VERSION ""

NS_ :

BS_:

BU_: WPC2 PSB SHVU_RR FCS vHS_B2 EMCU SLB GW_APSU GW_DLBCU RCM ARS CGW_CCU vDummy_HS_B GW_RLPSU ATS RLHV SGU PFSU GW_RRPSU ALBCU DSAU SWRC SHVU_FR RCS GW_DPSU BLTN_CAM SCM OHCL RWPC RRHV WPC HOD ASAU

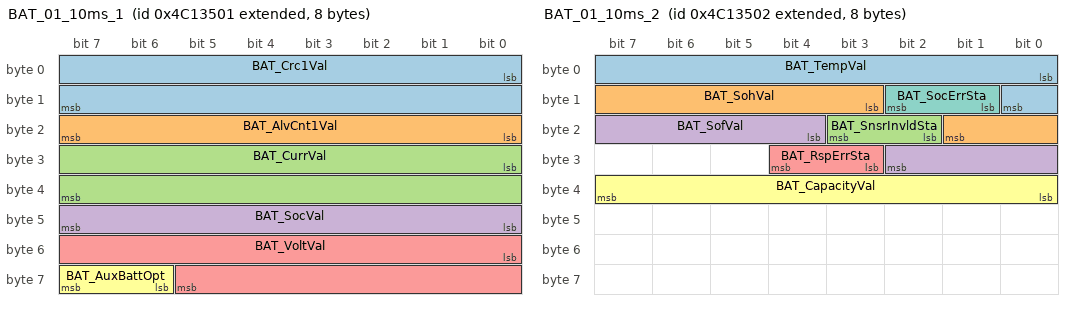
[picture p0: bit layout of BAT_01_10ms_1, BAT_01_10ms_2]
BO_ 2227254529 BAT_01_10ms_1: 8 CGW_CCU
 SG_ BAT_Crc1Val : 0|16@1+ (1,0) [0|0] "" Vector__XXX
 SG_ BAT_AlvCnt1Val : 16|8@1+ (1,0) [0|0] "" Vector__XXX
 SG_ BAT_CurrVal : 24|16@1+ (0.01,-327) [0|0] "A" Vector__XXX
 SG_ BAT_SocVal : 40|8@1+ (1,0) [0|0] "%"  BLTN_CAM
 SG_ BAT_VoltVal : 48|14@1+ (0.001,6) [0|0] "V" Vector__XXX
 SG_ BAT_AuxBattOpt : 62|2@1+ (1,0) [0|0] "" Vector__XXX

BO_ 2227254530 BAT_01_10ms_2: 8 CGW_CCU
 SG_ BAT_TempVal : 0|9@1+ (0.5,-40) [0|0] "¡É" Vector__XXX
 SG_ BAT_SohVal : 11|7@1+ (1,0) [0|0] "%" Vector__XXX
 SG_ BAT_SnsrInvldSta : 18|2@1+ (1,0) [0|0] "" Vector__XXX
 SG_ BAT_SofVal : 20|7@1+ (0.1,0) [0|0] "V" Vector__XXX
 SG_ BAT_RspErrSta : 27|2@1+ (1,0) [0|0] "" Vector__XXX
 SG_ BAT_CapacityVal : 32|8@1+ (1,0) [0|0] "" Vector__XXX
 SG_ BAT_SocErrSta : 9|2@1+ (1,0) [0|0] "" Vector__XXX

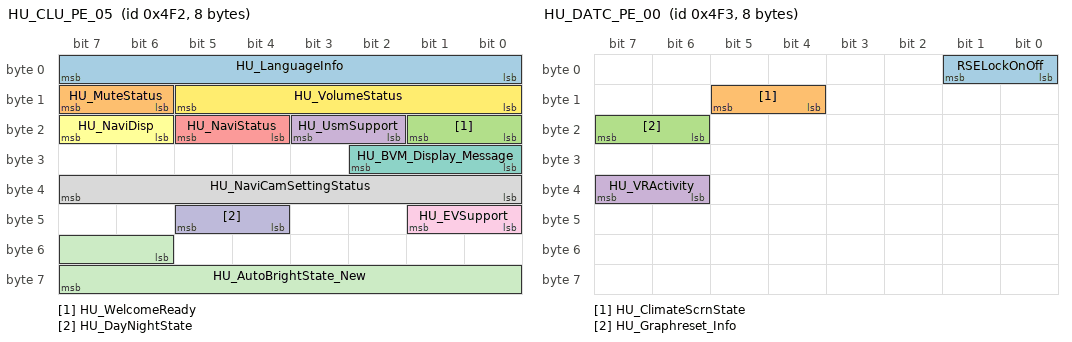
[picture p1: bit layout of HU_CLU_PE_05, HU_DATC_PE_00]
BO_ 1266 HU_CLU_PE_05: 8 CGW_CCU
 SG_ HU_LanguageInfo : 0|8@1+ (1,0) [0|0] ""  ATS,BLTN_CAM
 SG_ HU_MuteStatus : 14|2@1+ (1,0) [0|0] "" Vector__XXX
 SG_ HU_WelcomeReady : 16|2@1+ (1,0) [0|0] "" Vector__XXX
 SG_ HU_UsmSupport : 18|2@1+ (1,0) [0|0] "" Vector__XXX
 SG_ HU_NaviStatus : 20|2@1+ (1,0) [0|0] "" Vector__XXX
 SG_ HU_NaviDisp : 22|2@1+ (1,0) [0|0] "" Vector__XXX
 SG_ HU_BVM_Display_Message : 24|3@1+ (1,0) [0|0] "" Vector__XXX
 SG_ HU_NaviCamSettingStatus : 32|8@1+ (1,0) [0|0] "" Vector__XXX
 SG_ HU_EVSupport : 40|2@1+ (1,0) [0|0] "" Vector__XXX
 SG_ HU_DayNightState : 44|2@1+ (1,0) [0|0] "" Vector__XXX
 SG_ HU_AutoBrightState_New : 54|10@1+ (1,0) [0|0] "" Vector__XXX
 SG_ HU_VolumeStatus : 8|6@1+ (1,0) [0|0] "" Vector__XXX

BO_ 1267 HU_DATC_PE_00: 8 CGW_CCU
 SG_ RSELockOnOff : 0|2@1+ (1,0) [0|0] ""  ARS,ATS,GW_APSU
 SG_ HU_ClimateScrnState : 12|2@1+ (1,0) [0|0] "" Vector__XXX
 SG_ HU_Graphreset_Info : 22|2@1+ (1,0) [0|0] "" Vector__XXX
 SG_ HU_VRActivity : 38|2@1+ (1,0) [0|0] "" Vector__XXX

BO_ 191 RL_SHVU_03_200ms: 8 RLHV
 SG_ RL_SHVU_DTCdisplay : 0|8@1+ (1,0) [0|0] ""  ATS
 SG_ RL_SHVU_DiagMode : 8|2@1+ (1,0) [0|0] ""  ATS

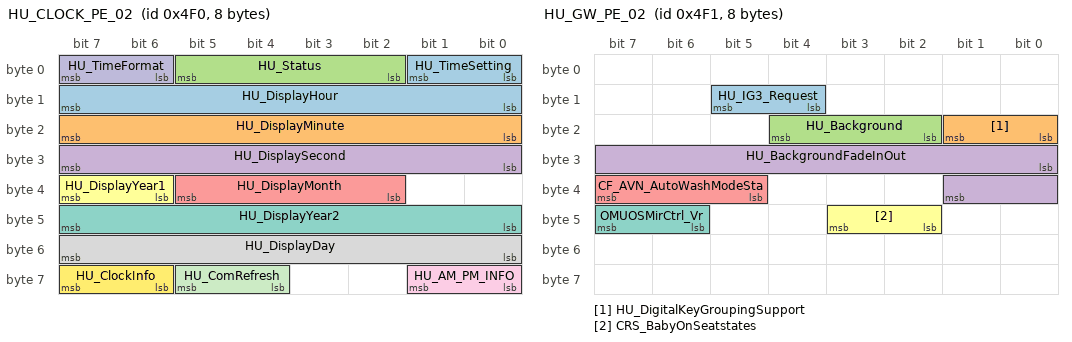
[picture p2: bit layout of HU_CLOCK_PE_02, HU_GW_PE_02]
BO_ 1264 HU_CLOCK_PE_02: 8 CGW_CCU
 SG_ HU_TimeSetting : 0|2@1+ (1,0) [0|0] ""  ATS,BLTN_CAM
 SG_ HU_DisplayMinute : 16|8@1+ (1,0) [0|0] ""  ATS,BLTN_CAM
 SG_ HU_Status : 2|4@1+ (1,0) [0|0] ""  ATS,BLTN_CAM
 SG_ HU_DisplaySecond : 24|8@1+ (1,0) [0|0] ""  ATS,BLTN_CAM
 SG_ HU_DisplayMonth : 34|4@1+ (1,0) [0|0] ""  ATS,BLTN_CAM
 SG_ HU_DisplayYear1 : 38|2@1+ (1,0) [0|0] ""  ATS,BLTN_CAM
 SG_ HU_DisplayYear2 : 40|8@1+ (1,0) [0|0] ""  ATS,BLTN_CAM
 SG_ HU_DisplayDay : 48|8@1+ (1,0) [0|0] ""  ATS,BLTN_CAM
 SG_ HU_AM_PM_INFO : 56|2@1+ (1,0) [0|0] ""  ATS,BLTN_CAM
 SG_ HU_TimeFormat : 6|2@1+ (1,0) [0|0] ""  ATS,BLTN_CAM
 SG_ HU_ComRefresh : 60|2@1+ (1,0) [0|0] ""  ATS,BLTN_CAM
 SG_ HU_ClockInfo : 62|2@1+ (1,0) [0|0] ""  ATS,BLTN_CAM
 SG_ HU_DisplayHour : 8|8@1+ (1,0) [0|0] ""  ATS,BLTN_CAM

BO_ 1265 HU_GW_PE_02: 8 CGW_CCU
 SG_ HU_IG3_Request : 12|2@1+ (1,0) [0|0] "" Vector__XXX
 SG_ HU_DigitalKeyGroupingSupport : 16|2@1+ (1,0) [0|0] "" Vector__XXX
 SG_ HU_Background : 18|3@1+ (1,0) [0|0] ""  ATS,BLTN_CAM
 SG_ HU_BackgroundFadeInOut : 24|10@1+ (0.1,0) [0|0] "%"  ATS,BLTN_CAM
 SG_ CF_AVN_AutoWashModeSta : 37|3@1+ (1,0) [0|0] "" Vector__XXX
 SG_ CRS_BabyOnSeatstates : 42|2@1+ (1,0) [0|0] "" Vector__XXX
 SG_ OMUOSMirCtrl_Vr : 46|2@1+ (1,0) [0|0] "" Vector__XXX

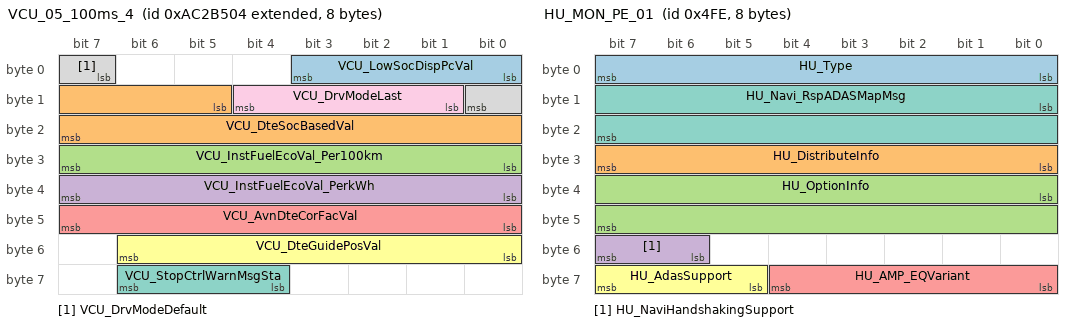
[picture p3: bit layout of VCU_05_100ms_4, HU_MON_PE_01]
BO_ 2328016132 VCU_05_100ms_4: 8 CGW_CCU
 SG_ VCU_LowSocDispPcVal : 0|4@1+ (1,0) [0|0] "" Vector__XXX
 SG_ VCU_DteSocBasedVal : 13|11@1+ (1,0) [0|0] "km" Vector__XXX
 SG_ VCU_InstFuelEcoVal_Per100km : 24|8@1+ (0.5,0) [0|126.5] "kWh/100km" Vector__XXX
 SG_ VCU_InstFuelEcoVal_PerkWh : 32|8@1+ (0.1,0) [0|25.5] "km/kWh" Vector__XXX
 SG_ VCU_AvnDteCorFacVal : 40|8@1+ (0.01,0) [0|0] "" Vector__XXX
 SG_ VCU_DteGuidePosVal : 48|7@1+ (1,-10) [0|0] "%" Vector__XXX
 SG_ VCU_StopCtrlWarnMsgSta : 60|3@1+ (1,0) [0|0] "" Vector__XXX
 SG_ VCU_DrvModeDefault : 7|2@1+ (1,0) [0|0] "" Vector__XXX
 SG_ VCU_DrvModeLast : 9|4@1+ (1,0) [0|0] "" Vector__XXX

BO_ 1278 HU_MON_PE_01: 8 CGW_CCU
 SG_ HU_Type : 0|8@1+ (1,0) [0|0] ""  BLTN_CAM
 SG_ HU_DistributeInfo : 24|8@1+ (1,0) [0|0] ""  BLTN_CAM
 SG_ HU_OptionInfo : 32|16@1+ (1,0) [0|0] ""  BLTN_CAM,RCM
 SG_ HU_NaviHandshakingSupport : 54|2@1+ (1,0) [0|0] "" Vector__XXX
 SG_ HU_AMP_EQVariant : 56|5@1+ (1,0) [0|0] "" Vector__XXX
 SG_ HU_AdasSupport : 61|3@1+ (1,0) [0|0] "" Vector__XXX
 SG_ HU_Navi_RspADASMapMsg : 8|16@1+ (1,0) [0|0] "" Vector__XXX

BO_ 1279 HU_USM_E_10: 8 CGW_CCU
 SG_ USM_SmartRegen_Map_Set : 11|2@1+ (1,0) [0|0] "" Vector__XXX
 SG_ USM_SmartRegen_Sens_Set : 13|3@1+ (1,0) [0|0] "" Vector__XXX
 SG_ AVN_SeatPosMemory_Btn : 16|3@1+ (1,0) [0|0] ""  GW_APSU,GW_DPSU,GW_RLPSU,GW_RRPSU
 SG_ AVN_SeatPosPlyBck_Btn : 19|3@1+ (1,0) [0|0] ""  GW_APSU,GW_DPSU,GW_RLPSU,GW_RRPSU
 SG_ USM_RhstaLvlEnaSetReq : 22|2@1+ (1,0) [0|0] "" Vector__XXX
 SG_ USM_CMSDayBrgtnsLvlLHSetReq : 24|4@1+ (1,0) [0|0] "" Vector__XXX
 SG_ USM_CMSNgtBrgtnsLvlLHSetReq : 28|4@1+ (1,0) [0|0] "" Vector__XXX
 SG_ USM_CMSDayBrgtnsLvlRHSetReq : 32|4@1+ (1,0) [0|0] "" Vector__XXX
 SG_ USM_CMSNgtBrgtnsLvlRHSetReq : 36|4@1+ (1,0) [0|0] "" Vector__XXX
 SG_ USM_CMSBrgtnsReset : 40|2@1+ (1,0) [0|0] "" Vector__XXX
 SG_ USM_TurnDistLnDispSetReq : 42|2@1+ (1,0) [0|0] "" Vector__XXX
 SG_ PCA_FrSd_NValueSet : 44|2@1+ (1,0) [0|0] "" Vector__XXX
 SG_ CF_AVN_1stRrStRmndNValueSet : 46|2@1+ (1,0) [0|0] "" Vector__XXX
 SG_ C_AllDrOpnNValueSet : 52|3@1+ (1,0) [0|0] "" Vector__XXX
 SG_ USM_RpmECOSet : 55|2@1+ (1,0) [0|0] "" Vector__XXX
 SG_ VESS_ChgGuideMdLvl : 57|3@1+ (1,0) [0|0] "" Vector__XXX
 SG_ Usm_RpmSPORTSet : 60|2@1+ (1,0) [0|0] "" Vector__XXX
 SG_ Usm_RpmSPORTPLUSSet : 62|2@1+ (1,0) [0|0] "" Vector__XXX

BO_ 2328016129 VCU_05_100ms_1: 8 CGW_CCU
 SG_ VCU_Crc5Val : 0|16@1+ (1,0) [0|0] "" Vector__XXX
 SG_ VCU_AlvCnt5Val : 16|8@1+ (1,0) [0|0] "" Vector__XXX
 SG_ VCU_EvDrvRdyCluDispSta : 24|2@1+ (1,0) [0|3] ""  SWRC
 SG_ VCU_PwrDnModeSta : 26|2@1+ (1,0) [0|3] "" Vector__XXX
 SG_ VCU_CluWarnMsgSta : 28|4@1+ (1,0) [0|15] "" Vector__XXX
 SG_ VCU_DteOffDispSta : 32|2@1+ (1,0) [0|0] "flag" Vector__XXX
 SG_ VCU_LowSocAlertSta : 34|3@1+ (1,0) [0|7] "" Vector__XXX
 SG_ VCU_VcrmReq : 38|2@1+ (1,0) [0|3] "" Vector__XXX
 SG_ VCU_PdlWarnMsgSta : 40|2@1+ (1,0) [0|3] "" Vector__XXX
 SG_ VCU_AwdDiagDispSta : 42|2@1+ (1,0) [0|0] "" Vector__XXX
 SG_ VCU_AwdLockDispSta : 44|2@1+ (1,0) [0|0] "" Vector__XXX
 SG_ VCU_VirtualApsActSta : 46|2@1+ (1,0) [0|3] "" Vector__XXX
 SG_ VCU_VirtualApsVal : 48|8@1+ (0.3906,0) [0|99.61] "%" Vector__XXX
 SG_ VCU_ServiceLampReq : 56|2@1+ (1,0) [0|3] "" Vector__XXX
 SG_ VCU_ServiceModeSta : 58|2@1+ (1,0) [0|3] "" Vector__XXX
 SG_ VCU_NPosWshModSta : 60|2@1+ (1,0) [0|0] "flag" Vector__XXX
 SG_ VCU_PowerTrainType : 62|2@1+ (1,0) [0|3] "" Vector__XXX

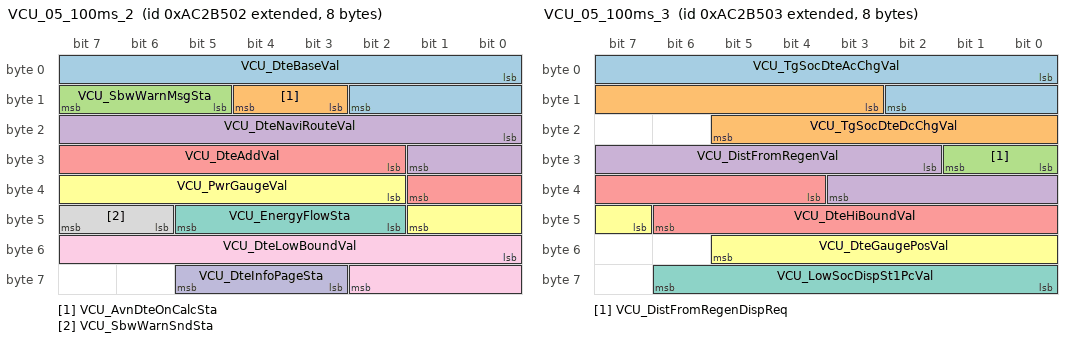
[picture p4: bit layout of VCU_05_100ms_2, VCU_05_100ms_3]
BO_ 2328016130 VCU_05_100ms_2: 8 CGW_CCU
 SG_ VCU_DteBaseVal : 0|11@1+ (1,0) [0|2047] "km" Vector__XXX
 SG_ VCU_AvnDteOnCalcSta : 11|2@1+ (1,0) [0|3] "" Vector__XXX
 SG_ VCU_SbwWarnMsgSta : 13|3@1+ (1,0) [0|0] "flag" Vector__XXX
 SG_ VCU_DteNaviRouteVal : 16|10@1+ (2,0) [0|1026] "km" Vector__XXX
 SG_ VCU_DteAddVal : 26|8@1+ (1,0) [0|255] "km" Vector__XXX
 SG_ VCU_PwrGaugeVal : 34|8@1- (1,0) [-100|100] "%" Vector__XXX
 SG_ VCU_EnergyFlowSta : 42|4@1+ (1,0) [0|15] "" Vector__XXX
 SG_ VCU_SbwWarnSndSta : 46|2@1+ (1,0) [0|0] "flag" Vector__XXX
 SG_ VCU_DteLowBoundVal : 48|11@1+ (1,0) [0|2047] "km" Vector__XXX
 SG_ VCU_DteInfoPageSta : 59|3@1+ (1,0) [0|0] "" Vector__XXX

BO_ 2328016131 VCU_05_100ms_3: 8 CGW_CCU
 SG_ VCU_TgSocDteAcChgVal : 0|11@1+ (1,0) [0|2047] "km" Vector__XXX
 SG_ VCU_TgSocDteDcChgVal : 11|11@1+ (1,0) [0|2047] "km" Vector__XXX
 SG_ VCU_DistFromRegenDispReq : 24|2@1+ (1,0) [0|3] "" Vector__XXX
 SG_ VCU_DistFromRegenVal : 26|10@1+ (10,0) [0|10230] "m" Vector__XXX
 SG_ VCU_DteHiBoundVal : 36|11@1+ (1,0) [0|2047] "km" Vector__XXX
 SG_ VCU_DteGaugePosVal : 47|7@1+ (1,-10) [0|0] "%" Vector__XXX
 SG_ VCU_LowSocDispSt1PcVal : 56|7@1+ (1,0) [0|100] "%" Vector__XXX

BO_ 200 HU_USM_E_12: 8 CGW_CCU
 SG_ CF_AVN_ADrLNValueSet_2 : 0|3@1+ (1,0) [0|0] "" Vector__XXX
 SG_ CF_AVN_FCA_JC_OnOffEquipNvalueSe : 12|2@1+ (1,0) [0|0] "" Vector__XXX
 SG_ CF_AVN_FCA_FrSdOnOffEquipNvalueS : 14|2@1+ (1,0) [0|0] "" Vector__XXX
 SG_ CF_AVN_LKA_OnOffEquip2NvalueSet : 16|2@1+ (1,0) [0|0] "" Vector__XXX
 SG_ CF_AVN_BCA_OnOffEquip2NvalueSet : 18|2@1+ (1,0) [0|0] "" Vector__XXX
 SG_ CF_AVN_BVM_OnOffEquipNvalueSet : 20|2@1+ (1,0) [0|0] "" Vector__XXX
 SG_ CF_AVN_SEA_OnOffEquip3NvalueSet : 22|2@1+ (1,0) [0|0] "" Vector__XXX
 SG_ CF_AVN_BodySpprtSet_AST : 24|2@1+ (1,0) [0|0] ""  ALBCU
 SG_ CF_AVN_SEW_OnOffEquip3NvalueSet : 26|2@1+ (1,0) [0|0] "" Vector__XXX
 SG_ CF_AVN_HudImsAutoSave : 28|2@1+ (1,0) [0|0] "" Vector__XXX
 SG_ USM_PwrDrBuzzerNValueSet : 3|2@1+ (1,0) [0|0] "" Vector__XXX
 SG_ CF_AVN_DWLNValueSet : 30|3@1+ (1,0) [0|0] "" Vector__XXX
 SG_ CF_AVN_AirSptTimeNValueSet_AST : 33|3@1+ (1,0) [0|0] ""  ALBCU
 SG_ CF_AVN_AirSptStrNValue_AST : 36|2@1+ (1,0) [0|0] ""  ALBCU
 SG_ CF_AVN_SeatDrvModNvalueSet_AST : 38|2@1+ (1,0) [0|0] ""  ALBCU
 SG_ CF_AVN_TPMS_TireReplaceNValueSet : 40|3@1+ (1,0) [0|0] "" Vector__XXX
 SG_ CF_AVN_TowModeSet : 43|3@1+ (1,0) [0|0] "" Vector__XXX
 SG_ USM_PwrDrCloseByBraekNValueSet : 46|2@1+ (1,0) [0|0] "" Vector__XXX
 SG_ CF_AVN_ISLANAOffstNvalueSet : 50|3@1+ (1,0) [0|0] "" Vector__XXX
 SG_ CF_Gway_WPC2_NValueSet : 53|2@1+ (1,0) [0|0] ""  WPC,WPC2
 SG_ USM_DrvGhostDoorReq : 56|2@1+ (1,0) [0|0] "" Vector__XXX
 SG_ USM_AstGhostDoorReq : 58|2@1+ (1,0) [0|0] "" Vector__XXX
 SG_ USM_RLGhostDoorReq : 60|2@1+ (1,0) [0|0] "" Vector__XXX
 SG_ USM_RRGhostDoorReq : 62|2@1+ (1,0) [0|0] "" Vector__XXX
 SG_ CF_AVN_FCA_FrOnOffEquipNvalueSet : 7|2@1+ (1,0) [0|0] "" Vector__XXX
 SG_ CF_AVN_FCA_WarnTimeNvalueSet : 9|3@1+ (1,0) [0|0] "" Vector__XXX

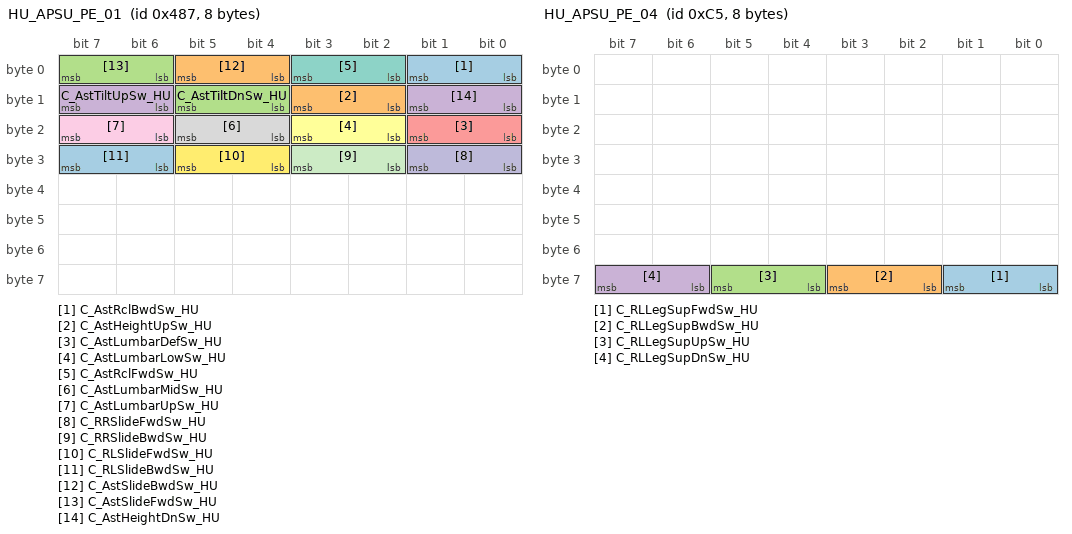
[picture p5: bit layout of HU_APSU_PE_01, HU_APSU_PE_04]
BO_ 1159 HU_APSU_PE_01: 8 CGW_CCU
 SG_ C_AstRclBwdSw_HU : 0|2@1+ (1,0) [0|0] ""  GW_APSU
 SG_ C_AstHeightUpSw_HU : 10|2@1+ (1,0) [0|0] ""  GW_APSU
 SG_ C_AstTiltDnSw_HU : 12|2@1+ (1,0) [0|0] ""  GW_APSU
 SG_ C_AstTiltUpSw_HU : 14|2@1+ (1,0) [0|0] ""  GW_APSU
 SG_ C_AstLumbarDefSw_HU : 16|2@1+ (1,0) [0|0] ""  ALBCU,ASAU,GW_APSU
 SG_ C_AstLumbarLowSw_HU : 18|2@1+ (1,0) [0|0] ""  ALBCU,ASAU,GW_APSU
 SG_ C_AstRclFwdSw_HU : 2|2@1+ (1,0) [0|0] ""  GW_APSU
 SG_ C_AstLumbarMidSw_HU : 20|2@1+ (1,0) [0|0] ""  ALBCU,ASAU,GW_APSU
 SG_ C_AstLumbarUpSw_HU : 22|2@1+ (1,0) [0|0] ""  ALBCU,ASAU,GW_APSU
 SG_ C_RRSlideFwdSw_HU : 24|2@1+ (1,0) [0|0] ""  GW_APSU,GW_RRPSU
 SG_ C_RRSlideBwdSw_HU : 26|2@1+ (1,0) [0|0] ""  GW_APSU,GW_RRPSU
 SG_ C_RLSlideFwdSw_HU : 28|2@1+ (1,0) [0|0] ""  GW_APSU,GW_RLPSU,GW_RRPSU
 SG_ C_RLSlideBwdSw_HU : 30|2@1+ (1,0) [0|0] ""  GW_APSU,GW_RLPSU,GW_RRPSU
 SG_ C_AstSlideBwdSw_HU : 4|2@1+ (1,0) [0|0] ""  GW_APSU
 SG_ C_AstSlideFwdSw_HU : 6|2@1+ (1,0) [0|0] ""  GW_APSU
 SG_ C_AstHeightDnSw_HU : 8|2@1+ (1,0) [0|0] ""  GW_APSU

BO_ 197 HU_APSU_PE_04: 8 CGW_CCU
 SG_ C_RLLegSupFwdSw_HU : 56|2@1+ (1,0) [0|0] ""  GW_APSU,GW_RLPSU
 SG_ C_RLLegSupBwdSw_HU : 58|2@1+ (1,0) [0|0] ""  GW_APSU,GW_RLPSU
 SG_ C_RLLegSupUpSw_HU : 60|2@1+ (1,0) [0|0] ""  GW_APSU,GW_RLPSU
 SG_ C_RLLegSupDnSw_HU : 62|2@1+ (1,0) [0|0] ""  GW_APSU,GW_RLPSU

BO_ 1165 RLMSS_02_500ms: 8 GW_RLPSU
 SG_ RLMSS_OnOffBtn_AVN : 0|2@1+ (1,0) [0|0] ""  CGW_CCU

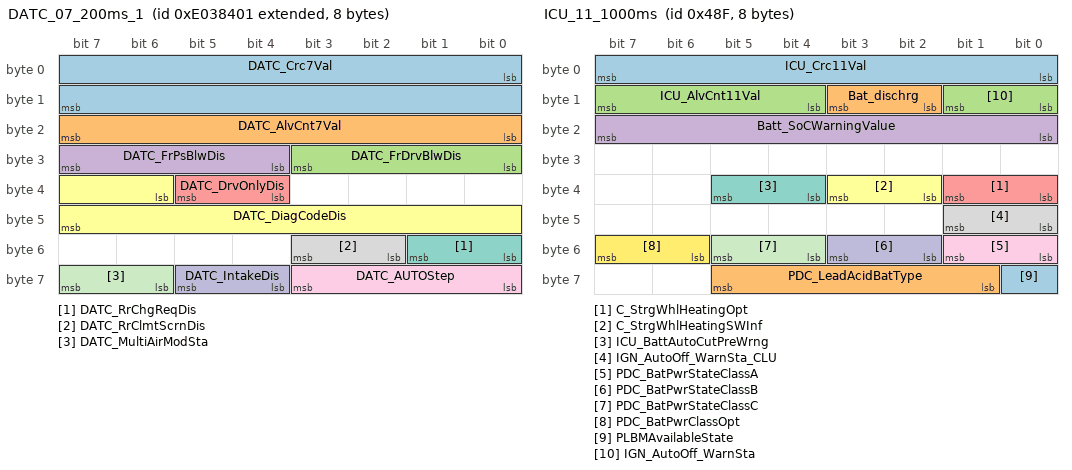
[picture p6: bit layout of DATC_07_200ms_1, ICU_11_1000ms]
BO_ 2382595073 DATC_07_200ms_1: 8 CGW_CCU
 SG_ DATC_Crc7Val : 0|16@1+ (1,0) [0|0] "" Vector__XXX
 SG_ DATC_AlvCnt7Val : 16|8@1+ (1,0) [0|0] "" Vector__XXX
 SG_ DATC_FrDrvBlwDis : 24|4@1+ (1,0) [0|0] ""  ATS
 SG_ DATC_FrPsBlwDis : 28|4@1+ (1,0) [0|0] ""  ATS
 SG_ DATC_DrvOnlyDis : 36|2@1+ (1,0) [0|0] ""  ATS
 SG_ DATC_DiagCodeDis : 38|10@1+ (1,-1) [0|0] "" Vector__XXX
 SG_ DATC_RrChgReqDis : 48|2@1+ (1,0) [0|0] "" Vector__XXX
 SG_ DATC_RrClmtScrnDis : 50|2@1+ (1,0) [0|0] ""  ATS
 SG_ DATC_AUTOStep : 56|4@1+ (1,0) [0|0] ""  ATS
 SG_ DATC_IntakeDis : 60|2@1+ (1,0) [0|0] ""  ATS
 SG_ DATC_MultiAirModSta : 62|2@1+ (1,0) [0|0] "" Vector__XXX

BO_ 1167 ICU_11_1000ms: 8 CGW_CCU
 SG_ ICU_Crc11Val : 0|8@1+ (1,0) [0|0] "" Vector__XXX
 SG_ Bat_dischrg : 10|2@1+ (1,0) [0|0] "" Vector__XXX
 SG_ ICU_AlvCnt11Val : 12|4@1+ (1,0) [0|0] "" Vector__XXX
 SG_ Batt_SoCWarningValue : 16|8@1+ (1,0) [0|0] "%" Vector__XXX
 SG_ C_StrgWhlHeatingOpt : 32|2@1+ (1,0) [0|0] "" Vector__XXX
 SG_ C_StrgWhlHeatingSWInf : 34|2@1+ (1,0) [0|0] "" Vector__XXX
 SG_ ICU_BattAutoCutPreWrng : 36|2@1+ (1,0) [0|0] ""  BLTN_CAM
 SG_ IGN_AutoOff_WarnSta_CLU : 40|2@1+ (1,0) [0|0] "" Vector__XXX
 SG_ PDC_BatPwrStateClassA : 48|2@1+ (1,0) [0|0] "" Vector__XXX
 SG_ PDC_BatPwrStateClassB : 50|2@1+ (1,0) [0|0] "" Vector__XXX
 SG_ PDC_BatPwrStateClassC : 52|2@1+ (1,0) [0|0] "" Vector__XXX
 SG_ PDC_BatPwrClassOpt : 54|2@1+ (1,0) [0|0] "" Vector__XXX
 SG_ PLBMAvailableState : 56|1@1+ (1,0) [0|0] "" Vector__XXX
 SG_ PDC_LeadAcidBatType : 57|5@1+ (1,0) [0|0] "" Vector__XXX
 SG_ IGN_AutoOff_WarnSta : 8|2@1+ (1,0) [0|0] "" Vector__XXX

BO_ 194 HU_USM_E_16: 8 CGW_CCU
 SG_ CF_LDW_OnOffEquip2NvalueSet : 0|2@1+ (1,0) [0|0] "" Vector__XXX
 SG_ CF_AVN_TrnkTlgtAutoWashModeSet : 12|2@1+ (1,0) [0|0] "" Vector__XXX
 SG_ CF_AVN_DrvArmRestHeatNValueSet : 14|2@1+ (1,0) [0|0] ""  FCS
 SG_ CF_AVN_AstArmRestHeatNValueSet : 16|2@1+ (1,0) [0|0] ""  FCS
 SG_ CF_AVN_RRArmRestHeatNValueSet : 18|2@1+ (1,0) [0|0] ""  FCS
 SG_ AVN_HudContentsADAS : 2|2@1+ (1,0) [0|0] "" Vector__XXX
 SG_ CF_AVN_RLArmRestHeatNValueSet : 20|2@1+ (1,0) [0|0] ""  FCS
 SG_ CF_AVN_AirSptStrNValue_VR : 22|2@1+ (1,0) [0|0] ""  GW_DLBCU
 SG_ CF_AVN_AirSptTimeNValueSet_VR : 24|3@1+ (1,0) [0|0] ""  GW_DLBCU
 SG_ CF_AVN_AirSptMode_VR : 27|3@1+ (1,0) [0|0] ""  GW_DLBCU
 SG_ CF_AVN_MdLmpSpeechRecogNValueSet : 30|3@1+ (1,0) [0|0] "" Vector__XXX
 SG_ AVN_HudContentsBCWUnderADAS : 4|2@1+ (1,0) [0|0] "" Vector__XXX
 SG_ CF_AVN_ISLA2NvalueSet : 41|3@1+ (1,0) [0|0] "" Vector__XXX
 SG_ C_TeleRRMsgOpCmdIBOX_0 : 44|2@1+ (1,0) [0|0] ""  GW_RRPSU
 SG_ C_TeleRLMsgOpCmdIBOX_0 : 46|2@1+ (1,0) [0|0] ""  GW_RLPSU
 SG_ USM_AdasISLANACntryTglSet : 48|2@1+ (1,0) [0|0] "" Vector__XXX
 SG_ USM_AdasISLANACntry1Set : 50|4@1+ (1,0) [0|0] "" Vector__XXX
 SG_ CF_AVN_PMPDNvalueSet : 54|2@1+ (1,0) [0|0] "" Vector__XXX
 SG_ CF_AVN_LKAWrngVolNvalueSet_2 : 56|2@1+ (1,0) [0|0] "" Vector__XXX
 SG_ CF_AVN_ActbolstersenNValue : 58|3@1+ (1,0) [0|0] ""  GW_DLBCU

BO_ 1166 RRMSS_02_500ms: 8 GW_RRPSU
 SG_ RRMSS_OnOffBtn_AVN : 0|2@1+ (1,0) [0|0] ""  CGW_CCU

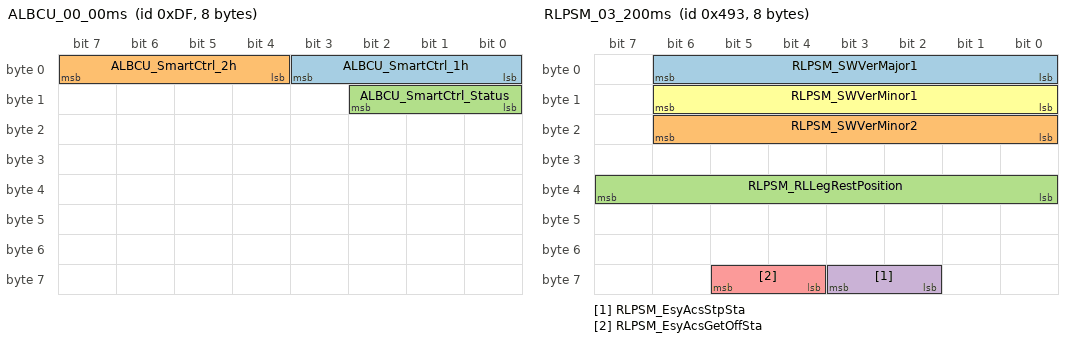
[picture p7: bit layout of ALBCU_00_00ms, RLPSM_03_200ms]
BO_ 223 ALBCU_00_00ms: 8 ALBCU
 SG_ ALBCU_SmartCtrl_1h : 0|4@1+ (1,0) [0|0] ""  CGW_CCU
 SG_ ALBCU_SmartCtrl_2h : 4|4@1+ (1,0) [0|0] ""  CGW_CCU
 SG_ ALBCU_SmartCtrl_Status : 8|3@1+ (1,0) [0|0] ""  CGW_CCU

BO_ 1171 RLPSM_03_200ms: 8 GW_RLPSU
 SG_ RLPSM_SWVerMajor1 : 0|7@1+ (1,0) [0|0] "" Vector__XXX
 SG_ RLPSM_SWVerMinor2 : 16|7@1+ (1,0) [0|0] "" Vector__XXX
 SG_ RLPSM_RLLegRestPosition : 32|8@1+ (1,0) [0|0] ""  GW_APSU,GW_DPSU
 SG_ RLPSM_EsyAcsStpSta : 58|2@1+ (1,0) [0|0] ""  GW_DLBCU
 SG_ RLPSM_EsyAcsGetOffSta : 60|2@1+ (1,0) [0|0] ""  GW_DLBCU
 SG_ RLPSM_SWVerMinor1 : 8|7@1+ (1,0) [0|0] "" Vector__XXX

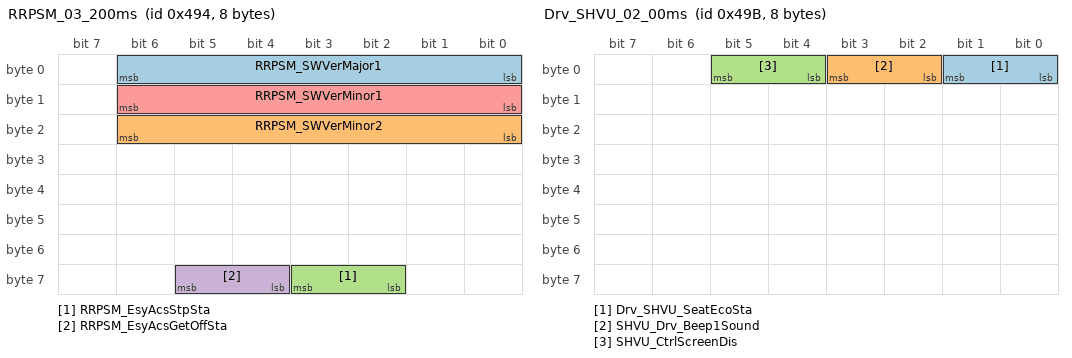
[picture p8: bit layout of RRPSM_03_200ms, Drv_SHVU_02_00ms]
BO_ 1172 RRPSM_03_200ms: 8 GW_RRPSU
 SG_ RRPSM_SWVerMajor1 : 0|7@1+ (1,0) [0|0] "" Vector__XXX
 SG_ RRPSM_SWVerMinor2 : 16|7@1+ (1,0) [0|0] "" Vector__XXX
 SG_ RRPSM_EsyAcsStpSta : 58|2@1+ (1,0) [0|0] ""  GW_DLBCU
 SG_ RRPSM_EsyAcsGetOffSta : 60|2@1+ (1,0) [0|0] ""  GW_DLBCU
 SG_ RRPSM_SWVerMinor1 : 8|7@1+ (1,0) [0|0] "" Vector__XXX

BO_ 1174 Drv_SHVU_01_200ms: 8 GW_APSU
 SG_ Drv_SHVU_SeatOptSta : 0|3@1+ (1,0) [0|0] ""  CGW_CCU,FCS
 SG_ Drv_SHVU_HtSwHiIndSta : 14|2@1+ (1,0) [0|0] ""  CGW_CCU,FCS
 SG_ Drv_SHVU_HtSwMidIndSta : 16|2@1+ (1,0) [0|0] ""  CGW_CCU,FCS
 SG_ Drv_SHVU_HtSwLowIndSta : 18|2@1+ (1,0) [0|0] ""  CGW_CCU,FCS
 SG_ Drv_SHVU_VntSwHiIndSta : 20|2@1+ (1,0) [0|0] ""  CGW_CCU,FCS
 SG_ Drv_SHVU_VntSwMidIndSta : 22|2@1+ (1,0) [0|0] ""  CGW_CCU,FCS
 SG_ Drv_SHVU_VntSwLowIndSta : 24|2@1+ (1,0) [0|0] ""  CGW_CCU,FCS
 SG_ Drv_SHVU_HtBlcUSMSta : 28|4@1+ (1,0) [0|0] ""  CGW_CCU
 SG_ Drv_SHVU_SeatHtOperSta : 3|4@1+ (1,0) [0|0] ""  CGW_CCU,FCS
 SG_ Drv_SHVU_LastModeOptSta : 40|2@1+ (1,0) [0|0] ""  CGW_CCU
 SG_ Drv_SHVU_HtSwHiIndSta_RHD : 46|2@1+ (1,0) [0|0] ""  CGW_CCU,FCS
 SG_ Drv_SHVU_HtSwMidIndSta_RHD : 48|2@1+ (1,0) [0|0] ""  CGW_CCU,FCS
 SG_ Drv_SHVU_HtSwLowIndSta_RHD : 50|2@1+ (1,0) [0|0] ""  CGW_CCU,FCS
 SG_ Drv_SHVU_VntSwHiIndSta_RHD : 52|2@1+ (1,0) [0|0] ""  CGW_CCU,FCS
 SG_ Drv_SHVU_VntSwMidIndSta_RHD : 54|2@1+ (1,0) [0|0] ""  CGW_CCU,FCS
 SG_ Drv_SHVU_VntSwLowIndSta_RHD : 56|2@1+ (1,0) [0|0] ""  CGW_CCU,FCS
 SG_ Drv_SHVU_HtBlcUSMSta_RHD : 60|4@1+ (1,0) [0|0] "" Vector__XXX

BO_ 1179 Drv_SHVU_02_00ms: 8 SHVU_FR
 SG_ Drv_SHVU_SeatEcoSta : 0|2@1+ (1,0) [0|0] ""  CGW_CCU
 SG_ SHVU_Drv_Beep1Sound : 2|2@1+ (1,0) [0|0] ""  CGW_CCU
 SG_ SHVU_CtrlScreenDis : 4|2@1+ (1,0) [0|0] ""  CGW_CCU

BO_ 1180 Ast_SHVU_02_00ms: 8 SHVU_FR
 SG_ SHVU_Ast_Beep1Sound : 2|2@1+ (1,0) [0|0] ""  CGW_CCU
 SG_ Ast_SHVU_SeatEcoSta : 26|2@1+ (1,0) [0|0] ""  CGW_CCU

BO_ 208 RR_SHVU_03_200ms: 8 RRHV
 SG_ RR_SHVU_DTCdisplay : 0|8@1+ (1,0) [0|0] ""  ATS
 SG_ RR_SHVU_DiagMode : 8|2@1+ (1,0) [0|0] ""  ATS

BO_ 1181 RL_SHVU_02_00ms: 8 SHVU_FR
 SG_ RL_SHVU_SeatEcoSta : 0|2@1+ (1,0) [0|0] ""  ATS,CGW_CCU,vHS_B2

BO_ 1182 RR_SHVU_02_00ms: 8 SHVU_RR
 SG_ RR_SHVU_SeatEcoSta : 0|2@1+ (1,0) [0|0] ""  ATS,CGW_CCU,vHS_B2

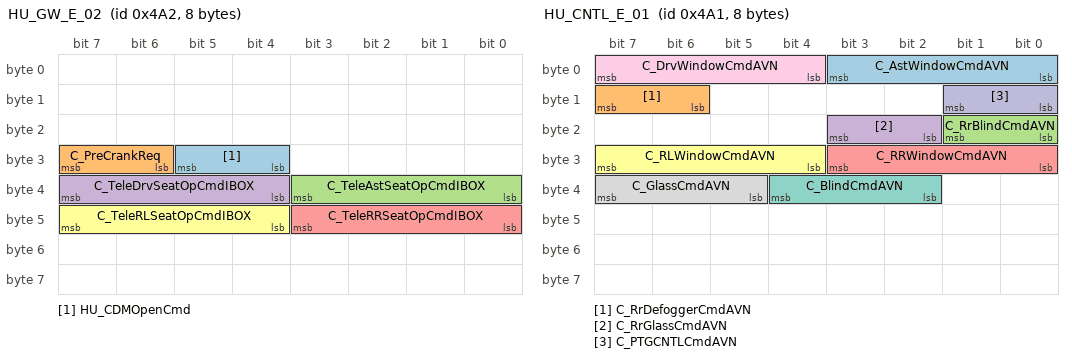
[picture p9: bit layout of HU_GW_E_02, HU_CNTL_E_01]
BO_ 1186 HU_GW_E_02: 8 CGW_CCU
 SG_ HU_CDMOpenCmd : 28|2@1+ (1,0) [0|0] "" Vector__XXX
 SG_ C_PreCrankReq : 30|2@1+ (1,0) [0|0] ""  BLTN_CAM
 SG_ C_TeleAstSeatOpCmdIBOX : 32|4@1+ (1,0) [0|0] ""  GW_APSU,SHVU_FR
 SG_ C_TeleDrvSeatOpCmdIBOX : 36|4@1+ (1,0) [0|0] ""  GW_APSU,GW_DPSU,SHVU_FR
 SG_ C_TeleRRSeatOpCmdIBOX : 40|4@1+ (1,0) [0|0] ""  ATS,GW_RRPSU,RRHV,SHVU_FR,SHVU_RR
 SG_ C_TeleRLSeatOpCmdIBOX : 44|4@1+ (1,0) [0|0] ""  ATS,GW_RLPSU,RLHV,SHVU_FR,SHVU_RR

BO_ 1185 HU_CNTL_E_01: 8 CGW_CCU
 SG_ C_AstWindowCmdAVN : 0|4@1+ (1,0) [0|0] "" Vector__XXX
 SG_ C_RrDefoggerCmdAVN : 14|2@1+ (1,0) [0|0] "" Vector__XXX
 SG_ C_RrBlindCmdAVN : 16|2@1+ (1,0) [0|0] ""  RCM
 SG_ C_RrGlassCmdAVN : 18|2@1+ (1,0) [0|0] ""  RCM
 SG_ C_RRWindowCmdAVN : 24|4@1+ (1,0) [0|0] "" Vector__XXX
 SG_ C_RLWindowCmdAVN : 28|4@1+ (1,0) [0|0] "" Vector__XXX
 SG_ C_BlindCmdAVN : 34|3@1+ (1,0) [0|0] ""  RCM
 SG_ C_GlassCmdAVN : 37|3@1+ (1,0) [0|0] ""  RCM
 SG_ C_DrvWindowCmdAVN : 4|4@1+ (1,0) [0|0] "" Vector__XXX
 SG_ C_PTGCNTLCmdAVN : 8|2@1+ (1,0) [0|0] "" Vector__XXX

BO_TX_BU_ 191 : RLHV,SHVU_FR,SHVU_RR;
BO_TX_BU_ 1174 : GW_APSU,GW_DPSU,SHVU_FR;
BO_TX_BU_ 1179 : SHVU_FR,GW_APSU;
BO_TX_BU_ 208 : RRHV,SHVU_FR,SHVU_RR;
BO_TX_BU_ 1181 : SHVU_FR,SHVU_RR,RLHV,GW_RLPSU;
BO_TX_BU_ 1182 : SHVU_RR,RRHV,GW_RRPSU,SHVU_FR;
CM_ BO_ 2227254529 "[P] Periodic";
CM_ SG_ 2227254529 BAT_Crc1Val "BAT_CyclicRedundancyCheck1Value";
CM_ SG_ 2227254529 BAT_AlvCnt1Val "BAT_AliveCounter1Value";
CM_ SG_ 2227254529 BAT_CurrVal "BAT_CurrentValue";
CM_ SG_ 2227254529 BAT_SocVal "BAT_StateOfChargeValue";
CM_ SG_ 2227254529 BAT_VoltVal "BAT_VoltageValue";
CM_ SG_ 2227254529 BAT_AuxBattOpt "12V Battery Option Value(LFP 12V Battery)";
CM_ BO_ 2227254530 "[P] Periodic";
CM_ SG_ 2227254530 BAT_TempVal "BAT_TemperatureValue";
CM_ SG_ 2227254530 BAT_SohVal "BAT_StateOfHealthValue";
CM_ SG_ 2227254530 BAT_SnsrInvldSta "BAT_SensorInvalidStatus";
CM_ SG_ 2227254530 BAT_SofVal "BAT_StateOfFunctionValue";
CM_ SG_ 2227254530 BAT_RspErrSta "BAT_ResponseErrorStatus";
CM_ SG_ 2227254530 BAT_CapacityVal "12V Battery Capacity Value";
CM_ SG_ 2227254530 BAT_SocErrSta "BAT_SoCErrorStatus";
CM_ BO_ 1266 "[PE] Periodic and On Event";
CM_ SG_ 1266 HU_LanguageInfo "Information for System Language (for Display Font)";
CM_ SG_ 1266 HU_MuteStatus "Information for System Mute Display";
CM_ SG_ 1266 HU_WelcomeReady "H/U playback ready signal to play welcome/goodbye animation video.";
CM_ SG_ 1266 HU_UsmSupport "Information whether HU can support USM or not";
CM_ SG_ 1266 HU_NaviStatus "Information for Navigation Status (Booting, Normal Operation, No SD card)
-AVN NAVI Transmission Signal";
CM_ SG_ 1266 HU_NaviDisp "Information for Navi Display status on Front Monitor";
CM_ SG_ 1266 HU_BVM_Display_Message "BVM Operation Message";
CM_ SG_ 1266 HU_NaviCamSettingStatus "Information for Navi Camera alert setting status

+ Bit-coded field (On 1, Off 0)
   - bit 0 : Fixed Camera
   - bit 1 : Signal/Speed Violation Camera
   - bit 2 : Movable Camera
   - bit 3 : User Registration Fixed Camera
   - bit 4 : User Registration Signal/Speed Violation Camera
   - bit 5~6 : RESERVED
-AVN NAVI Transmission Signal";
CM_ SG_ 1266 HU_EVSupport "Notification whether EV function support or not.";
CM_ SG_ 1266 HU_AutoBrightState_New "HU Display Brightness State(When automatically adjusted)";
CM_ SG_ 1266 HU_VolumeStatus "Information for AVN Volume";
CM_ BO_ 1267 "[PE] Periodic and On Event";
CM_ SG_ 1267 RSELockOnOff "Command for RSE Lock Requst from Head Unit";
CM_ SG_ 1267 HU_ClimateScrnState "AVNT Climate screen state";
CM_ SG_ 1267 HU_Graphreset_Info "Command for Hybrid Vehicle Fuel Economy Graph Reset Information
-Transmitting to Cluster when drivers agree 'Graph Reset'
-Keep the Value of Avergae Fuel Consumption and Line on the Graph";
CM_ SG_ 1267 HU_VRActivity "Information for Acitivity of VR (For All area)";
CM_ BO_ 191 "[PE] Periodic and On Event";
CM_ SG_ 191 RL_SHVU_DTCdisplay "0x00: DTC is not exist(Fail is not exist)/0x01:IGN2 Fuse Open Detection/0x02:Switch Input Detection at Same Time/0x03:NTC/Heating wire Open Detection/0x04:NTC+/NTC- Terminal Short Detection/0x05:NTC+/Heater+ Terminal Short Detection/0x06:NTC+/Heater-, Heater+/Heater-, Heater+/NTC- Terminal Short Detection/0x07:NTC+/Heater- Wiring Short Detection/0x08:NTC+/Heater-, Heater+/Heater-, Heater+/NTC- Wiring Short Detection/0x09:Target Temperature Dissatisfied/0x0A:Blower+/Blower- Short, Blower+/Blower Speed, Blower-/Blower Speed Wiring Short Detection/0x0B:Blower+/Blower RPM, Blower-/Blower RPM, Blower Speed/Blower RPM Short Detection/0x0C:Blower+, Blower-, Blower Speed Signal open Detection/0x0D:Blower RPM signal Open Detection/0x0E~0xFD:Unused/0xFE:No Display/0xFF:Invalid";
CM_ SG_ 191 RL_SHVU_DiagMode "0x0:Default/0x1:DTC Mode/0x2:Normal Mode/0x3:Invalid";
CM_ BO_ 1264 "[PE] Periodic and On Event";
CM_ SG_ 1264 HU_TimeSetting "Information for current time setting";
CM_ SG_ 1264 HU_DisplayMinute "Information for time display in Minute unit";
CM_ SG_ 1264 HU_Status "Information for H/U status
Transmitted on H/U status changing";
CM_ SG_ 1264 HU_DisplaySecond "Information for time display in Second unit";
CM_ SG_ 1264 HU_DisplayMonth "Information for Month";
CM_ SG_ 1264 HU_DisplayYear1 "Information for Year (XXOO)
XX : HU_DisplayYear1
OO: HU_DisplayYear2";
CM_ SG_ 1264 HU_DisplayYear2 "Information for Year (XXOO)
XX : HU_DisplayYear1
OO: HU_DisplayYear2";
CM_ SG_ 1264 HU_DisplayDay "Information for Day";
CM_ SG_ 1264 HU_AM_PM_INFO "Information for AM/PM";
CM_ SG_ 1264 HU_TimeFormat "Information for time format
Digital CLOCK only";
CM_ SG_ 1264 HU_DisplayHour "Information for time display in Hour unit";
CM_ BO_ 1265 "[PE] Periodic and On Event";
CM_ SG_ 1265 HU_IG3_Request "IG3 wake up and sleep request for EV/PHEV";
CM_ SG_ 1265 HU_DigitalKeyGroupingSupport "Digital Key Grouping Support";
CM_ SG_ 1265 HU_Background "HU Backgound image info";
CM_ SG_ 1265 HU_BackgroundFadeInOut "HU Background Fade in/out info - (HEX * Factor) %";
CM_ SG_ 1265 CRS_BabyOnSeatstates "The status of baby left in the car";
CM_ SG_ 1265 OMUOSMirCtrl_Vr "This signal is for the OutSide Mirror Control (Fold or Unfold)";
CM_ BO_ 2328016132 "[P] Periodic";
CM_ SG_ 2328016132 VCU_LowSocDispPcVal "VCU_LowSocDisplayPercentValue";
CM_ SG_ 2328016132 VCU_DteSocBasedVal "VCU_DteSocBasedValue";
CM_ SG_ 2328016132 VCU_InstFuelEcoVal_Per100km "VCU_InstantFuelEconomy(kWh/100km) ##2G##VCU - VCU5 - CR_Vcu_FuelEco_KP100km";
CM_ SG_ 2328016132 VCU_InstFuelEcoVal_PerkWh "VCU_InstantFuelEconomyValue_(km/kWh) ##2G##VCU - VCU5 - CR_Vcu_FuelEco_KPK";
CM_ SG_ 2328016132 VCU_AvnDteCorFacVal "AVN DTE Correlation Factor Value";
CM_ SG_ 2328016132 VCU_DteGuidePosVal "DTE Guide Position Value";
CM_ SG_ 2328016132 VCU_StopCtrlWarnMsgSta "i-Pedal Warning Message Status";
CM_ SG_ 2328016132 VCU_DrvModeDefault "Drive Mode(Default Mode) Value for Cluster Display(EV)";
CM_ SG_ 2328016132 VCU_DrvModeLast "This signal is the drive mode that needs to maintain on restart";
CM_ BO_ 1278 "[PE] Periodic and On Event";
CM_ SG_ 1278 HU_Type "Information for H/U Platform type
- Integrated AVN 1.0 use different value depends on development company (Mobis:0x68/LG:0x70)
- Integrated AVN 1.0 Mobis is developed based on Display Audio
- Integrated AVN 1.0 LG is developed based on Compact AVN

Information for China OPIO Platform
- 0xFC: China OPIO w/o CLU interface (most of phase1)
- 0xFD: China OPIO w/CLU interface (parts of phase1, phase2)

Information for Audio Platform Type
- 0x43 : Audio 4.0 Value";
CM_ SG_ 1278 HU_DistributeInfo "Region :Europe/North America/
Vehicle Type : RHD/LHD
Positionning information";
CM_ SG_ 1278 HU_OptionInfo "Information of H/U functions";
CM_ SG_ 1278 HU_NaviHandshakingSupport "This is a signal to send whether handshaking logic is applied related to Navigation's 'Map based ADAS' specification";
CM_ SG_ 1278 HU_AMP_EQVariant "Set EQ Variant for various vehicle cases.
During the AMP initializing process, This signal should be sent before AMP unmute.
This signal is only needed for models that have variant EQ for vehicle types. (Hatchback, Wagon, Hybrid etc..)
Models that doesn¡¯t have variant EQ for vehicle types shouldn¡¯t have this signal.";
CM_ SG_ 1278 HU_AdasSupport "Information about ADAS support
-Classify between General Map and Precise Map Transmission Function
-AVN System Transmission Signal";
CM_ SG_ 1278 HU_Navi_RspADASMapMsg "HU_ResponseADASMapMessage";
CM_ BO_ 1279 "[EC] On Event and On Change";
CM_ SG_ 1279 USM_SmartRegen_Map_Set "Smart Regeneration 2.0 Map information USM User set signal";
CM_ SG_ 1279 USM_SmartRegen_Sens_Set "Smart Regeneration User Personality of Reduction Set Signal";
CM_ SG_ 1279 AVN_SeatPosMemory_Btn "Seat position save signal";
CM_ SG_ 1279 AVN_SeatPosPlyBck_Btn "Seat position move signal";
CM_ SG_ 1279 USM_CMSBrgtnsReset "CMS Brightness Reset (LH/RH)";
CM_ SG_ 1279 CF_AVN_1stRrStRmndNValueSet "This signal is for setting the ROA function when IBU control ROA Function.";
CM_ SG_ 1279 VESS_ChgGuideMdLvl "Releated to VESS Alarm Sound Level";
CM_ BO_ 2328016129 "[P] Periodic";
CM_ SG_ 2328016129 VCU_Crc5Val "VCU_CyclicRedundancyCheck5Value";
CM_ SG_ 2328016129 VCU_AlvCnt5Val "VCU_AliveCounter5Value";
CM_ SG_ 2328016129 VCU_EvDrvRdyCluDispSta "VCU_EvDriveReadyClusterDisplayStatus ##2G##VCU - VCU1 - CF_Vcu_EvRdyClu";
CM_ SG_ 2328016129 VCU_PwrDnModeSta "VCU_PowerDownModeStatus ##2G##VCU - VCU5 - CF_Vcu_PwrDnMode";
CM_ SG_ 2328016129 VCU_CluWarnMsgSta "VCU_ClusterWarningMessageStatus ##2G##VCU - VCU7 - CF_Vcu_WarnMsg";
CM_ SG_ 2328016129 VCU_DteOffDispSta "VCU_DteOffDisplayStatus ##2G##VCU - VCU5 - CF_Vcu_DteOff";
CM_ SG_ 2328016129 VCU_LowSocAlertSta "VCU_LowSocAlertStatus ##2G##VCU - VCU3 - CF_Vcu_LowSocAlert";
CM_ SG_ 2328016129 VCU_VcrmReq "VCU_VcrmRequest ##2G##VCU - VCU3 - CF_Vcu_Vcrm_Req";
CM_ SG_ 2328016129 VCU_PdlWarnMsgSta "VCU_PaddleWarningMassageStatus";
CM_ SG_ 2328016129 VCU_AwdDiagDispSta "VCU_AwdDiagnosisDisplayStatus";
CM_ SG_ 2328016129 VCU_AwdLockDispSta "VCU_AwdLockDisplayStatus";
CM_ SG_ 2328016129 VCU_VirtualApsActSta "VCU_VirtualApsActivatedStatus ##2G##VCU - VCU1 - CF_Vcu_EstApsSel";
CM_ SG_ 2328016129 VCU_VirtualApsVal "VCU_VirtualApsValue ##2G##VCU - VCU1 - CR_Vcu_EstAccPed_PC";
CM_ SG_ 2328016129 VCU_ServiceLampReq "VCU_SeviceLampRequest ##2G##VCU - VCU5 - CF_Vcu_SerLamp";
CM_ SG_ 2328016129 VCU_ServiceModeSta "VCU_ServiceModeStatus ##2G##VCU - VCU2 - CF_Vcu_ServiceMod";
CM_ SG_ 2328016129 VCU_NPosWshModSta "VCU_NPositionWashModeStatus";
CM_ SG_ 2328016129 VCU_PowerTrainType "VCU_PowerTrainType";
CM_ BO_ 2328016130 "[P] Periodic";
CM_ SG_ 2328016130 VCU_DteBaseVal "VCU_DteBaseValue ##2G##VCU - VCU1 - CR_Vcu_DistEmpty_km(VCU6 - CR_Vcu_DistEmpty_km)";
CM_ SG_ 2328016130 VCU_AvnDteOnCalcSta "VCU_AvnDteOnCalculationStatus ##2G##VCU - VCU1 - CF_Vcu_AvnDteCalc(VCU6 - CF_Vcu_AvnDteCalc)";
CM_ SG_ 2328016130 VCU_SbwWarnMsgSta "VCU_SbwWarningMessageStatus ##2G##VCU - VCU20 - CF_Vcu_SbwWarnMsg";
CM_ SG_ 2328016130 VCU_DteNaviRouteVal "VCU_DteNaviRouteValue ##2G##VCU - VCU3 - CR_Vcu_DistEmptyAvn_km";
CM_ SG_ 2328016130 VCU_DteAddVal "VCU_DteAddedValue ##2G##VCU - VCU1 - CR_Vcu_DistEmptyAdd_km(VCU6 - CR_Vcu_DistEmptyAdd_km)";
CM_ SG_ 2328016130 VCU_PwrGaugeVal "VCU_PowerGaugeValue ##2G##VCU - VCU5 - CR_Vcu_TqMotClu_Pc";
CM_ SG_ 2328016130 VCU_EnergyFlowSta "VCU_EnergyFlowStatus ##2G##VCU - VCU5 - CF_Vcu_EvMod";
CM_ SG_ 2328016130 VCU_SbwWarnSndSta "VCU_SbwWarningSoundStatus ##2G##VCU - VCU20 - CF_Vcu_SbwWarnSnd";
CM_ SG_ 2328016130 VCU_DteLowBoundVal "DTE Low Boundary Value";
CM_ SG_ 2328016130 VCU_DteInfoPageSta "DTE Information Page State";
CM_ BO_ 2328016131 "[P] Periodic";
CM_ SG_ 2328016131 VCU_TgSocDteAcChgVal "VCU_TargetSocDte(Sc/Ac)ChargerValue ##2G##VCU - VCU19 - CR_Vcu_TgSocDte_AcChg";
CM_ SG_ 2328016131 VCU_TgSocDteDcChgVal "VCU_TargetSocDte(Qc/Dc)ChargerValue ##2G##VCU - VCU19 - CR_Vcu_TgSocDte_DcChg";
CM_ SG_ 2328016131 VCU_DistFromRegenDispReq "VCU_DistanceFromRegenerationDisplayRequest ##2G##VCU - VCU7 - CR_Vcu_RegenRangeAddSet";
CM_ SG_ 2328016131 VCU_DistFromRegenVal "VCU_DistanceFromRegenerationValue ##2G##VCU - VCU7 - CR_Vcu_RegenRangeAdd";
CM_ SG_ 2328016131 VCU_DteHiBoundVal "DTE High Boundary Value";
CM_ SG_ 2328016131 VCU_DteGaugePosVal "DTE Gauge Position Value";
CM_ SG_ 2328016131 VCU_LowSocDispSt1PcVal "VCU_LowSocDispState1PcVal (0~100%)";
CM_ BO_ 200 "[EC] On Event and On Change";
CM_ SG_ 200 CF_AVN_BodySpprtSet_AST "This signal is for the Ergo-Motion seat (AST) body support (Smart Posture Assist) USM";
CM_ SG_ 200 CF_AVN_AirSptTimeNValueSet_AST "This signal is for the Ergo-Motion seat (AST) massage function time setting";
CM_ SG_ 200 CF_AVN_AirSptStrNValue_AST "This signal is for the ERGO seat (AST) massage intensity USM";
CM_ SG_ 200 CF_AVN_SeatDrvModNvalueSet_AST "This signal is for the Ergo-Motion seat (AST) smart support (Smart Support) USM";
CM_ BO_ 1159 "[PE] Periodic and On Event";
CM_ SG_ 1159 C_AstRclBwdSw_HU "Assistant seat Moving control :Recline Backward";
CM_ SG_ 1159 C_AstHeightUpSw_HU "Assistant seat Moving control : Height Up";
CM_ SG_ 1159 C_AstTiltDnSw_HU "Assistant seat Moving control : Tilt Down";
CM_ SG_ 1159 C_AstTiltUpSw_HU "Assistant seat Moving Switch : Tilt Up";
CM_ SG_ 1159 C_AstLumbarDefSw_HU "Assistant seat moving switch: Deflate";
CM_ SG_ 1159 C_AstLumbarLowSw_HU "Assistant seat moving switch:Lumbar Low";
CM_ SG_ 1159 C_AstRclFwdSw_HU "Assistant seat Moving Switch : Recline Forward";
CM_ SG_ 1159 C_AstLumbarMidSw_HU "Assistant seat Moving control : Lumbar Mid";
CM_ SG_ 1159 C_AstLumbarUpSw_HU "Assistant seat Moving control : Lumbar Up";
CM_ SG_ 1159 C_RRSlideFwdSw_HU "2nd Right side seat Moving control :Power Slide Forward";
CM_ SG_ 1159 C_RRSlideBwdSw_HU "2nd Right side seat Moving control :Power Slide Backward";
CM_ SG_ 1159 C_RLSlideFwdSw_HU "2nd Left side seat Moving control :Power Slide Forward";
CM_ SG_ 1159 C_RLSlideBwdSw_HU "2nd Left side seat Moving control :Power Slide Backward";
CM_ SG_ 1159 C_AstSlideBwdSw_HU "Assistant seat moving switch : Slide Backward";
CM_ SG_ 1159 C_AstSlideFwdSw_HU "Assistant seat Moving switch : Slide Forward";
CM_ SG_ 1159 C_AstHeightDnSw_HU "Assistant seat Moving control : Height Down";
CM_ BO_ 197 "[PE] Periodic and On Event";
CM_ SG_ 197 C_RLLegSupFwdSw_HU "2nd Left side seat Moving control : Leg Support Forward";
CM_ SG_ 197 C_RLLegSupBwdSw_HU "2nd Left side seat Moving control : Leg Support Backward";
CM_ SG_ 197 C_RLLegSupUpSw_HU "2nd Left side seat Moving control : Leg Support Up";
CM_ SG_ 197 C_RLLegSupDnSw_HU "2nd Left side seat Moving control : Leg Support Down";
CM_ BO_ 1165 "[PE] Periodic and On Event";
CM_ SG_ 1165 RLMSS_OnOffBtn_AVN "Massage Switch Power On Off Signal to AVN";
CM_ BO_ 2382595073 "[PE] Periodic and On Event";
CM_ SG_ 2382595073 DATC_Crc7Val "DATC_CyclicRedundancyCheck7Value";
CM_ SG_ 2382595073 DATC_AlvCnt7Val "DATC_AliveCounter7Value";
CM_ SG_ 2382595073 DATC_FrDrvBlwDis "DATC_FrontDriverBlowerDisplay";
CM_ SG_ 2382595073 DATC_FrPsBlwDis "DATC_FrontPassengerBlowerDisplay";
CM_ SG_ 2382595073 DATC_DrvOnlyDis "DATC_DriverOnlyDisplay";
CM_ SG_ 2382595073 DATC_DiagCodeDis "DATC_DiagnosisCodeDisplay";
CM_ SG_ 2382595073 DATC_RrChgReqDis "DATC_RearChangeRequestDisplay";
CM_ SG_ 2382595073 DATC_RrClmtScrnDis "DATC_RearClimateScreenDisplay";
CM_ SG_ 2382595073 DATC_AUTOStep "This signal indicates AUTO step status in case Multi Auto Blower type.";
CM_ SG_ 2382595073 DATC_IntakeDis "This signal indicates intake indicator & display";
CM_ SG_ 2382595073 DATC_MultiAirModSta "This signal indicates MultiAirModeStatus";
CM_ BO_ 1167 "[PE] Periodic and On Event";
CM_ SG_ 1167 ICU_Crc11Val "ICU_CyclicRedundancyCheck11Value";
CM_ SG_ 1167 Bat_dischrg "Battery discharge notification flag #2G# Bat_dischrg";
CM_ SG_ 1167 ICU_AlvCnt11Val "ICU_AliveCounter11Value";
CM_ SG_ 1167 Batt_SoCWarningValue "Value of SoC warning level. ##2G## -  - Batt_SoCWarningValue";
CM_ SG_ 1167 ICU_BattAutoCutPreWrng "This is a warning signal before blocking the dark current of the ICU by the battery SOC.";
CM_ SG_ 1167 IGN_AutoOff_WarnSta_CLU "this signal is defined as the warning signal related with battery discharge";
CM_ SG_ 1167 PDC_BatPwrStateClassA "Vehicle Low-Voltage Power State Class A";
CM_ SG_ 1167 PDC_BatPwrStateClassB "Vehicle Low-Voltage Power State Class  B";
CM_ SG_ 1167 PDC_BatPwrStateClassC "Vehicle Low-Voltage Power State Class  C";
CM_ SG_ 1167 PDC_LeadAcidBatType "Lead Acid Battery Type Information";
CM_ SG_ 1167 IGN_AutoOff_WarnSta "this signal is defined as the warning signal related with battery discharge";
CM_ BO_ 194 "[EC] On Event and On Change";
CM_ SG_ 194 CF_AVN_AirSptStrNValue_VR "This signal is for the seat massage intensity VR";
CM_ SG_ 194 CF_AVN_AirSptTimeNValueSet_VR "This signal is for the seat massage function time setting by VR";
CM_ SG_ 194 CF_AVN_AirSptMode_VR "This signal is for the seat massage function mode setting by VR";
CM_ SG_ 194 CF_AVN_MdLmpSpeechRecogNValueSet "Signal of mood lamp position when VR is started";
CM_ SG_ 194 C_TeleRRMsgOpCmdIBOX_0 "Seat massage System RR On/Off";
CM_ SG_ 194 C_TeleRLMsgOpCmdIBOX_0 "Seat Massage System RL On/Off";
CM_ BO_ 1166 "[PE] Periodic and On Event";
CM_ SG_ 1166 RRMSS_OnOffBtn_AVN "Massage Switch Power On Off Signal to AVN";
CM_ BO_ 223 "[EC] On Event and On Change";
CM_ SG_ 223 ALBCU_SmartCtrl_1h "Smart Posture Adjust 1hr";
CM_ SG_ 223 ALBCU_SmartCtrl_2h "Smart Posture Adjust AVN Display (2hr)";
CM_ SG_ 223 ALBCU_SmartCtrl_Status "Smart Posture Adjust 2nd Interlocked Move AVN popup request";
CM_ BO_ 1171 "[PE] Periodic and On Event";
CM_ SG_ 1171 RLPSM_SWVerMajor1 "First Word(ASCII) in RLPSM S/W Ver";
CM_ SG_ 1171 RLPSM_SWVerMinor2 "Third Word(ASCII) in RLPSM S/W Ver";
CM_ SG_ 1171 RLPSM_EsyAcsStpSta "EasyAccessStop from RLPSM to DLBCU";
CM_ SG_ 1171 RLPSM_EsyAcsGetOffSta "EasyAccessGetOff from RLPSM to DLBCU";
CM_ SG_ 1171 RLPSM_SWVerMinor1 "Second Word(ASCII) in RLPSM S/W Ver";
CM_ BO_ 1172 "[PE] Periodic and On Event";
CM_ SG_ 1172 RRPSM_SWVerMajor1 "First Word(ASCII) in RRPSM S/W Ver";
CM_ SG_ 1172 RRPSM_SWVerMinor2 "Third Word(ASCII) in RRPSM S/W Ver";
CM_ SG_ 1172 RRPSM_EsyAcsStpSta "EasyAccessStop from RRPSM to DLBCU";
CM_ SG_ 1172 RRPSM_EsyAcsGetOffSta "EasyAccessGetOff from RRPSM to DLBCU";
CM_ SG_ 1172 RRPSM_SWVerMinor1 "Second Word(ASCII) in RRPSM S/W Ver";
CM_ BO_ 1174 "[PE] Periodic and On Event";
CM_ SG_ 1174 Drv_SHVU_SeatOptSta "Drv Seat Heater/Vent option info";
CM_ SG_ 1174 Drv_SHVU_HtSwHiIndSta "Drv Seat Heater Switch High Indicator Status";
CM_ SG_ 1174 Drv_SHVU_HtSwMidIndSta "Drv Seat Heater Switch Mid Indicator Status";
CM_ SG_ 1174 Drv_SHVU_HtSwLowIndSta "Drv Seat Heater Switch Low Indicator Status";
CM_ SG_ 1174 Drv_SHVU_VntSwHiIndSta "Drv Seat Vent Switch High Indicator Status";
CM_ SG_ 1174 Drv_SHVU_VntSwMidIndSta "Drv Seat Vent Switch Mid Indicator Status";
CM_ SG_ 1174 Drv_SHVU_VntSwLowIndSta "Drv Seat Vent Switch Low Indicator Status";
CM_ SG_ 1174 Drv_SHVU_HtBlcUSMSta "Hetaer Balance Driver USM R vaule";
CM_ SG_ 1174 Drv_SHVU_SeatHtOperSta "Drv Seat Heater/Vent current operation state";
CM_ SG_ 1174 Drv_SHVU_LastModeOptSta "Drv Seat Heat/Vent Last Mode Option State";
CM_ SG_ 1174 Drv_SHVU_HtSwHiIndSta_RHD "Drv Seat Heater Switch High Indicator Status(RHD)";
CM_ SG_ 1174 Drv_SHVU_HtSwMidIndSta_RHD "Drv Seat Heater Switch Mid Indicator Status(RHD)";
CM_ SG_ 1174 Drv_SHVU_HtSwLowIndSta_RHD "Drv Seat Heater Switch Low Indicator Status(RHD)";
CM_ SG_ 1174 Drv_SHVU_VntSwHiIndSta_RHD "Drv Seat Vent Switch High Indicator Status(RHD)";
CM_ SG_ 1174 Drv_SHVU_VntSwMidIndSta_RHD "Drv Seat Vent Switch Mid Indicator Status(RHD)";
CM_ SG_ 1174 Drv_SHVU_VntSwLowIndSta_RHD "Drv Seat Vent Switch Low Indicator Status(RHD)";
CM_ SG_ 1174 Drv_SHVU_HtBlcUSMSta_RHD "Hetaer Balance Driver USM R vaule(RHD)";
CM_ BO_ 1179 "[EC] On Event and On Change";
CM_ SG_ 1179 Drv_SHVU_SeatEcoSta "Driver Seat Eco+ Mode Status";
CM_ SG_ 1179 SHVU_Drv_Beep1Sound "SHVU_FR Driver's Seat Heater or Ventilation Switch input Beep Request";
CM_ SG_ 1179 SHVU_CtrlScreenDis "Request AVN screen change for controlling Seat Heater or Ventilation";
CM_ BO_ 1180 "[EC] On Event and On Change";
CM_ SG_ 1180 SHVU_Ast_Beep1Sound "SHVU_FR Assistant's Seat Heater or Ventilation Switch input Beep Request";
CM_ SG_ 1180 Ast_SHVU_SeatEcoSta "Assistant (Passenger) Seat Eco+ Mode Status";
CM_ BO_ 208 "[PE] Periodic and On Event";
CM_ SG_ 208 RR_SHVU_DTCdisplay "0x00: DTC is not exist(Fail is not exist)/0x01:IGN2 Fuse Open Detection/0x02:Switch Input Detection at Same Time/0x03:NTC/Heating wire Open Detection/0x04:NTC+/NTC- Terminal Short Detection/0x05:NTC+/Heater+ Terminal Short Detection/0x06:NTC+/Heater-, Heater+/Heater-, Heater+/NTC- Terminal Short Detection/0x07:NTC+/Heater- Wiring Short Detection/0x08:NTC+/Heater-, Heater+/Heater-, Heater+/NTC- Wiring Short Detection/0x09:Target Temperature Dissatisfied/0x0A:Blower+/Blower- Short, Blower+/Blower Speed, Blower-/Blower Speed Wiring Short Detection/0x0B:Blower+/Blower RPM, Blower-/Blower RPM, Blower Speed/Blower RPM Short Detection/0x0C:Blower+, Blower-, Blower Speed Signal open Detection/0x0D:Blower RPM signal Open Detection/0x0E~0xFD:Unused/0xFE:No Display/0xFF:Invalid";
CM_ SG_ 208 RR_SHVU_DiagMode "0x0:Default/0x1:DTC Mode/0x2:Normal Mode/0x3:Invalid";
CM_ BO_ 1181 "[EC] On Event and On Change";
CM_ SG_ 1181 RL_SHVU_SeatEcoSta "Rear LH Seat Eco+ Mode Status";
CM_ BO_ 1182 "[EC] On Event and On Change";
CM_ SG_ 1182 RR_SHVU_SeatEcoSta "Rear RH Seat Eco+ Mode Status";
CM_ BO_ 1186 "[EC] On Event and On Change";
CM_ SG_ 1186 HU_CDMOpenCmd "Command for CDM open/close";
CM_ SG_ 1186 C_PreCrankReq "Command for B-CAN wake up signal
(Need to send this signal before other remote commands)";
CM_ SG_ 1186 C_TeleAstSeatOpCmdIBOX "Command for Remote Seat Heat/Vent control (Passenger)";
CM_ SG_ 1186 C_TeleDrvSeatOpCmdIBOX "Command for Remote Seat Heat/Vent control (Driver)";
CM_ SG_ 1186 C_TeleRRSeatOpCmdIBOX "Command for Remote Seat Heat/Vent control (Rear Right)";
CM_ SG_ 1186 C_TeleRLSeatOpCmdIBOX "Command for Remote Seat Heat/Vent control (Rear Left)";
CM_ BO_ 1185 "[EC] On Event and On Change";
CM_ SG_ 1185 C_AstWindowCmdAVN "This signal indicates AST Window Open/Close Command";
CM_ SG_ 1185 C_RrDefoggerCmdAVN "This signal indicates Rear Defogger Button Command";
CM_ SG_ 1185 C_RRWindowCmdAVN "This signal indicates RR Window Open/Close Command";
CM_ SG_ 1185 C_RLWindowCmdAVN "This signal indicates RL Window Open/Close Command";
CM_ SG_ 1185 C_BlindCmdAVN "This signal indicates Sunroof Blind Open/Close Command";
CM_ SG_ 1185 C_GlassCmdAVN "This signal indicates Sunroof Glass Open/Close Command";
CM_ SG_ 1185 C_DrvWindowCmdAVN "This signal indicates DRV Window Open/Close Command";
CM_ SG_ 1185 C_PTGCNTLCmdAVN "This signal indicates PowerTailgate Open/Close  Command";
BA_DEF_ BO_  "DiagState" ENUM  "No","Yes";
BA_DEF_ BO_  "DiagResponse" ENUM  "No","Yes";
BA_DEF_ BO_  "DiagRequest" ENUM  "No","Yes";
BA_DEF_ BO_  "TpMessage" ENUM  "No","Yes";
BA_DEF_ BO_  "UsrMsgIDSforwardDeviation" INT 0 100;
BA_DEF_ BO_  "UsrMsgIDSbackwardDeviation" INT 50 1000;
BA_DEF_ BO_  "GenMsgCycleTime" INT 0 2000;
BA_DEF_ BO_  "GenMsgStartDelayTime" INT 0 2000;
BA_DEF_ BO_  "GenMsgSendType" ENUM  "Cyclic","NoMsgSendType";
BA_DEF_ BO_  "GenMsgCycleTimeFast" INT 0 500;
BA_DEF_ BO_  "GenMsgDelayTime" INT 0 20;
BA_DEF_ BO_  "GenMsgILSupport" ENUM  "No","Yes";
BA_DEF_ BO_  "GenMsgNrOfRepetition" INT 0 3;
BA_DEF_ BO_  "NmMessage" ENUM  "No","Yes";
BA_DEF_ BO_  "NWM-Botschaft" ENUM  "No","Yes";
BA_DEF_ BO_  "TpTxIndex" INT 0 65535;
BA_DEF_ BO_  "VFrameFormat" ENUM  "StandardCAN","ExtendedCAN","reserved","reserved","reserved","reserved","reserved","reserved","reserved","reserved","reserved","reserved","reserved","reserved","StandardCAN_FD","ExtendedCAN_FD";
BA_DEF_ SG_  "UserSigValidity" ENUM  "B+","ACC","IG","IG1","IG2","IG3","IG1 or IG2","IG1 or IG3","Undef";
BA_DEF_ SG_  "TimeoutValue" STRING ;
BA_DEF_ SG_  "UsrSigPurpose" ENUM  "Undef","FN","DIAG","DIAG(Req)","DIAG(Res)","DIAG(Phy)","DEV","CCP(Req)","CCP(Res)","NM","TP";
BA_DEF_ SG_  "GenSigStartValue" INT 0 1215752192;
BA_DEF_ SG_  "NetworkRequest" ENUM  "Yes","No";
BA_DEF_ SG_  "NetworkRequestHoldingTime" INT 0 65535;
BA_DEF_ SG_  "Description" STRING ;
BA_DEF_ SG_  "Version" STRING ;
BA_DEF_ SG_  "GenSigEnvVarType" ENUM  "Int","Float","Undef";
BA_DEF_ SG_  "GenSigSendType" ENUM  "Cyclic","OnWrite","OnWriteWithRepetition","OnChange","OnChangeWithRepetition","IfActive","IfActiveWithRepetition","NoSigSendType","OnChangeAndIfActive","OnChangeAndIfActiveWithRepetition";
BA_DEF_ SG_  "GwSigLatencyTime" INT 0 65536;
BA_DEF_ SG_  "GwSigMissingSourceType" ENUM  "Undef","OldValue","DefaultValue","InitialValue";
BA_DEF_ SG_  "NWM-WakeupAllowed" ENUM  "<n.a.>";
BA_DEF_ SG_  "RoutingFactor" INT 1 1215752192;
BA_DEF_ SG_  "SystemSignalLongSymbol" STRING ;
BA_DEF_REL_ BU_SG_REL_  "GenSigTimeoutTime" INT 0 7000;
BA_DEF_DEF_  "DiagState" "No";
BA_DEF_DEF_  "DiagResponse" "No";
BA_DEF_DEF_  "DiagRequest" "No";
BA_DEF_DEF_  "TpMessage" "No";
BA_DEF_DEF_  "UsrMsgIDSforwardDeviation" 10;
BA_DEF_DEF_  "UsrMsgIDSbackwardDeviation" 100;
BA_DEF_DEF_  "GenMsgCycleTime" 200;
BA_DEF_DEF_  "GenMsgStartDelayTime" 0;
BA_DEF_DEF_  "GenMsgSendType" "NoMsgSendType";
BA_DEF_DEF_  "GenMsgCycleTimeFast" 40;
BA_DEF_DEF_  "GenMsgDelayTime" 20;
BA_DEF_DEF_  "GenMsgILSupport" "Yes";
BA_DEF_DEF_  "GenMsgNrOfRepetition" 3;
BA_DEF_DEF_  "NmMessage" "No";
BA_DEF_DEF_  "NWM-Botschaft" "No";
BA_DEF_DEF_  "TpTxIndex" 0;
BA_DEF_DEF_  "VFrameFormat" "StandardCAN";
BA_DEF_DEF_  "UserSigValidity" "IG";
BA_DEF_DEF_  "TimeoutValue" "";
BA_DEF_DEF_  "UsrSigPurpose" "FN";
BA_DEF_DEF_  "GenSigStartValue" 0;
BA_DEF_DEF_  "NetworkRequest" "No";
BA_DEF_DEF_  "NetworkRequestHoldingTime" 0;
BA_DEF_DEF_  "Description" "";
BA_DEF_DEF_  "Version" "";
BA_DEF_DEF_  "GenSigEnvVarType" "Undef";
BA_DEF_DEF_  "GenSigSendType" "NoSigSendType";
BA_DEF_DEF_  "GwSigLatencyTime" 40;
BA_DEF_DEF_  "GwSigMissingSourceType" "Undef";
BA_DEF_DEF_  "NWM-WakeupAllowed" "<n.a.>";
BA_DEF_DEF_  "RoutingFactor" 1;
BA_DEF_DEF_REL_ "GenSigTimeoutTime" 500;
BA_DEF_DEF_  "SystemSignalLongSymbol" "";
BA_ "VFrameFormat" BO_ 2227254529 1;
BA_ "GenMsgNrOfRepetition" BO_ 2227254529 0;
BA_ "GenMsgCycleTimeFast" BO_ 2227254529 0;
BA_ "GenMsgCycleTime" BO_ 2227254529 50;
BA_ "GenMsgSendType" BO_ 2227254529 0;
BA_ "VFrameFormat" BO_ 2227254530 1;
BA_ "GenMsgNrOfRepetition" BO_ 2227254530 0;
BA_ "GenMsgCycleTimeFast" BO_ 2227254530 0;
BA_ "GenMsgCycleTime" BO_ 2227254530 50;
BA_ "GenMsgSendType" BO_ 2227254530 0;
BA_ "GenMsgCycleTime" BO_ 1266 1000;
BA_ "GenMsgSendType" BO_ 1266 0;
BA_ "GenMsgCycleTime" BO_ 1267 1000;
BA_ "GenMsgSendType" BO_ 1267 0;
BA_ "GenMsgSendType" BO_ 191 0;
BA_ "GenMsgCycleTime" BO_ 1264 1000;
BA_ "GenMsgSendType" BO_ 1264 0;
BA_ "GenMsgCycleTime" BO_ 1265 1000;
BA_ "GenMsgSendType" BO_ 1265 0;
BA_ "VFrameFormat" BO_ 2328016132 1;
BA_ "GenMsgNrOfRepetition" BO_ 2328016132 0;
BA_ "GenMsgCycleTimeFast" BO_ 2328016132 0;
BA_ "GenMsgSendType" BO_ 2328016132 0;
BA_ "GenMsgCycleTime" BO_ 1278 2000;
BA_ "GenMsgSendType" BO_ 1278 0;
BA_ "GenMsgCycleTime" BO_ 1279 0;
BA_ "VFrameFormat" BO_ 2328016129 1;
BA_ "GenMsgNrOfRepetition" BO_ 2328016129 0;
BA_ "GenMsgCycleTimeFast" BO_ 2328016129 0;
BA_ "GenMsgSendType" BO_ 2328016129 0;
BA_ "VFrameFormat" BO_ 2328016130 1;
BA_ "GenMsgNrOfRepetition" BO_ 2328016130 0;
BA_ "GenMsgCycleTimeFast" BO_ 2328016130 0;
BA_ "GenMsgSendType" BO_ 2328016130 0;
BA_ "VFrameFormat" BO_ 2328016131 1;
BA_ "GenMsgNrOfRepetition" BO_ 2328016131 0;
BA_ "GenMsgCycleTimeFast" BO_ 2328016131 0;
BA_ "GenMsgSendType" BO_ 2328016131 0;
BA_ "GenMsgCycleTime" BO_ 200 0;
BA_ "GenMsgStartDelayTime" BO_ 1159 90;
BA_ "GenMsgSendType" BO_ 1159 0;
BA_ "GenMsgSendType" BO_ 197 0;
BA_ "GenMsgCycleTime" BO_ 1165 500;
BA_ "GenMsgSendType" BO_ 1165 0;
BA_ "VFrameFormat" BO_ 2382595073 1;
BA_ "GenMsgSendType" BO_ 2382595073 0;
BA_ "GenMsgCycleTime" BO_ 1167 1000;
BA_ "GenMsgSendType" BO_ 1167 0;
BA_ "GenMsgCycleTime" BO_ 194 0;
BA_ "GenMsgCycleTime" BO_ 1166 500;
BA_ "GenMsgSendType" BO_ 1166 0;
BA_ "GenMsgCycleTime" BO_ 223 0;
BA_ "GenMsgSendType" BO_ 1171 0;
BA_ "GenMsgSendType" BO_ 1172 0;
BA_ "GenMsgSendType" BO_ 1174 0;
BA_ "GenMsgCycleTime" BO_ 1179 0;
BA_ "GenMsgCycleTime" BO_ 1180 0;
BA_ "GenMsgSendType" BO_ 208 0;
BA_ "GenMsgCycleTime" BO_ 1181 0;
BA_ "GenMsgCycleTime" BO_ 1182 0;
BA_ "GenMsgCycleTime" BO_ 1186 0;
BA_ "GenMsgCycleTime" BO_ 1185 0;
BA_ "Version" SG_ 2227254529 BAT_Crc1Val "21.09.03";
BA_ "RoutingFactor" SG_ 2227254529 BAT_Crc1Val 5;
BA_ "UserSigValidity" SG_ 2227254529 BAT_Crc1Val 7;
BA_ "GenSigStartValue" SG_ 2227254529 BAT_Crc1Val 65535;
BA_ "Description" SG_ 2227254529 BAT_Crc1Val "The data area for CRC calculation is based on the data length (DLC) of the message DB.

The CRC shall be calculated over the entire data block (excluding the CRC bytes) including the user data, alive counter and Data ID



- CRC Polynomial (0x1021) , Ini";
BA_ "Version" SG_ 2227254529 BAT_AlvCnt1Val "21.09.03";
BA_ "RoutingFactor" SG_ 2227254529 BAT_AlvCnt1Val 5;
BA_ "UserSigValidity" SG_ 2227254529 BAT_AlvCnt1Val 7;
BA_ "Description" SG_ 2227254529 BAT_AlvCnt1Val "For the first transmission request for a data element the counter shall be initialized with 0 and shall be incremented by 1 for every subsequent send request. 

When the counter reaches the maximum value(0xFF), then it shall restart with 0 for the next s";
BA_ "Version" SG_ 2227254529 BAT_CurrVal "17.11.00";
BA_ "RoutingFactor" SG_ 2227254529 BAT_CurrVal 5;
BA_ "UserSigValidity" SG_ 2227254529 BAT_CurrVal 7;
BA_ "GenSigStartValue" SG_ 2227254529 BAT_CurrVal 65535;
BA_ "Description" SG_ 2227254529 BAT_CurrVal "[For 12V Lithium Battery vehicle model]

This is Battery current as measured by battery sensor.

This value is  

   - IRANGE : 1 (medium current)

   - Resolution : 10mA";
BA_ "Version" SG_ 2227254529 BAT_SocVal "19.01.00";
BA_ "RoutingFactor" SG_ 2227254529 BAT_SocVal 5;
BA_ "UserSigValidity" SG_ 2227254529 BAT_SocVal 7;
BA_ "Description" SG_ 2227254529 BAT_SocVal "[For 12V Lithium Battery vehicle model]

This signal is battery State of Charge as calculated by battery sensor.";
BA_ "Version" SG_ 2227254529 BAT_VoltVal "17.11.00";
BA_ "RoutingFactor" SG_ 2227254529 BAT_VoltVal 5;
BA_ "UserSigValidity" SG_ 2227254529 BAT_VoltVal 7;
BA_ "GenSigStartValue" SG_ 2227254529 BAT_VoltVal 16383;
BA_ "Description" SG_ 2227254529 BAT_VoltVal "[For 12V Lithium Battery vehicle model]

This is the actual battery voltage as measured on the battery pole by battery sensor.

The Resolution is 1mV.";
BA_ "Version" SG_ 2227254529 BAT_AuxBattOpt "21.10.05";
BA_ "RoutingFactor" SG_ 2227254529 BAT_AuxBattOpt 5;
BA_ "UserSigValidity" SG_ 2227254529 BAT_AuxBattOpt 7;
BA_ "Description" SG_ 2227254529 BAT_AuxBattOpt "12V Battery Option Value(LFP 12V Battery)";
BA_ "Version" SG_ 2227254530 BAT_TempVal "20.03.05";
BA_ "RoutingFactor" SG_ 2227254530 BAT_TempVal 5;
BA_ "UserSigValidity" SG_ 2227254530 BAT_TempVal 7;
BA_ "GenSigStartValue" SG_ 2227254530 BAT_TempVal 511;
BA_ "Description" SG_ 2227254530 BAT_TempVal "This is actual battery electrolyte temperature value by battery sensor.

The value is calculated by a Battery Temperature Model, depending on measured temperature of the battery pole.

The resolution is 0.5¡É.";
BA_ "Version" SG_ 2227254530 BAT_SohVal "17.11.00";
BA_ "RoutingFactor" SG_ 2227254530 BAT_SohVal 5;
BA_ "UserSigValidity" SG_ 2227254530 BAT_SohVal 7;
BA_ "GenSigStartValue" SG_ 2227254530 BAT_SohVal 127;
BA_ "Description" SG_ 2227254530 BAT_SohVal "[For 12V Lithium Battery vehicle model]

This signal is battery State of Health(SOH) as calculated by battery sensor.

This value shows reduction rate of nominal capacity.

This value can be used for diagnosis information of application system.";
BA_ "Version" SG_ 2227254530 BAT_SnsrInvldSta "17.11.00";
BA_ "RoutingFactor" SG_ 2227254530 BAT_SnsrInvldSta 5;
BA_ "UserSigValidity" SG_ 2227254530 BAT_SnsrInvldSta 7;
BA_ "GenSigStartValue" SG_ 2227254530 BAT_SnsrInvldSta 1;
BA_ "Description" SG_ 2227254530 BAT_SnsrInvldSta "[For 12V Lithium Battery vehicle model]

This bit is Battery Sensor Invalid flag and setting condition is depending on Battery Sensor self diagnosis information.

 BS Invalid = 0 : BS is Valid Condition

 BS Invalid = 1 : BS is Invalid Condition";
BA_ "Version" SG_ 2227254530 BAT_SofVal "17.11.00";
BA_ "RoutingFactor" SG_ 2227254530 BAT_SofVal 5;
BA_ "UserSigValidity" SG_ 2227254530 BAT_SofVal 7;
BA_ "GenSigStartValue" SG_ 2227254530 BAT_SofVal 127;
BA_ "Description" SG_ 2227254530 BAT_SofVal "[For 12V Lithium Battery vehicle model]

This signal is battery State of Function(SOF) as calculated by battery sensor.

This value shows information about the battery ability to crank the engine (both of warm & cold cranking).

This value is prediction ";
BA_ "Version" SG_ 2227254530 BAT_RspErrSta "17.11.00";
BA_ "RoutingFactor" SG_ 2227254530 BAT_RspErrSta 5;
BA_ "UserSigValidity" SG_ 2227254530 BAT_RspErrSta 7;
BA_ "GenSigStartValue" SG_ 2227254530 BAT_RspErrSta 1;
BA_ "Description" SG_ 2227254530 BAT_RspErrSta "[For 12V Lithium Battery vehicle model]

Battery Sensor shall send one status bit signal, Response_Error. Response_Error shall be set whenever a frame received by the node or a frame transmitted by the node contains an error in the response field.

Respo";
BA_ "Version" SG_ 2227254530 BAT_CapacityVal "21.07.06";
BA_ "RoutingFactor" SG_ 2227254530 BAT_CapacityVal 5;
BA_ "UserSigValidity" SG_ 2227254530 BAT_CapacityVal 7;
BA_ "Description" SG_ 2227254530 BAT_CapacityVal "12V Battery Capacity Value";
BA_ "Version" SG_ 2227254530 BAT_SocErrSta "19.01.00";
BA_ "RoutingFactor" SG_ 2227254530 BAT_SocErrSta 5;
BA_ "UserSigValidity" SG_ 2227254530 BAT_SocErrSta 7;
BA_ "GenSigStartValue" SG_ 2227254530 BAT_SocErrSta 1;
BA_ "Description" SG_ 2227254530 BAT_SocErrSta "[For 12V Lithium Battery vehicle model]

This bit is flags for indication whether battery SOC detection value is plausible or not by battery sensor.

If it is set to value 0, then it means battery SOC is normal state.

If it is set to value 1, then it me";
BA_ "Version" SG_ 1266 HU_LanguageInfo "24.07.04";
BA_ "NetworkRequestHoldingTime" SG_ 1266 HU_LanguageInfo 5000;
BA_ "NetworkRequest" SG_ 1266 HU_LanguageInfo 0;
BA_ "UserSigValidity" SG_ 1266 HU_LanguageInfo 1;
BA_ "GenSigStartValue" SG_ 1266 HU_LanguageInfo 255;
BA_ "GenSigSendType" SG_ 1266 HU_LanguageInfo 4;
BA_ "Version" SG_ 1266 HU_MuteStatus "22.06.01";
BA_ "NetworkRequest" SG_ 1266 HU_MuteStatus 0;
BA_ "UserSigValidity" SG_ 1266 HU_MuteStatus 1;
BA_ "GenSigStartValue" SG_ 1266 HU_MuteStatus 3;
BA_ "GenSigSendType" SG_ 1266 HU_MuteStatus 4;
BA_ "Version" SG_ 1266 HU_WelcomeReady "22.07.05";
BA_ "UserSigValidity" SG_ 1266 HU_WelcomeReady 0;
BA_ "GenSigSendType" SG_ 1266 HU_WelcomeReady 4;
BA_ "Description" SG_ 1266 HU_WelcomeReady "H/U playback ready signal to play welcome/goodbye animation video.";
BA_ "Version" SG_ 1266 HU_UsmSupport "22.06.01";
BA_ "UserSigValidity" SG_ 1266 HU_UsmSupport 1;
BA_ "GenSigStartValue" SG_ 1266 HU_UsmSupport 3;
BA_ "GenSigSendType" SG_ 1266 HU_UsmSupport 4;
BA_ "Version" SG_ 1266 HU_NaviStatus "22.06.01";
BA_ "NetworkRequest" SG_ 1266 HU_NaviStatus 0;
BA_ "UserSigValidity" SG_ 1266 HU_NaviStatus 1;
BA_ "GenSigSendType" SG_ 1266 HU_NaviStatus 4;
BA_ "Version" SG_ 1266 HU_NaviDisp "22.06.01";
BA_ "NetworkRequest" SG_ 1266 HU_NaviDisp 0;
BA_ "UserSigValidity" SG_ 1266 HU_NaviDisp 1;
BA_ "GenSigStartValue" SG_ 1266 HU_NaviDisp 3;
BA_ "GenSigSendType" SG_ 1266 HU_NaviDisp 4;
BA_ "Version" SG_ 1266 HU_BVM_Display_Message "22.06.01";
BA_ "UserSigValidity" SG_ 1266 HU_BVM_Display_Message 3;
BA_ "GenSigStartValue" SG_ 1266 HU_BVM_Display_Message 7;
BA_ "GenSigSendType" SG_ 1266 HU_BVM_Display_Message 4;
BA_ "Version" SG_ 1266 HU_NaviCamSettingStatus "22.06.01";
BA_ "NetworkRequest" SG_ 1266 HU_NaviCamSettingStatus 0;
BA_ "UserSigValidity" SG_ 1266 HU_NaviCamSettingStatus 1;
BA_ "GenSigStartValue" SG_ 1266 HU_NaviCamSettingStatus 255;
BA_ "GenSigSendType" SG_ 1266 HU_NaviCamSettingStatus 4;
BA_ "Version" SG_ 1266 HU_EVSupport "22.06.01";
BA_ "UserSigValidity" SG_ 1266 HU_EVSupport 7;
BA_ "GenSigStartValue" SG_ 1266 HU_EVSupport 3;
BA_ "GenSigSendType" SG_ 1266 HU_EVSupport 4;
BA_ "Description" SG_ 1266 HU_EVSupport "Notification whether EV function support or not.";
BA_ "Version" SG_ 1266 HU_DayNightState "22.06.01";
BA_ "UserSigValidity" SG_ 1266 HU_DayNightState 0;
BA_ "GenSigSendType" SG_ 1266 HU_DayNightState 4;
BA_ "Description" SG_ 1266 HU_DayNightState "HU(AVNT) display day and night time state (When automatically adjusted)";
BA_ "Version" SG_ 1266 HU_AutoBrightState_New "22.06.01";
BA_ "UserSigValidity" SG_ 1266 HU_AutoBrightState_New 0;
BA_ "GenSigSendType" SG_ 1266 HU_AutoBrightState_New 4;
BA_ "Description" SG_ 1266 HU_AutoBrightState_New "HU Display Brightness State(When automatically adjusted)";
BA_ "Version" SG_ 1266 HU_VolumeStatus "22.06.01";
BA_ "NetworkRequest" SG_ 1266 HU_VolumeStatus 0;
BA_ "UserSigValidity" SG_ 1266 HU_VolumeStatus 1;
BA_ "GenSigStartValue" SG_ 1266 HU_VolumeStatus 63;
BA_ "GenSigSendType" SG_ 1266 HU_VolumeStatus 4;
BA_ "Version" SG_ 1267 RSELockOnOff "22.07.05";
BA_ "NetworkRequestHoldingTime" SG_ 1267 RSELockOnOff 5000;
BA_ "NetworkRequest" SG_ 1267 RSELockOnOff 0;
BA_ "UserSigValidity" SG_ 1267 RSELockOnOff 1;
BA_ "GenSigStartValue" SG_ 1267 RSELockOnOff 3;
BA_ "GenSigSendType" SG_ 1267 RSELockOnOff 4;
BA_ "Version" SG_ 1267 HU_ClimateScrnState "22.07.05";
BA_ "UserSigValidity" SG_ 1267 HU_ClimateScrnState 7;
BA_ "GenSigStartValue" SG_ 1267 HU_ClimateScrnState 3;
BA_ "GenSigSendType" SG_ 1267 HU_ClimateScrnState 4;
BA_ "Description" SG_ 1267 HU_ClimateScrnState "AVNT Climate screen state";
BA_ "Version" SG_ 1267 HU_Graphreset_Info "22.07.05";
BA_ "UserSigValidity" SG_ 1267 HU_Graphreset_Info 1;
BA_ "GenSigStartValue" SG_ 1267 HU_Graphreset_Info 3;
BA_ "GenSigSendType" SG_ 1267 HU_Graphreset_Info 4;
BA_ "Version" SG_ 1267 HU_VRActivity "22.07.05";
BA_ "NetworkRequest" SG_ 1267 HU_VRActivity 0;
BA_ "UserSigValidity" SG_ 1267 HU_VRActivity 1;
BA_ "GenSigStartValue" SG_ 1267 HU_VRActivity 3;
BA_ "GenSigSendType" SG_ 1267 HU_VRActivity 4;
BA_ "Version" SG_ 191 RL_SHVU_DTCdisplay "22.05.04";
BA_ "NetworkRequestHoldingTime" SG_ 191 RL_SHVU_DTCdisplay 5000;
BA_ "NetworkRequest" SG_ 191 RL_SHVU_DTCdisplay 0;
BA_ "UserSigValidity" SG_ 191 RL_SHVU_DTCdisplay 7;
BA_ "GenSigSendType" SG_ 191 RL_SHVU_DTCdisplay 4;
BA_ "Description" SG_ 191 RL_SHVU_DTCdisplay "0x00: DTC is not exist(Fail is not exist)/0x01:IGN2 Fuse Open Detection/0x02:Switch Input Detection at Same Time/0x03:NTC/Heating wire Open Detection/0x04:NTC+/NTC- Terminal Short Detection/0x05:NTC+/Heater+ Terminal Short Detection/0x06:NTC+/Heater-, He";
BA_ "Version" SG_ 191 RL_SHVU_DiagMode "22.05.04";
BA_ "NetworkRequestHoldingTime" SG_ 191 RL_SHVU_DiagMode 5000;
BA_ "NetworkRequest" SG_ 191 RL_SHVU_DiagMode 0;
BA_ "UserSigValidity" SG_ 191 RL_SHVU_DiagMode 7;
BA_ "GenSigSendType" SG_ 191 RL_SHVU_DiagMode 4;
BA_ "Description" SG_ 191 RL_SHVU_DiagMode "0x0:Default/0x1:DTC Mode/0x2:Normal Mode/0x3:Invalid";
BA_ "Version" SG_ 1264 HU_TimeSetting "18.09.02";
BA_ "NetworkRequest" SG_ 1264 HU_TimeSetting 0;
BA_ "UserSigValidity" SG_ 1264 HU_TimeSetting 0;
BA_ "GenSigStartValue" SG_ 1264 HU_TimeSetting 3;
BA_ "GenSigSendType" SG_ 1264 HU_TimeSetting 4;
BA_ "Description" SG_ 1264 HU_TimeSetting "18.08.09_";
BA_ "Version" SG_ 1264 HU_DisplayMinute "21.07.07";
BA_ "NetworkRequestHoldingTime" SG_ 1264 HU_DisplayMinute 200;
BA_ "NetworkRequest" SG_ 1264 HU_DisplayMinute 0;
BA_ "UserSigValidity" SG_ 1264 HU_DisplayMinute 0;
BA_ "GenSigStartValue" SG_ 1264 HU_DisplayMinute 255;
BA_ "GenSigSendType" SG_ 1264 HU_DisplayMinute 4;
BA_ "Version" SG_ 1264 HU_Status "21.07.07";
BA_ "NetworkRequestHoldingTime" SG_ 1264 HU_Status 200;
BA_ "NetworkRequest" SG_ 1264 HU_Status 0;
BA_ "UserSigValidity" SG_ 1264 HU_Status 0;
BA_ "GenSigStartValue" SG_ 1264 HU_Status 15;
BA_ "GenSigSendType" SG_ 1264 HU_Status 4;
BA_ "Version" SG_ 1264 HU_DisplaySecond "21.07.07";
BA_ "NetworkRequestHoldingTime" SG_ 1264 HU_DisplaySecond 200;
BA_ "NetworkRequest" SG_ 1264 HU_DisplaySecond 0;
BA_ "UserSigValidity" SG_ 1264 HU_DisplaySecond 0;
BA_ "GenSigStartValue" SG_ 1264 HU_DisplaySecond 255;
BA_ "GenSigSendType" SG_ 1264 HU_DisplaySecond 4;
BA_ "Version" SG_ 1264 HU_DisplayMonth "21.07.07";
BA_ "NetworkRequestHoldingTime" SG_ 1264 HU_DisplayMonth 200;
BA_ "NetworkRequest" SG_ 1264 HU_DisplayMonth 0;
BA_ "UserSigValidity" SG_ 1264 HU_DisplayMonth 0;
BA_ "GenSigStartValue" SG_ 1264 HU_DisplayMonth 15;
BA_ "GenSigSendType" SG_ 1264 HU_DisplayMonth 4;
BA_ "Version" SG_ 1264 HU_DisplayYear1 "18.09.02";
BA_ "NetworkRequest" SG_ 1264 HU_DisplayYear1 0;
BA_ "UserSigValidity" SG_ 1264 HU_DisplayYear1 0;
BA_ "GenSigStartValue" SG_ 1264 HU_DisplayYear1 3;
BA_ "GenSigSendType" SG_ 1264 HU_DisplayYear1 4;
BA_ "Description" SG_ 1264 HU_DisplayYear1 "18.08.09_";
BA_ "Version" SG_ 1264 HU_DisplayYear2 "21.07.07";
BA_ "NetworkRequestHoldingTime" SG_ 1264 HU_DisplayYear2 200;
BA_ "NetworkRequest" SG_ 1264 HU_DisplayYear2 0;
BA_ "UserSigValidity" SG_ 1264 HU_DisplayYear2 0;
BA_ "GenSigStartValue" SG_ 1264 HU_DisplayYear2 255;
BA_ "GenSigSendType" SG_ 1264 HU_DisplayYear2 4;
BA_ "Version" SG_ 1264 HU_DisplayDay "21.07.07";
BA_ "NetworkRequestHoldingTime" SG_ 1264 HU_DisplayDay 200;
BA_ "NetworkRequest" SG_ 1264 HU_DisplayDay 0;
BA_ "UserSigValidity" SG_ 1264 HU_DisplayDay 0;
BA_ "GenSigStartValue" SG_ 1264 HU_DisplayDay 255;
BA_ "GenSigSendType" SG_ 1264 HU_DisplayDay 4;
BA_ "Version" SG_ 1264 HU_AM_PM_INFO "18.09.02";
BA_ "NetworkRequest" SG_ 1264 HU_AM_PM_INFO 0;
BA_ "UserSigValidity" SG_ 1264 HU_AM_PM_INFO 0;
BA_ "GenSigStartValue" SG_ 1264 HU_AM_PM_INFO 3;
BA_ "GenSigSendType" SG_ 1264 HU_AM_PM_INFO 4;
BA_ "Description" SG_ 1264 HU_AM_PM_INFO "18.08.09_";
BA_ "Version" SG_ 1264 HU_TimeFormat "18.09.02";
BA_ "NetworkRequest" SG_ 1264 HU_TimeFormat 0;
BA_ "UserSigValidity" SG_ 1264 HU_TimeFormat 0;
BA_ "GenSigStartValue" SG_ 1264 HU_TimeFormat 3;
BA_ "GenSigSendType" SG_ 1264 HU_TimeFormat 4;
BA_ "Description" SG_ 1264 HU_TimeFormat "18.08.09_";
BA_ "Version" SG_ 1264 HU_ComRefresh "18.09.02";
BA_ "NetworkRequest" SG_ 1264 HU_ComRefresh 0;
BA_ "UserSigValidity" SG_ 1264 HU_ComRefresh 0;
BA_ "GenSigStartValue" SG_ 1264 HU_ComRefresh 3;
BA_ "GenSigSendType" SG_ 1264 HU_ComRefresh 4;
BA_ "Description" SG_ 1264 HU_ComRefresh "18.08.09_";
BA_ "Version" SG_ 1264 HU_ClockInfo "18.09.02";
BA_ "NetworkRequest" SG_ 1264 HU_ClockInfo 0;
BA_ "UserSigValidity" SG_ 1264 HU_ClockInfo 0;
BA_ "GenSigStartValue" SG_ 1264 HU_ClockInfo 3;
BA_ "GenSigSendType" SG_ 1264 HU_ClockInfo 4;
BA_ "Description" SG_ 1264 HU_ClockInfo "18.08.09_";
BA_ "Version" SG_ 1264 HU_DisplayHour "21.07.07";
BA_ "NetworkRequestHoldingTime" SG_ 1264 HU_DisplayHour 200;
BA_ "NetworkRequest" SG_ 1264 HU_DisplayHour 0;
BA_ "UserSigValidity" SG_ 1264 HU_DisplayHour 0;
BA_ "GenSigStartValue" SG_ 1264 HU_DisplayHour 255;
BA_ "GenSigSendType" SG_ 1264 HU_DisplayHour 4;
BA_ "Version" SG_ 1265 HU_IG3_Request "22.07.05";
BA_ "UserSigValidity" SG_ 1265 HU_IG3_Request 0;
BA_ "GenSigStartValue" SG_ 1265 HU_IG3_Request 3;
BA_ "GenSigSendType" SG_ 1265 HU_IG3_Request 4;
BA_ "Description" SG_ 1265 HU_IG3_Request "IG3 wake up and sleep Request signal for EV/PHEV/HEV



Please apply this signal after checking ICU on your vehicle.";
BA_ "Version" SG_ 1265 HU_DigitalKeyGroupingSupport "23.05.01";
BA_ "UserSigValidity" SG_ 1265 HU_DigitalKeyGroupingSupport 1;
BA_ "GenSigSendType" SG_ 1265 HU_DigitalKeyGroupingSupport 4;
BA_ "Description" SG_ 1265 HU_DigitalKeyGroupingSupport "This signal indicates whether the H/U can support the grouping specification for digital key.";
BA_ "Version" SG_ 1265 HU_Background "22.11.03";
BA_ "UserSigValidity" SG_ 1265 HU_Background 1;
BA_ "GenSigStartValue" SG_ 1265 HU_Background 7;
BA_ "GenSigSendType" SG_ 1265 HU_Background 4;
BA_ "Description" SG_ 1265 HU_Background "HU Backgound image info";
BA_ "Version" SG_ 1265 HU_BackgroundFadeInOut "22.07.05";
BA_ "UserSigValidity" SG_ 1265 HU_BackgroundFadeInOut 1;
BA_ "GenSigStartValue" SG_ 1265 HU_BackgroundFadeInOut 1023;
BA_ "GenSigSendType" SG_ 1265 HU_BackgroundFadeInOut 4;
BA_ "Description" SG_ 1265 HU_BackgroundFadeInOut "HU Background Fade in/out info

(HEX * Factor) %";
BA_ "Version" SG_ 1265 CF_AVN_AutoWashModeSta "22.07.05";
BA_ "UserSigValidity" SG_ 1265 CF_AVN_AutoWashModeSta 3;
BA_ "GenSigSendType" SG_ 1265 CF_AVN_AutoWashModeSta 4;
BA_ "Description" SG_ 1265 CF_AVN_AutoWashModeSta "Washer Mode status signal";
BA_ "Version" SG_ 1265 CRS_BabyOnSeatstates "25.01.01";
BA_ "UserSigValidity" SG_ 1265 CRS_BabyOnSeatstates 0;
BA_ "GenSigSendType" SG_ 1265 CRS_BabyOnSeatstates 4;
BA_ "Description" SG_ 1265 CRS_BabyOnSeatstates "The status of baby left in the car";
BA_ "Version" SG_ 1265 OMUOSMirCtrl_Vr "22.07.05";
BA_ "UserSigValidity" SG_ 1265 OMUOSMirCtrl_Vr 3;
BA_ "GenSigStartValue" SG_ 1265 OMUOSMirCtrl_Vr 3;
BA_ "GenSigSendType" SG_ 1265 OMUOSMirCtrl_Vr 4;
BA_ "Version" SG_ 2328016132 VCU_LowSocDispPcVal "21.03.00";
BA_ "RoutingFactor" SG_ 2328016132 VCU_LowSocDispPcVal 0;
BA_ "UserSigValidity" SG_ 2328016132 VCU_LowSocDispPcVal 7;
BA_ "TimeoutValue" SG_ 2328016132 VCU_LowSocDispPcVal "0x0";
BA_ "Description" SG_ 2328016132 VCU_LowSocDispPcVal "Low SOC Display Percent Value";
BA_ "Version" SG_ 2328016132 VCU_DteSocBasedVal "20.12.04";
BA_ "RoutingFactor" SG_ 2328016132 VCU_DteSocBasedVal 0;
BA_ "UserSigValidity" SG_ 2328016132 VCU_DteSocBasedVal 7;
BA_ "Description" SG_ 2328016132 VCU_DteSocBasedVal "Maximum Drivable Distance with Soc Based (China Only Func)";
BA_ "Version" SG_ 2328016132 VCU_InstFuelEcoVal_Per100km "19.03.03";
BA_ "RoutingFactor" SG_ 2328016132 VCU_InstFuelEcoVal_Per100km 0;
BA_ "UserSigValidity" SG_ 2328016132 VCU_InstFuelEcoVal_Per100km 7;
BA_ "Description" SG_ 2328016132 VCU_InstFuelEcoVal_Per100km "Instant Fuel Economy(kWh/100km)";
BA_ "Version" SG_ 2328016132 VCU_InstFuelEcoVal_PerkWh "19.03.03";
BA_ "RoutingFactor" SG_ 2328016132 VCU_InstFuelEcoVal_PerkWh 0;
BA_ "UserSigValidity" SG_ 2328016132 VCU_InstFuelEcoVal_PerkWh 7;
BA_ "Description" SG_ 2328016132 VCU_InstFuelEcoVal_PerkWh "Fuel Economy in EV";
BA_ "Version" SG_ 2328016132 VCU_AvnDteCorFacVal "22.11.03";
BA_ "RoutingFactor" SG_ 2328016132 VCU_AvnDteCorFacVal 0;
BA_ "UserSigValidity" SG_ 2328016132 VCU_AvnDteCorFacVal 7;
BA_ "Description" SG_ 2328016132 VCU_AvnDteCorFacVal "AVN DTE Correlation Factor Value

- 0xFF : 255 (Invalid)

- 0x0~0xC8 : 0~200

- 0xC8~0xFE : 201~254 (Reserved)

- Physical value min. : 0 * 0.01 = 0 (0x0)

- Physical value max. : 200 * 0.01 = 2 (0xC8)";
BA_ "Version" SG_ 2328016132 VCU_DteGuidePosVal "22.11.03";
BA_ "RoutingFactor" SG_ 2328016132 VCU_DteGuidePosVal 0;
BA_ "UserSigValidity" SG_ 2328016132 VCU_DteGuidePosVal 7;
BA_ "TimeoutValue" SG_ 2328016132 VCU_DteGuidePosVal "7F";
BA_ "Description" SG_ 2328016132 VCU_DteGuidePosVal "DTE Guide Position Value

- 0x7F : 127 (Invalid)

- 0x0~0x78 : 0~120

- 0x79~0x7E : 121~126 (Reserved)

- Physical value min. : 0 -10 = -10 (0x0)

- Physical value max. : 120 - 10 = 110 (0x78)";
BA_ "Version" SG_ 2328016132 VCU_StopCtrlWarnMsgSta "24.12.01";
BA_ "RoutingFactor" SG_ 2328016132 VCU_StopCtrlWarnMsgSta 0;
BA_ "UserSigValidity" SG_ 2328016132 VCU_StopCtrlWarnMsgSta 7;
BA_ "Description" SG_ 2328016132 VCU_StopCtrlWarnMsgSta "i-Pedal Warning Message Status";
BA_ "Version" SG_ 2328016132 VCU_DrvModeDefault "21.09.07";
BA_ "RoutingFactor" SG_ 2328016132 VCU_DrvModeDefault 0;
BA_ "UserSigValidity" SG_ 2328016132 VCU_DrvModeDefault 7;
BA_ "Description" SG_ 2328016132 VCU_DrvModeDefault "This signal is the drive mode that needs to return to default on initial strat-up and restart. 

This signal is only used for cluster display.";
BA_ "Version" SG_ 2328016132 VCU_DrvModeLast "21.09.07";
BA_ "RoutingFactor" SG_ 2328016132 VCU_DrvModeLast 0;
BA_ "UserSigValidity" SG_ 2328016132 VCU_DrvModeLast 7;
BA_ "Description" SG_ 2328016132 VCU_DrvModeLast "This signal is the drive mode that needs to maintain on restart.This signal is only used for cluster display* If BitX is 1, the drive mode remains in the last mode on restart.* If BitX is 0, the drive mode returns to default mode on restart.";
BA_ "Version" SG_ 1278 HU_Type "23.12.00";
BA_ "NetworkRequestHoldingTime" SG_ 1278 HU_Type 7000;
BA_ "NetworkRequest" SG_ 1278 HU_Type 0;
BA_ "UserSigValidity" SG_ 1278 HU_Type 1;
BA_ "GenSigStartValue" SG_ 1278 HU_Type 255;
BA_ "GenSigSendType" SG_ 1278 HU_Type 4;
BA_ "Version" SG_ 1278 HU_DistributeInfo "20.09.00";
BA_ "NetworkRequestHoldingTime" SG_ 1278 HU_DistributeInfo 7000;
BA_ "NetworkRequest" SG_ 1278 HU_DistributeInfo 0;
BA_ "UserSigValidity" SG_ 1278 HU_DistributeInfo 1;
BA_ "GenSigStartValue" SG_ 1278 HU_DistributeInfo 255;
BA_ "GenSigSendType" SG_ 1278 HU_DistributeInfo 4;
BA_ "Version" SG_ 1278 HU_OptionInfo "25.01.00";
BA_ "UserSigValidity" SG_ 1278 HU_OptionInfo 0;
BA_ "GenSigStartValue" SG_ 1278 HU_OptionInfo 32768;
BA_ "GenSigSendType" SG_ 1278 HU_OptionInfo 4;
BA_ "Description" SG_ 1278 HU_OptionInfo "Bit0 : Navi (0: Not Support / 1: Support)

Bit1 : USM (0: Not Support / 1: Support)

Bit2 : TMS (0: Not Support / 1: Support)

Bit3 : Multi Profile (0: Not Support(No Profile or Single Profile)  / 1: Support)

Bit4 : Camera Guideline (0: Displayed by Cam";
BA_ "Version" SG_ 1278 HU_NaviHandshakingSupport "20.05.02";
BA_ "UserSigValidity" SG_ 1278 HU_NaviHandshakingSupport 1;
BA_ "GenSigSendType" SG_ 1278 HU_NaviHandshakingSupport 4;
BA_ "Description" SG_ 1278 HU_NaviHandshakingSupport "This is a signal to send whether handshaking logic is applied related to Navigation's 'Map based ADAS' specification";
BA_ "Version" SG_ 1278 HU_AMP_EQVariant "20.08.06";
BA_ "UserSigValidity" SG_ 1278 HU_AMP_EQVariant 1;
BA_ "GenSigStartValue" SG_ 1278 HU_AMP_EQVariant 31;
BA_ "GenSigSendType" SG_ 1278 HU_AMP_EQVariant 4;
BA_ "Version" SG_ 1278 HU_AdasSupport "20.05.02";
BA_ "NetworkRequestHoldingTime" SG_ 1278 HU_AdasSupport 5000;
BA_ "NetworkRequest" SG_ 1278 HU_AdasSupport 0;
BA_ "UserSigValidity" SG_ 1278 HU_AdasSupport 1;
BA_ "GenSigStartValue" SG_ 1278 HU_AdasSupport 7;
BA_ "GenSigSendType" SG_ 1278 HU_AdasSupport 4;
BA_ "Description" SG_ 1278 HU_AdasSupport "0x0 : Not Support

0x1 : ADAS Support (General Map) - Send map information based on General Map

0x2 : ADAS Support (Map based ADAS v1) - Send map information based on Map based ADAS v1 or v1.5

0x3 : ADAS Support (Map based ADAS v2) - Send map informati";
BA_ "Version" SG_ 1278 HU_Navi_RspADASMapMsg "21.11.04";
BA_ "UserSigValidity" SG_ 1278 HU_Navi_RspADASMapMsg 3;
BA_ "GenSigSendType" SG_ 1278 HU_Navi_RspADASMapMsg 4;
BA_ "Description" SG_ 1278 HU_Navi_RspADASMapMsg "This signal indicates an ADAS map message response from H_U to ECU 

which is stored the  required Map based ADAS messages for each ECU



Each bit indicates the request messages as follows.

(1: Sending message / 0 : Doens't sending message)

- Bit 0 : ";
BA_ "Version" SG_ 1279 USM_SmartRegen_Map_Set "19.11.05";
BA_ "UserSigValidity" SG_ 1279 USM_SmartRegen_Map_Set 3;
BA_ "GenSigSendType" SG_ 1279 USM_SmartRegen_Map_Set 4;
BA_ "Description" SG_ 1279 USM_SmartRegen_Map_Set "Smart Regeneration 2.0 Map information USM User set signal";
BA_ "Version" SG_ 1279 USM_SmartRegen_Sens_Set "19.11.05";
BA_ "UserSigValidity" SG_ 1279 USM_SmartRegen_Sens_Set 3;
BA_ "GenSigSendType" SG_ 1279 USM_SmartRegen_Sens_Set 4;
BA_ "Description" SG_ 1279 USM_SmartRegen_Sens_Set "Smart Regeneration User Personality of Reduction Set Signal";
BA_ "Version" SG_ 1279 AVN_SeatPosMemory_Btn "19.11.11";
BA_ "UserSigValidity" SG_ 1279 AVN_SeatPosMemory_Btn 3;
BA_ "GenSigSendType" SG_ 1279 AVN_SeatPosMemory_Btn 4;
BA_ "Description" SG_ 1279 AVN_SeatPosMemory_Btn "Seat position save signal";
BA_ "Version" SG_ 1279 AVN_SeatPosPlyBck_Btn "19.11.11";
BA_ "UserSigValidity" SG_ 1279 AVN_SeatPosPlyBck_Btn 3;
BA_ "GenSigSendType" SG_ 1279 AVN_SeatPosPlyBck_Btn 4;
BA_ "Description" SG_ 1279 AVN_SeatPosPlyBck_Btn "Seat position move signal";
BA_ "Version" SG_ 1279 USM_RhstaLvlEnaSetReq "19.12.00";
BA_ "UserSigValidity" SG_ 1279 USM_RhstaLvlEnaSetReq 0;
BA_ "GenSigSendType" SG_ 1279 USM_RhstaLvlEnaSetReq 4;
BA_ "Description" SG_ 1279 USM_RhstaLvlEnaSetReq "USM Request for CMS Brightness with Rheostat";
BA_ "Version" SG_ 1279 USM_CMSDayBrgtnsLvlLHSetReq "19.12.00";
BA_ "UserSigValidity" SG_ 1279 USM_CMSDayBrgtnsLvlLHSetReq 0;
BA_ "GenSigStartValue" SG_ 1279 USM_CMSDayBrgtnsLvlLHSetReq 15;
BA_ "GenSigSendType" SG_ 1279 USM_CMSDayBrgtnsLvlLHSetReq 4;
BA_ "Description" SG_ 1279 USM_CMSDayBrgtnsLvlLHSetReq "USM Request for Day Brightness Level of CMS LH";
BA_ "Version" SG_ 1279 USM_CMSNgtBrgtnsLvlLHSetReq "19.12.00";
BA_ "UserSigValidity" SG_ 1279 USM_CMSNgtBrgtnsLvlLHSetReq 0;
BA_ "GenSigStartValue" SG_ 1279 USM_CMSNgtBrgtnsLvlLHSetReq 15;
BA_ "GenSigSendType" SG_ 1279 USM_CMSNgtBrgtnsLvlLHSetReq 4;
BA_ "Description" SG_ 1279 USM_CMSNgtBrgtnsLvlLHSetReq "USM Request for Night Brightness Level of CMS LH";
BA_ "Version" SG_ 1279 USM_CMSDayBrgtnsLvlRHSetReq "19.12.00";
BA_ "UserSigValidity" SG_ 1279 USM_CMSDayBrgtnsLvlRHSetReq 0;
BA_ "GenSigStartValue" SG_ 1279 USM_CMSDayBrgtnsLvlRHSetReq 15;
BA_ "GenSigSendType" SG_ 1279 USM_CMSDayBrgtnsLvlRHSetReq 4;
BA_ "Description" SG_ 1279 USM_CMSDayBrgtnsLvlRHSetReq "USM Request for Day Brightness Level of CMS RH";
BA_ "Version" SG_ 1279 USM_CMSNgtBrgtnsLvlRHSetReq "19.12.00";
BA_ "UserSigValidity" SG_ 1279 USM_CMSNgtBrgtnsLvlRHSetReq 0;
BA_ "GenSigStartValue" SG_ 1279 USM_CMSNgtBrgtnsLvlRHSetReq 15;
BA_ "GenSigSendType" SG_ 1279 USM_CMSNgtBrgtnsLvlRHSetReq 4;
BA_ "Description" SG_ 1279 USM_CMSNgtBrgtnsLvlRHSetReq "USM Request for Night Brightness Level of CMS RH";
BA_ "Version" SG_ 1279 USM_CMSBrgtnsReset "20.06.01";
BA_ "UserSigValidity" SG_ 1279 USM_CMSBrgtnsReset 3;
BA_ "GenSigSendType" SG_ 1279 USM_CMSBrgtnsReset 4;
BA_ "Description" SG_ 1279 USM_CMSBrgtnsReset "CMS Brightness Reset (LH/RH)";
BA_ "Version" SG_ 1279 USM_TurnDistLnDispSetReq "19.12.00";
BA_ "UserSigValidity" SG_ 1279 USM_TurnDistLnDispSetReq 0;
BA_ "GenSigSendType" SG_ 1279 USM_TurnDistLnDispSetReq 4;
BA_ "Description" SG_ 1279 USM_TurnDistLnDispSetReq "USM Request for CMS Distance Lane Display";
BA_ "Version" SG_ 1279 PCA_FrSd_NValueSet "19.12.00";
BA_ "UserSigValidity" SG_ 1279 PCA_FrSd_NValueSet 3;
BA_ "GenSigSendType" SG_ 1279 PCA_FrSd_NValueSet 4;
BA_ "Description" SG_ 1279 PCA_FrSd_NValueSet "USM Request for PCA Front/Side";
BA_ "Version" SG_ 1279 CF_AVN_1stRrStRmndNValueSet "20.03.05";
BA_ "UserSigValidity" SG_ 1279 CF_AVN_1stRrStRmndNValueSet 3;
BA_ "GenSigSendType" SG_ 1279 CF_AVN_1stRrStRmndNValueSet 4;
BA_ "Description" SG_ 1279 CF_AVN_1stRrStRmndNValueSet "This signal is for seting the ROA function when IBU control ROA Function.";
BA_ "Version" SG_ 1279 C_AllDrOpnNValueSet "19.12.07";
BA_ "UserSigValidity" SG_ 1279 C_AllDrOpnNValueSet 3;
BA_ "GenSigSendType" SG_ 1279 C_AllDrOpnNValueSet 4;
BA_ "Description" SG_ 1279 C_AllDrOpnNValueSet "ALL Door (PSD PTG) Open Function by FOB Unlock Long Key USM Setting Signal

0x0 : Not Display in USM

0x1 : All Door Open Function Off

0x2 : Only PSD Open By FOB Unlock Long KEY

0x3 : PSD and PTG Open by FOB Unlock Long KEY

0x4 ~ 0x6 : Reserved

0x7 :";
BA_ "Version" SG_ 1279 USM_RpmECOSet "20.06.01";
BA_ "UserSigValidity" SG_ 1279 USM_RpmECOSet 3;
BA_ "GenSigSendType" SG_ 1279 USM_RpmECOSet 4;
BA_ "Description" SG_ 1279 USM_RpmECOSet "Relation To cluster Gauge Display";
BA_ "Version" SG_ 1279 VESS_ChgGuideMdLvl "20.05.01";
BA_ "UserSigValidity" SG_ 1279 VESS_ChgGuideMdLvl 3;
BA_ "GenSigSendType" SG_ 1279 VESS_ChgGuideMdLvl 4;
BA_ "Description" SG_ 1279 VESS_ChgGuideMdLvl "Charging Guide Volume Level function USM signal";
BA_ "Version" SG_ 1279 Usm_RpmSPORTSet "20.02.04";
BA_ "UserSigValidity" SG_ 1279 Usm_RpmSPORTSet 3;
BA_ "GenSigSendType" SG_ 1279 Usm_RpmSPORTSet 4;
BA_ "Description" SG_ 1279 Usm_RpmSPORTSet "Relation to cluster RPM Gauge Display";
BA_ "Version" SG_ 1279 Usm_RpmSPORTPLUSSet "20.02.04";
BA_ "UserSigValidity" SG_ 1279 Usm_RpmSPORTPLUSSet 3;
BA_ "GenSigSendType" SG_ 1279 Usm_RpmSPORTPLUSSet 4;
BA_ "Description" SG_ 1279 Usm_RpmSPORTPLUSSet "RElation to Cluster RPM Gauge Display";
BA_ "Version" SG_ 2328016129 VCU_Crc5Val "21.09.03";
BA_ "RoutingFactor" SG_ 2328016129 VCU_Crc5Val 0;
BA_ "UserSigValidity" SG_ 2328016129 VCU_Crc5Val 7;
BA_ "GenSigStartValue" SG_ 2328016129 VCU_Crc5Val 65535;
BA_ "Description" SG_ 2328016129 VCU_Crc5Val "The data area for CRC calculation is based on the data length (DLC) of the message DB.

The CRC shall be calculated over the entire data block (excluding the CRC bytes) including the user data, alive counter and Data ID



- CRC Polynomial (0x1021) , Ini";
BA_ "Version" SG_ 2328016129 VCU_AlvCnt5Val "21.09.03";
BA_ "RoutingFactor" SG_ 2328016129 VCU_AlvCnt5Val 0;
BA_ "UserSigValidity" SG_ 2328016129 VCU_AlvCnt5Val 7;
BA_ "Description" SG_ 2328016129 VCU_AlvCnt5Val "For the first transmission request for a data element the counter shall be initialized with 0 and shall be incremented by 1 for every subsequent send request. 

When the counter reaches the maximum value(0xFF), then it shall restart with 0 for the next s";
BA_ "Version" SG_ 2328016129 VCU_EvDrvRdyCluDispSta "19.09.05";
BA_ "RoutingFactor" SG_ 2328016129 VCU_EvDrvRdyCluDispSta 0;
BA_ "UserSigValidity" SG_ 2328016129 VCU_EvDrvRdyCluDispSta 7;
BA_ "Description" SG_ 2328016129 VCU_EvDrvRdyCluDispSta "EV Drive Ready for Cluster Display Only";
BA_ "Version" SG_ 2328016129 VCU_PwrDnModeSta "19.03.03";
BA_ "RoutingFactor" SG_ 2328016129 VCU_PwrDnModeSta 0;
BA_ "UserSigValidity" SG_ 2328016129 VCU_PwrDnModeSta 7;
BA_ "Description" SG_ 2328016129 VCU_PwrDnModeSta "Power Down Mode";
BA_ "Version" SG_ 2328016129 VCU_CluWarnMsgSta "23.08.03";
BA_ "RoutingFactor" SG_ 2328016129 VCU_CluWarnMsgSta 0;
BA_ "UserSigValidity" SG_ 2328016129 VCU_CluWarnMsgSta 7;
BA_ "Description" SG_ 2328016129 VCU_CluWarnMsgSta "Cluster Warning Message";
BA_ "Version" SG_ 2328016129 VCU_DteOffDispSta "19.06.02";
BA_ "RoutingFactor" SG_ 2328016129 VCU_DteOffDispSta 0;
BA_ "UserSigValidity" SG_ 2328016129 VCU_DteOffDispSta 7;
BA_ "Description" SG_ 2328016129 VCU_DteOffDispSta "DTE Off('---' Display)";
BA_ "Version" SG_ 2328016129 VCU_LowSocAlertSta "19.03.03";
BA_ "RoutingFactor" SG_ 2328016129 VCU_LowSocAlertSta 0;
BA_ "UserSigValidity" SG_ 2328016129 VCU_LowSocAlertSta 7;
BA_ "Description" SG_ 2328016129 VCU_LowSocAlertSta "Low SOC Alert of High-Voltage Battery";
BA_ "Version" SG_ 2328016129 VCU_VcrmReq "19.03.03";
BA_ "RoutingFactor" SG_ 2328016129 VCU_VcrmReq 0;
BA_ "UserSigValidity" SG_ 2328016129 VCU_VcrmReq 7;
BA_ "Description" SG_ 2328016129 VCU_VcrmReq "VCRM Trigger Signal(Request VCRM Data Logging)";
BA_ "Version" SG_ 2328016129 VCU_PdlWarnMsgSta "19.03.03";
BA_ "RoutingFactor" SG_ 2328016129 VCU_PdlWarnMsgSta 0;
BA_ "UserSigValidity" SG_ 2328016129 VCU_PdlWarnMsgSta 7;
BA_ "Version" SG_ 2328016129 VCU_AwdDiagDispSta "20.01.00";
BA_ "RoutingFactor" SG_ 2328016129 VCU_AwdDiagDispSta 0;
BA_ "UserSigValidity" SG_ 2328016129 VCU_AwdDiagDispSta 7;
BA_ "Description" SG_ 2328016129 VCU_AwdDiagDispSta "e4WD Diagnosis Display Status";
BA_ "Version" SG_ 2328016129 VCU_AwdLockDispSta "20.01.00";
BA_ "RoutingFactor" SG_ 2328016129 VCU_AwdLockDispSta 0;
BA_ "UserSigValidity" SG_ 2328016129 VCU_AwdLockDispSta 7;
BA_ "Description" SG_ 2328016129 VCU_AwdLockDispSta "e4WD Lock Mode Display Status";
BA_ "Version" SG_ 2328016129 VCU_VirtualApsActSta "19.03.03";
BA_ "RoutingFactor" SG_ 2328016129 VCU_VirtualApsActSta 0;
BA_ "UserSigValidity" SG_ 2328016129 VCU_VirtualApsActSta 7;
BA_ "Description" SG_ 2328016129 VCU_VirtualApsActSta "Virtual APS Activated";
BA_ "Version" SG_ 2328016129 VCU_VirtualApsVal "19.03.03";
BA_ "RoutingFactor" SG_ 2328016129 VCU_VirtualApsVal 0;
BA_ "UserSigValidity" SG_ 2328016129 VCU_VirtualApsVal 7;
BA_ "Description" SG_ 2328016129 VCU_VirtualApsVal "Estimated Accelerator Pedal Value when Auto Cruise Mode";
BA_ "Version" SG_ 2328016129 VCU_ServiceLampReq "19.03.03";
BA_ "RoutingFactor" SG_ 2328016129 VCU_ServiceLampReq 0;
BA_ "UserSigValidity" SG_ 2328016129 VCU_ServiceLampReq 7;
BA_ "Description" SG_ 2328016129 VCU_ServiceLampReq "Sevice Lamp Request";
BA_ "Version" SG_ 2328016129 VCU_ServiceModeSta "20.10.00";
BA_ "RoutingFactor" SG_ 2328016129 VCU_ServiceModeSta 0;
BA_ "UserSigValidity" SG_ 2328016129 VCU_ServiceModeSta 7;
BA_ "Description" SG_ 2328016129 VCU_ServiceModeSta "Service Mode";
BA_ "Version" SG_ 2328016129 VCU_NPosWshModSta "19.07.06";
BA_ "RoutingFactor" SG_ 2328016129 VCU_NPosWshModSta 0;
BA_ "UserSigValidity" SG_ 2328016129 VCU_NPosWshModSta 7;
BA_ "Description" SG_ 2328016129 VCU_NPosWshModSta "N Wash Mode Status";
BA_ "Version" SG_ 2328016129 VCU_PowerTrainType "19.03.03";
BA_ "RoutingFactor" SG_ 2328016129 VCU_PowerTrainType 0;
BA_ "UserSigValidity" SG_ 2328016129 VCU_PowerTrainType 7;
BA_ "Description" SG_ 2328016129 VCU_PowerTrainType "VCU_PowerTrainType";
BA_ "Version" SG_ 2328016130 VCU_DteBaseVal "19.03.03";
BA_ "RoutingFactor" SG_ 2328016130 VCU_DteBaseVal 0;
BA_ "UserSigValidity" SG_ 2328016130 VCU_DteBaseVal 7;
BA_ "Description" SG_ 2328016130 VCU_DteBaseVal "Maximum Drivable Distance_Adaption";
BA_ "Version" SG_ 2328016130 VCU_AvnDteOnCalcSta "19.03.03";
BA_ "RoutingFactor" SG_ 2328016130 VCU_AvnDteOnCalcSta 0;
BA_ "UserSigValidity" SG_ 2328016130 VCU_AvnDteOnCalcSta 7;
BA_ "Description" SG_ 2328016130 VCU_AvnDteOnCalcSta "DTE calculation status";
BA_ "Version" SG_ 2328016130 VCU_SbwWarnMsgSta "19.06.02";
BA_ "RoutingFactor" SG_ 2328016130 VCU_SbwWarnMsgSta 0;
BA_ "UserSigValidity" SG_ 2328016130 VCU_SbwWarnMsgSta 7;
BA_ "Description" SG_ 2328016130 VCU_SbwWarnMsgSta "SBW Warning Message";
BA_ "Version" SG_ 2328016130 VCU_DteNaviRouteVal "19.03.03";
BA_ "RoutingFactor" SG_ 2328016130 VCU_DteNaviRouteVal 0;
BA_ "UserSigValidity" SG_ 2328016130 VCU_DteNaviRouteVal 7;
BA_ "Description" SG_ 2328016130 VCU_DteNaviRouteVal "Drivable distance for calculation AVN DTE";
BA_ "Version" SG_ 2328016130 VCU_DteAddVal "19.03.03";
BA_ "RoutingFactor" SG_ 2328016130 VCU_DteAddVal 0;
BA_ "UserSigValidity" SG_ 2328016130 VCU_DteAddVal 7;
BA_ "Description" SG_ 2328016130 VCU_DteAddVal "Added Drivable Distance by DATC Off";
BA_ "Version" SG_ 2328016130 VCU_PwrGaugeVal "19.03.03";
BA_ "RoutingFactor" SG_ 2328016130 VCU_PwrGaugeVal 0;
BA_ "UserSigValidity" SG_ 2328016130 VCU_PwrGaugeVal 7;
BA_ "Description" SG_ 2328016130 VCU_PwrGaugeVal "Motor Torque Ratio To Cluster

:VCU send this signal to cluster to show motor power status";
BA_ "Version" SG_ 2328016130 VCU_EnergyFlowSta "20.09.00";
BA_ "RoutingFactor" SG_ 2328016130 VCU_EnergyFlowSta 0;
BA_ "UserSigValidity" SG_ 2328016130 VCU_EnergyFlowSta 7;
BA_ "Description" SG_ 2328016130 VCU_EnergyFlowSta "Energy Flow Display Status";
BA_ "Version" SG_ 2328016130 VCU_SbwWarnSndSta "19.06.02";
BA_ "RoutingFactor" SG_ 2328016130 VCU_SbwWarnSndSta 0;
BA_ "UserSigValidity" SG_ 2328016130 VCU_SbwWarnSndSta 7;
BA_ "Description" SG_ 2328016130 VCU_SbwWarnSndSta "SBW Warning Sound";
BA_ "Version" SG_ 2328016130 VCU_DteLowBoundVal "22.11.03";
BA_ "RoutingFactor" SG_ 2328016130 VCU_DteLowBoundVal 0;
BA_ "UserSigValidity" SG_ 2328016130 VCU_DteLowBoundVal 7;
BA_ "Description" SG_ 2328016130 VCU_DteLowBoundVal "DTE Low Boundary Value

- Physical value min. : 0 (0x0)

- Physical value max. : 2047 (0x7FF)";
BA_ "Version" SG_ 2328016130 VCU_DteInfoPageSta "22.11.09";
BA_ "RoutingFactor" SG_ 2328016130 VCU_DteInfoPageSta 0;
BA_ "UserSigValidity" SG_ 2328016130 VCU_DteInfoPageSta 7;
BA_ "Description" SG_ 2328016130 VCU_DteInfoPageSta "DTE Information Page State";
BA_ "Version" SG_ 2328016131 VCU_TgSocDteAcChgVal "19.03.03";
BA_ "RoutingFactor" SG_ 2328016131 VCU_TgSocDteAcChgVal 0;
BA_ "UserSigValidity" SG_ 2328016131 VCU_TgSocDteAcChgVal 7;
BA_ "Description" SG_ 2328016131 VCU_TgSocDteAcChgVal "Estimated DTE for slow charger(SC/AC) target SOC";
BA_ "Version" SG_ 2328016131 VCU_TgSocDteDcChgVal "19.03.03";
BA_ "RoutingFactor" SG_ 2328016131 VCU_TgSocDteDcChgVal 0;
BA_ "UserSigValidity" SG_ 2328016131 VCU_TgSocDteDcChgVal 7;
BA_ "Description" SG_ 2328016131 VCU_TgSocDteDcChgVal "Estimated DTE for fast charger(QC/DC) target SOC";
BA_ "Version" SG_ 2328016131 VCU_DistFromRegenDispReq "19.03.03";
BA_ "RoutingFactor" SG_ 2328016131 VCU_DistFromRegenDispReq 0;
BA_ "UserSigValidity" SG_ 2328016131 VCU_DistFromRegenDispReq 7;
BA_ "Description" SG_ 2328016131 VCU_DistFromRegenDispReq "Distance from Regeneration Display status";
BA_ "Version" SG_ 2328016131 VCU_DistFromRegenVal "19.03.03";
BA_ "RoutingFactor" SG_ 2328016131 VCU_DistFromRegenVal 0;
BA_ "UserSigValidity" SG_ 2328016131 VCU_DistFromRegenVal 7;
BA_ "Description" SG_ 2328016131 VCU_DistFromRegenVal "DTE Increment at Regeneration";
BA_ "Version" SG_ 2328016131 VCU_DteHiBoundVal "22.11.03";
BA_ "RoutingFactor" SG_ 2328016131 VCU_DteHiBoundVal 0;
BA_ "UserSigValidity" SG_ 2328016131 VCU_DteHiBoundVal 7;
BA_ "Description" SG_ 2328016131 VCU_DteHiBoundVal "DTE High Boundary Value

- Physical value min. : 0 (0x0)

- Physical value max. : 2047 (0x7FF)";
BA_ "Version" SG_ 2328016131 VCU_DteGaugePosVal "22.11.03";
BA_ "RoutingFactor" SG_ 2328016131 VCU_DteGaugePosVal 0;
BA_ "UserSigValidity" SG_ 2328016131 VCU_DteGaugePosVal 7;
BA_ "TimeoutValue" SG_ 2328016131 VCU_DteGaugePosVal "7F";
BA_ "Description" SG_ 2328016131 VCU_DteGaugePosVal "DTE Gauge Position Value

- 0x7F : 127 (Invalid)

- 0x0~0x78 : 0~120

- 0x79~0x7E : 121~126 (RESERVED)

- Physical value min. : 0 -10 = -10 (0x0)

- Physical value max. : 120 - 10 = 110 (0x78)";
BA_ "Version" SG_ 2328016131 VCU_LowSocDispSt1PcVal "22.10.20";
BA_ "RoutingFactor" SG_ 2328016131 VCU_LowSocDispSt1PcVal 0;
BA_ "UserSigValidity" SG_ 2328016131 VCU_LowSocDispSt1PcVal 7;
BA_ "Description" SG_ 2328016131 VCU_LowSocDispSt1PcVal "VCU_LowSocDisplayPercentValue_Step1 (0~100%)";
BA_ "Version" SG_ 200 CF_AVN_ADrLNValueSet_2 "21.01.06";
BA_ "RoutingFactor" SG_ 200 CF_AVN_ADrLNValueSet_2 0;
BA_ "UserSigValidity" SG_ 200 CF_AVN_ADrLNValueSet_2 3;
BA_ "GenSigSendType" SG_ 200 CF_AVN_ADrLNValueSet_2 4;
BA_ "Description" SG_ 200 CF_AVN_ADrLNValueSet_2 "USM Reqeust for Auto Door Lock";
BA_ "Version" SG_ 200 CF_AVN_FCA_JC_OnOffEquipNvalueSe "20.12.00";
BA_ "RoutingFactor" SG_ 200 CF_AVN_FCA_JC_OnOffEquipNvalueSe 0;
BA_ "UserSigValidity" SG_ 200 CF_AVN_FCA_JC_OnOffEquipNvalueSe 3;
BA_ "GenSigSendType" SG_ 200 CF_AVN_FCA_JC_OnOffEquipNvalueSe 4;
BA_ "Description" SG_ 200 CF_AVN_FCA_JC_OnOffEquipNvalueSe "USM Set signal for Forward Corss-traffic";
BA_ "SystemSignalLongSymbol" SG_ 200 CF_AVN_FCA_JC_OnOffEquipNvalueSe "CF_AVN_FCA_JC_OnOffEquipNvalueSet";
BA_ "Version" SG_ 200 CF_AVN_FCA_FrSdOnOffEquipNvalueS "20.12.00";
BA_ "RoutingFactor" SG_ 200 CF_AVN_FCA_FrSdOnOffEquipNvalueS 0;
BA_ "UserSigValidity" SG_ 200 CF_AVN_FCA_FrSdOnOffEquipNvalueS 3;
BA_ "GenSigSendType" SG_ 200 CF_AVN_FCA_FrSdOnOffEquipNvalueS 4;
BA_ "Description" SG_ 200 CF_AVN_FCA_FrSdOnOffEquipNvalueS "USM Set signal for Forward/Side Safety";
BA_ "SystemSignalLongSymbol" SG_ 200 CF_AVN_FCA_FrSdOnOffEquipNvalueS "CF_AVN_FCA_FrSdOnOffEquipNvalueSet";
BA_ "Version" SG_ 200 CF_AVN_LKA_OnOffEquip2NvalueSet "20.12.00";
BA_ "RoutingFactor" SG_ 200 CF_AVN_LKA_OnOffEquip2NvalueSet 0;
BA_ "UserSigValidity" SG_ 200 CF_AVN_LKA_OnOffEquip2NvalueSet 3;
BA_ "GenSigSendType" SG_ 200 CF_AVN_LKA_OnOffEquip2NvalueSet 4;
BA_ "Description" SG_ 200 CF_AVN_LKA_OnOffEquip2NvalueSet "USM Set Signal for Lane safety";
BA_ "Version" SG_ 200 CF_AVN_BCA_OnOffEquip2NvalueSet "20.12.00";
BA_ "RoutingFactor" SG_ 200 CF_AVN_BCA_OnOffEquip2NvalueSet 0;
BA_ "UserSigValidity" SG_ 200 CF_AVN_BCA_OnOffEquip2NvalueSet 3;
BA_ "GenSigSendType" SG_ 200 CF_AVN_BCA_OnOffEquip2NvalueSet 4;
BA_ "Description" SG_ 200 CF_AVN_BCA_OnOffEquip2NvalueSet "USM Set signal for Side/Rear Safety";
BA_ "Version" SG_ 200 CF_AVN_BVM_OnOffEquipNvalueSet "20.12.00";
BA_ "RoutingFactor" SG_ 200 CF_AVN_BVM_OnOffEquipNvalueSet 0;
BA_ "UserSigValidity" SG_ 200 CF_AVN_BVM_OnOffEquipNvalueSet 3;
BA_ "GenSigSendType" SG_ 200 CF_AVN_BVM_OnOffEquipNvalueSet 4;
BA_ "Description" SG_ 200 CF_AVN_BVM_OnOffEquipNvalueSet "USM Set signal for Blind Spot View";
BA_ "Version" SG_ 200 CF_AVN_SEA_OnOffEquip3NvalueSet "20.12.00";
BA_ "RoutingFactor" SG_ 200 CF_AVN_SEA_OnOffEquip3NvalueSet 0;
BA_ "UserSigValidity" SG_ 200 CF_AVN_SEA_OnOffEquip3NvalueSet 3;
BA_ "GenSigSendType" SG_ 200 CF_AVN_SEA_OnOffEquip3NvalueSet 4;
BA_ "Description" SG_ 200 CF_AVN_SEA_OnOffEquip3NvalueSet "Usm Set signal for safety exit assist";
BA_ "Version" SG_ 200 CF_AVN_BodySpprtSet_AST "20.10.02";
BA_ "RoutingFactor" SG_ 200 CF_AVN_BodySpprtSet_AST 0;
BA_ "UserSigValidity" SG_ 200 CF_AVN_BodySpprtSet_AST 3;
BA_ "GenSigStartValue" SG_ 200 CF_AVN_BodySpprtSet_AST 3;
BA_ "GenSigSendType" SG_ 200 CF_AVN_BodySpprtSet_AST 4;
BA_ "Description" SG_ 200 CF_AVN_BodySpprtSet_AST "Ergo-Motion Seat Smart Posture Assist";
BA_ "Version" SG_ 200 CF_AVN_SEW_OnOffEquip3NvalueSet "20.12.00";
BA_ "RoutingFactor" SG_ 200 CF_AVN_SEW_OnOffEquip3NvalueSet 0;
BA_ "UserSigValidity" SG_ 200 CF_AVN_SEW_OnOffEquip3NvalueSet 3;
BA_ "GenSigSendType" SG_ 200 CF_AVN_SEW_OnOffEquip3NvalueSet 4;
BA_ "Description" SG_ 200 CF_AVN_SEW_OnOffEquip3NvalueSet "Usm Set signal for Safety exit warning";
BA_ "Version" SG_ 200 CF_AVN_HudImsAutoSave "20.12.05";
BA_ "RoutingFactor" SG_ 200 CF_AVN_HudImsAutoSave 0;
BA_ "UserSigValidity" SG_ 200 CF_AVN_HudImsAutoSave 3;
BA_ "GenSigSendType" SG_ 200 CF_AVN_HudImsAutoSave 4;
BA_ "Description" SG_ 200 CF_AVN_HudImsAutoSave "USM request for auto save HUD setting with IMS";
BA_ "Version" SG_ 200 USM_PwrDrBuzzerNValueSet "21.01.06";
BA_ "RoutingFactor" SG_ 200 USM_PwrDrBuzzerNValueSet 0;
BA_ "UserSigValidity" SG_ 200 USM_PwrDrBuzzerNValueSet 3;
BA_ "GenSigSendType" SG_ 200 USM_PwrDrBuzzerNValueSet 4;
BA_ "Description" SG_ 200 USM_PwrDrBuzzerNValueSet "USM Request for Power Door Buzzer";
BA_ "Version" SG_ 200 CF_AVN_DWLNValueSet "21.01.01";
BA_ "RoutingFactor" SG_ 200 CF_AVN_DWLNValueSet 0;
BA_ "UserSigValidity" SG_ 200 CF_AVN_DWLNValueSet 3;
BA_ "GenSigSendType" SG_ 200 CF_AVN_DWLNValueSet 4;
BA_ "Description" SG_ 200 CF_AVN_DWLNValueSet "Request for USM Dynamic Welcome Light";
BA_ "Version" SG_ 200 CF_AVN_AirSptTimeNValueSet_AST "20.10.02";
BA_ "RoutingFactor" SG_ 200 CF_AVN_AirSptTimeNValueSet_AST 0;
BA_ "UserSigValidity" SG_ 200 CF_AVN_AirSptTimeNValueSet_AST 3;
BA_ "GenSigStartValue" SG_ 200 CF_AVN_AirSptTimeNValueSet_AST 7;
BA_ "GenSigSendType" SG_ 200 CF_AVN_AirSptTimeNValueSet_AST 4;
BA_ "Description" SG_ 200 CF_AVN_AirSptTimeNValueSet_AST "Ergo-Motion Seat Comfortable Stretch Operational Time";
BA_ "Version" SG_ 200 CF_AVN_AirSptStrNValue_AST "20.10.02";
BA_ "RoutingFactor" SG_ 200 CF_AVN_AirSptStrNValue_AST 0;
BA_ "UserSigValidity" SG_ 200 CF_AVN_AirSptStrNValue_AST 3;
BA_ "GenSigStartValue" SG_ 200 CF_AVN_AirSptStrNValue_AST 3;
BA_ "GenSigSendType" SG_ 200 CF_AVN_AirSptStrNValue_AST 4;
BA_ "Description" SG_ 200 CF_AVN_AirSptStrNValue_AST "Ergo-Motion Seat Comfortable Stretch Strong/Normal";
BA_ "Version" SG_ 200 CF_AVN_SeatDrvModNvalueSet_AST "20.12.00";
BA_ "RoutingFactor" SG_ 200 CF_AVN_SeatDrvModNvalueSet_AST 0;
BA_ "UserSigValidity" SG_ 200 CF_AVN_SeatDrvModNvalueSet_AST 3;
BA_ "GenSigStartValue" SG_ 200 CF_AVN_SeatDrvModNvalueSet_AST 3;
BA_ "GenSigSendType" SG_ 200 CF_AVN_SeatDrvModNvalueSet_AST 4;
BA_ "Description" SG_ 200 CF_AVN_SeatDrvModNvalueSet_AST "Ergo-Motion Seat Smart Support";
BA_ "Version" SG_ 200 CF_AVN_TPMS_TireReplaceNValueSet "20.12.04";
BA_ "RoutingFactor" SG_ 200 CF_AVN_TPMS_TireReplaceNValueSet 0;
BA_ "UserSigValidity" SG_ 200 CF_AVN_TPMS_TireReplaceNValueSet 3;
BA_ "GenSigSendType" SG_ 200 CF_AVN_TPMS_TireReplaceNValueSet 4;
BA_ "Description" SG_ 200 CF_AVN_TPMS_TireReplaceNValueSet "USM Set Signal for Standard Tire to Wnter Tire";
BA_ "Version" SG_ 200 CF_AVN_TowModeSet "20.12.04";
BA_ "RoutingFactor" SG_ 200 CF_AVN_TowModeSet 0;
BA_ "UserSigValidity" SG_ 200 CF_AVN_TowModeSet 3;
BA_ "GenSigSendType" SG_ 200 CF_AVN_TowModeSet 4;
BA_ "Description" SG_ 200 CF_AVN_TowModeSet "USM Set signal For TowMode";
BA_ "Version" SG_ 200 USM_PwrDrCloseByBraekNValueSet "21.01.06";
BA_ "RoutingFactor" SG_ 200 USM_PwrDrCloseByBraekNValueSet 0;
BA_ "UserSigValidity" SG_ 200 USM_PwrDrCloseByBraekNValueSet 3;
BA_ "GenSigSendType" SG_ 200 USM_PwrDrCloseByBraekNValueSet 4;
BA_ "Description" SG_ 200 USM_PwrDrCloseByBraekNValueSet "USM Reqeust for Power Door Close by Brake";
BA_ "Version" SG_ 200 CF_AVN_ISLANAOffstNvalueSet "21.03.10";
BA_ "RoutingFactor" SG_ 200 CF_AVN_ISLANAOffstNvalueSet 0;
BA_ "UserSigValidity" SG_ 200 CF_AVN_ISLANAOffstNvalueSet 3;
BA_ "GenSigSendType" SG_ 200 CF_AVN_ISLANAOffstNvalueSet 4;
BA_ "Description" SG_ 200 CF_AVN_ISLANAOffstNvalueSet "Control ISLA offset on USM Fucntion (North America)";
BA_ "Version" SG_ 200 CF_Gway_WPC2_NValueSet "22.02.05";
BA_ "RoutingFactor" SG_ 200 CF_Gway_WPC2_NValueSet 0;
BA_ "UserSigValidity" SG_ 200 CF_Gway_WPC2_NValueSet 3;
BA_ "GenSigSendType" SG_ 200 CF_Gway_WPC2_NValueSet 4;
BA_ "Description" SG_ 200 CF_Gway_WPC2_NValueSet "USM Set signal for 2nd WPC setting";
BA_ "Version" SG_ 200 USM_DrvGhostDoorReq "21.03.11";
BA_ "RoutingFactor" SG_ 200 USM_DrvGhostDoorReq 0;
BA_ "UserSigValidity" SG_ 200 USM_DrvGhostDoorReq 3;
BA_ "GenSigSendType" SG_ 200 USM_DrvGhostDoorReq 4;
BA_ "Description" SG_ 200 USM_DrvGhostDoorReq "USM Request for Driver Door Ghost Door Closing On/Off";
BA_ "Version" SG_ 200 USM_AstGhostDoorReq "21.03.11";
BA_ "RoutingFactor" SG_ 200 USM_AstGhostDoorReq 0;
BA_ "UserSigValidity" SG_ 200 USM_AstGhostDoorReq 3;
BA_ "GenSigSendType" SG_ 200 USM_AstGhostDoorReq 4;
BA_ "Description" SG_ 200 USM_AstGhostDoorReq "USM Request for Assistant Ghost Door Closing On/Off";
BA_ "Version" SG_ 200 USM_RLGhostDoorReq "21.03.11";
BA_ "RoutingFactor" SG_ 200 USM_RLGhostDoorReq 0;
BA_ "UserSigValidity" SG_ 200 USM_RLGhostDoorReq 3;
BA_ "GenSigSendType" SG_ 200 USM_RLGhostDoorReq 4;
BA_ "Description" SG_ 200 USM_RLGhostDoorReq "USM Request for Rear Left Ghost Door Closing On/Off";
BA_ "Version" SG_ 200 USM_RRGhostDoorReq "21.03.11";
BA_ "RoutingFactor" SG_ 200 USM_RRGhostDoorReq 0;
BA_ "UserSigValidity" SG_ 200 USM_RRGhostDoorReq 3;
BA_ "GenSigSendType" SG_ 200 USM_RRGhostDoorReq 4;
BA_ "Description" SG_ 200 USM_RRGhostDoorReq "USM Request for Rear Right Ghost Door Closing On/Off";
BA_ "Version" SG_ 200 CF_AVN_FCA_FrOnOffEquipNvalueSet "20.12.00";
BA_ "RoutingFactor" SG_ 200 CF_AVN_FCA_FrOnOffEquipNvalueSet 0;
BA_ "UserSigValidity" SG_ 200 CF_AVN_FCA_FrOnOffEquipNvalueSet 3;
BA_ "GenSigSendType" SG_ 200 CF_AVN_FCA_FrOnOffEquipNvalueSet 4;
BA_ "Description" SG_ 200 CF_AVN_FCA_FrOnOffEquipNvalueSet "USM Set Signal for Forward Safety";
BA_ "Version" SG_ 200 CF_AVN_FCA_WarnTimeNvalueSet "20.12.00";
BA_ "RoutingFactor" SG_ 200 CF_AVN_FCA_WarnTimeNvalueSet 0;
BA_ "UserSigValidity" SG_ 200 CF_AVN_FCA_WarnTimeNvalueSet 3;
BA_ "GenSigSendType" SG_ 200 CF_AVN_FCA_WarnTimeNvalueSet 4;
BA_ "Description" SG_ 200 CF_AVN_FCA_WarnTimeNvalueSet "USM Set signal for Forward Warntime";
BA_ "Version" SG_ 1159 C_AstRclBwdSw_HU "22.06.01";
BA_ "UserSigValidity" SG_ 1159 C_AstRclBwdSw_HU 0;
BA_ "GenSigSendType" SG_ 1159 C_AstRclBwdSw_HU 4;
BA_ "Version" SG_ 1159 C_AstHeightUpSw_HU "22.06.01";
BA_ "UserSigValidity" SG_ 1159 C_AstHeightUpSw_HU 0;
BA_ "GenSigSendType" SG_ 1159 C_AstHeightUpSw_HU 4;
BA_ "Version" SG_ 1159 C_AstTiltDnSw_HU "22.06.01";
BA_ "UserSigValidity" SG_ 1159 C_AstTiltDnSw_HU 0;
BA_ "GenSigSendType" SG_ 1159 C_AstTiltDnSw_HU 4;
BA_ "Version" SG_ 1159 C_AstTiltUpSw_HU "22.06.01";
BA_ "UserSigValidity" SG_ 1159 C_AstTiltUpSw_HU 0;
BA_ "GenSigSendType" SG_ 1159 C_AstTiltUpSw_HU 4;
BA_ "Version" SG_ 1159 C_AstLumbarDefSw_HU "22.06.01";
BA_ "UserSigValidity" SG_ 1159 C_AstLumbarDefSw_HU 0;
BA_ "GenSigSendType" SG_ 1159 C_AstLumbarDefSw_HU 4;
BA_ "Version" SG_ 1159 C_AstLumbarLowSw_HU "22.06.01";
BA_ "UserSigValidity" SG_ 1159 C_AstLumbarLowSw_HU 0;
BA_ "GenSigSendType" SG_ 1159 C_AstLumbarLowSw_HU 4;
BA_ "Version" SG_ 1159 C_AstRclFwdSw_HU "22.06.01";
BA_ "UserSigValidity" SG_ 1159 C_AstRclFwdSw_HU 0;
BA_ "GenSigSendType" SG_ 1159 C_AstRclFwdSw_HU 4;
BA_ "Version" SG_ 1159 C_AstLumbarMidSw_HU "22.06.01";
BA_ "UserSigValidity" SG_ 1159 C_AstLumbarMidSw_HU 0;
BA_ "GenSigSendType" SG_ 1159 C_AstLumbarMidSw_HU 4;
BA_ "Version" SG_ 1159 C_AstLumbarUpSw_HU "22.06.01";
BA_ "UserSigValidity" SG_ 1159 C_AstLumbarUpSw_HU 0;
BA_ "GenSigSendType" SG_ 1159 C_AstLumbarUpSw_HU 4;
BA_ "Version" SG_ 1159 C_RRSlideFwdSw_HU "22.06.01";
BA_ "UserSigValidity" SG_ 1159 C_RRSlideFwdSw_HU 0;
BA_ "GenSigSendType" SG_ 1159 C_RRSlideFwdSw_HU 4;
BA_ "Version" SG_ 1159 C_RRSlideBwdSw_HU "22.06.01";
BA_ "UserSigValidity" SG_ 1159 C_RRSlideBwdSw_HU 0;
BA_ "GenSigSendType" SG_ 1159 C_RRSlideBwdSw_HU 4;
BA_ "Version" SG_ 1159 C_RLSlideFwdSw_HU "22.06.01";
BA_ "UserSigValidity" SG_ 1159 C_RLSlideFwdSw_HU 0;
BA_ "GenSigSendType" SG_ 1159 C_RLSlideFwdSw_HU 4;
BA_ "Version" SG_ 1159 C_RLSlideBwdSw_HU "22.06.01";
BA_ "UserSigValidity" SG_ 1159 C_RLSlideBwdSw_HU 0;
BA_ "GenSigSendType" SG_ 1159 C_RLSlideBwdSw_HU 4;
BA_ "Version" SG_ 1159 C_AstSlideBwdSw_HU "22.06.01";
BA_ "UserSigValidity" SG_ 1159 C_AstSlideBwdSw_HU 0;
BA_ "GenSigSendType" SG_ 1159 C_AstSlideBwdSw_HU 4;
BA_ "Version" SG_ 1159 C_AstSlideFwdSw_HU "22.06.01";
BA_ "UserSigValidity" SG_ 1159 C_AstSlideFwdSw_HU 0;
BA_ "GenSigSendType" SG_ 1159 C_AstSlideFwdSw_HU 4;
BA_ "Version" SG_ 1159 C_AstHeightDnSw_HU "22.06.01";
BA_ "UserSigValidity" SG_ 1159 C_AstHeightDnSw_HU 0;
BA_ "GenSigSendType" SG_ 1159 C_AstHeightDnSw_HU 4;
BA_ "Version" SG_ 197 C_RLLegSupFwdSw_HU "22.07.05";
BA_ "RoutingFactor" SG_ 197 C_RLLegSupFwdSw_HU 0;
BA_ "UserSigValidity" SG_ 197 C_RLLegSupFwdSw_HU 0;
BA_ "GenSigSendType" SG_ 197 C_RLLegSupFwdSw_HU 4;
BA_ "Version" SG_ 197 C_RLLegSupBwdSw_HU "22.07.05";
BA_ "RoutingFactor" SG_ 197 C_RLLegSupBwdSw_HU 0;
BA_ "UserSigValidity" SG_ 197 C_RLLegSupBwdSw_HU 0;
BA_ "GenSigSendType" SG_ 197 C_RLLegSupBwdSw_HU 4;
BA_ "Version" SG_ 197 C_RLLegSupUpSw_HU "22.07.05";
BA_ "RoutingFactor" SG_ 197 C_RLLegSupUpSw_HU 0;
BA_ "UserSigValidity" SG_ 197 C_RLLegSupUpSw_HU 0;
BA_ "GenSigSendType" SG_ 197 C_RLLegSupUpSw_HU 4;
BA_ "Version" SG_ 197 C_RLLegSupDnSw_HU "22.07.05";
BA_ "RoutingFactor" SG_ 197 C_RLLegSupDnSw_HU 0;
BA_ "UserSigValidity" SG_ 197 C_RLLegSupDnSw_HU 0;
BA_ "GenSigSendType" SG_ 197 C_RLLegSupDnSw_HU 4;
BA_ "Version" SG_ 1165 RLMSS_OnOffBtn_AVN "23.05.01";
BA_ "RoutingFactor" SG_ 1165 RLMSS_OnOffBtn_AVN 0;
BA_ "UserSigValidity" SG_ 1165 RLMSS_OnOffBtn_AVN 1;
BA_ "GenSigSendType" SG_ 1165 RLMSS_OnOffBtn_AVN 4;
BA_ "Version" SG_ 2382595073 DATC_Crc7Val "21.09.03";
BA_ "UserSigValidity" SG_ 2382595073 DATC_Crc7Val 3;
BA_ "GenSigStartValue" SG_ 2382595073 DATC_Crc7Val 65535;
BA_ "GenSigSendType" SG_ 2382595073 DATC_Crc7Val 4;
BA_ "Description" SG_ 2382595073 DATC_Crc7Val "The data area for CRC calculation is based on the data length (DLC) of the message DB.

The CRC shall be calculated over the entire data block (excluding the CRC bytes) including the user data, alive counter and Data ID



- CRC Polynomial (0x1021) , Ini";
BA_ "Version" SG_ 2382595073 DATC_AlvCnt7Val "21.09.03";
BA_ "UserSigValidity" SG_ 2382595073 DATC_AlvCnt7Val 3;
BA_ "GenSigSendType" SG_ 2382595073 DATC_AlvCnt7Val 4;
BA_ "Description" SG_ 2382595073 DATC_AlvCnt7Val "For the first transmission request for a data element the counter shall be initialized with 0 and shall be incremented by 1 for every subsequent send request. 

When the counter reaches the maximum value(0xFF), then it shall restart with 0 for the next s";
BA_ "Version" SG_ 2382595073 DATC_FrDrvBlwDis "18.11.06";
BA_ "UserSigValidity" SG_ 2382595073 DATC_FrDrvBlwDis 7;
BA_ "GenSigSendType" SG_ 2382595073 DATC_FrDrvBlwDis 4;
BA_ "Description" SG_ 2382595073 DATC_FrDrvBlwDis "This signal indicates step of Front blower Graphic.

This signal occurs when Front Blower switch(button) is selected either manually or automatically.";
BA_ "Version" SG_ 2382595073 DATC_FrPsBlwDis "19.05.03";
BA_ "UserSigValidity" SG_ 2382595073 DATC_FrPsBlwDis 7;
BA_ "GenSigSendType" SG_ 2382595073 DATC_FrPsBlwDis 4;
BA_ "Version" SG_ 2382595073 DATC_DrvOnlyDis "17.11.00";
BA_ "UserSigValidity" SG_ 2382595073 DATC_DrvOnlyDis 6;
BA_ "GenSigSendType" SG_ 2382595073 DATC_DrvOnlyDis 4;
BA_ "Version" SG_ 2382595073 DATC_DiagCodeDis "22.03.04";
BA_ "UserSigValidity" SG_ 2382595073 DATC_DiagCodeDis 6;
BA_ "GenSigSendType" SG_ 2382595073 DATC_DiagCodeDis 4;
BA_ "Version" SG_ 2382595073 DATC_RrChgReqDis "17.11.00";
BA_ "UserSigValidity" SG_ 2382595073 DATC_RrChgReqDis 6;
BA_ "GenSigSendType" SG_ 2382595073 DATC_RrChgReqDis 4;
BA_ "Description" SG_ 2382595073 DATC_RrChgReqDis "This signal indicates to show Climate Pop-up screen.

This signal occurs when any kinds of climate switch(button)s are selected manually.";
BA_ "Version" SG_ 2382595073 DATC_RrClmtScrnDis "17.11.00";
BA_ "UserSigValidity" SG_ 2382595073 DATC_RrClmtScrnDis 6;
BA_ "GenSigSendType" SG_ 2382595073 DATC_RrClmtScrnDis 4;
BA_ "Description" SG_ 2382595073 DATC_RrClmtScrnDis "This signal indicates that screen change to Climate Full screen.



This signal occurs when Climate switch(button) is selected manually.";
BA_ "Version" SG_ 2382595073 DATC_AUTOStep "18.12.08";
BA_ "UserSigValidity" SG_ 2382595073 DATC_AUTOStep 7;
BA_ "GenSigSendType" SG_ 2382595073 DATC_AUTOStep 4;
BA_ "Description" SG_ 2382595073 DATC_AUTOStep "This signal indicates AUTO step status in case Multi Auto Blower type.";
BA_ "Version" SG_ 2382595073 DATC_IntakeDis "22.11.24";
BA_ "UserSigValidity" SG_ 2382595073 DATC_IntakeDis 7;
BA_ "GenSigSendType" SG_ 2382595073 DATC_IntakeDis 4;
BA_ "Description" SG_ 2382595073 DATC_IntakeDis "This signal indicates intake indicator & display";
BA_ "Version" SG_ 2382595073 DATC_MultiAirModSta "18.12.08";
BA_ "UserSigValidity" SG_ 2382595073 DATC_MultiAirModSta 7;
BA_ "GenSigSendType" SG_ 2382595073 DATC_MultiAirModSta 4;
BA_ "Description" SG_ 2382595073 DATC_MultiAirModSta "This signal indicates MultiAirModeStatus";
BA_ "Version" SG_ 1167 ICU_Crc11Val "21.09.03";
BA_ "RoutingFactor" SG_ 1167 ICU_Crc11Val 0;
BA_ "UserSigValidity" SG_ 1167 ICU_Crc11Val 0;
BA_ "GenSigSendType" SG_ 1167 ICU_Crc11Val 4;
BA_ "Description" SG_ 1167 ICU_Crc11Val "The data area for CRC calculation is based on the data length (DLC) of the message DB.

The CRC shall be calculated over the entire data block (excluding the CRC bytes) including the user data, alive counter and Data ID 

 

- CRC Polynomial (0x1D) , Ini";
BA_ "Version" SG_ 1167 Bat_dischrg "21.11.00";
BA_ "RoutingFactor" SG_ 1167 Bat_dischrg 0;
BA_ "UserSigValidity" SG_ 1167 Bat_dischrg 3;
BA_ "GenSigSendType" SG_ 1167 Bat_dischrg 4;
BA_ "Description" SG_ 1167 Bat_dischrg "Battery discharge notification flag";
BA_ "Version" SG_ 1167 ICU_AlvCnt11Val "21.09.03";
BA_ "RoutingFactor" SG_ 1167 ICU_AlvCnt11Val 0;
BA_ "UserSigValidity" SG_ 1167 ICU_AlvCnt11Val 0;
BA_ "GenSigSendType" SG_ 1167 ICU_AlvCnt11Val 4;
BA_ "Description" SG_ 1167 ICU_AlvCnt11Val "For the first transmission request for a data element the counter shall be initialized with 0 and shall be incremented by 1

for every subsequent send request. When the counter reaches the maximum value(0xE), then it shall restart with 0 for the next sen";
BA_ "Version" SG_ 1167 Batt_SoCWarningValue "21.11.00";
BA_ "RoutingFactor" SG_ 1167 Batt_SoCWarningValue 0;
BA_ "UserSigValidity" SG_ 1167 Batt_SoCWarningValue 0;
BA_ "GenSigStartValue" SG_ 1167 Batt_SoCWarningValue 255;
BA_ "GenSigSendType" SG_ 1167 Batt_SoCWarningValue 4;
BA_ "Description" SG_ 1167 Batt_SoCWarningValue "This signal is Battery SOC from battery sensor.";
BA_ "Version" SG_ 1167 C_StrgWhlHeatingOpt "23.02.02";
BA_ "RoutingFactor" SG_ 1167 C_StrgWhlHeatingOpt 0;
BA_ "UserSigValidity" SG_ 1167 C_StrgWhlHeatingOpt 0;
BA_ "GenSigSendType" SG_ 1167 C_StrgWhlHeatingOpt 4;
BA_ "Description" SG_ 1167 C_StrgWhlHeatingOpt "Steering wheel heating option signal";
BA_ "Version" SG_ 1167 C_StrgWhlHeatingSWInf "19.11.11";
BA_ "RoutingFactor" SG_ 1167 C_StrgWhlHeatingSWInf 0;
BA_ "UserSigValidity" SG_ 1167 C_StrgWhlHeatingSWInf 3;
BA_ "GenSigSendType" SG_ 1167 C_StrgWhlHeatingSWInf 4;
BA_ "Description" SG_ 1167 C_StrgWhlHeatingSWInf "Steering wheel heating Step information signal";
BA_ "Version" SG_ 1167 ICU_BattAutoCutPreWrng "20.04.06";
BA_ "RoutingFactor" SG_ 1167 ICU_BattAutoCutPreWrng 0;
BA_ "UserSigValidity" SG_ 1167 ICU_BattAutoCutPreWrng 0;
BA_ "GenSigStartValue" SG_ 1167 ICU_BattAutoCutPreWrng 3;
BA_ "GenSigSendType" SG_ 1167 ICU_BattAutoCutPreWrng 4;
BA_ "Description" SG_ 1167 ICU_BattAutoCutPreWrng "This is a warning signal before blocking the dark current of the ICU by the battery SOC.";
BA_ "Version" SG_ 1167 IGN_AutoOff_WarnSta_CLU "21.11.00";
BA_ "RoutingFactor" SG_ 1167 IGN_AutoOff_WarnSta_CLU 0;
BA_ "UserSigValidity" SG_ 1167 IGN_AutoOff_WarnSta_CLU 3;
BA_ "GenSigSendType" SG_ 1167 IGN_AutoOff_WarnSta_CLU 4;
BA_ "Description" SG_ 1167 IGN_AutoOff_WarnSta_CLU "This signal is for battery discharge warning (engine not running && IGN/ACC on)

To prevent battery discharge, ICU requests the Cluster to display warning and requests IBU to turn IGN/ACC off.";
BA_ "Version" SG_ 1167 PDC_BatPwrStateClassA "23.07.06";
BA_ "RoutingFactor" SG_ 1167 PDC_BatPwrStateClassA 0;
BA_ "UserSigValidity" SG_ 1167 PDC_BatPwrStateClassA 0;
BA_ "GenSigSendType" SG_ 1167 PDC_BatPwrStateClassA 4;
BA_ "Description" SG_ 1167 PDC_BatPwrStateClassA "This signal is used to inform whether the power state is good for the operation of the function using the low voltage.

0x1 : power state level is low

0x2: power staest level is good(high)";
BA_ "Version" SG_ 1167 PDC_BatPwrStateClassB "23.07.06";
BA_ "RoutingFactor" SG_ 1167 PDC_BatPwrStateClassB 0;
BA_ "UserSigValidity" SG_ 1167 PDC_BatPwrStateClassB 0;
BA_ "GenSigSendType" SG_ 1167 PDC_BatPwrStateClassB 4;
BA_ "Description" SG_ 1167 PDC_BatPwrStateClassB "This signal is used to inform whether the power state is good for the operation of the function using the low voltage.

0x1 : power state level is low

0x2: power staest level is good(high)";
BA_ "Version" SG_ 1167 PDC_BatPwrStateClassC "23.07.06";
BA_ "RoutingFactor" SG_ 1167 PDC_BatPwrStateClassC 0;
BA_ "UserSigValidity" SG_ 1167 PDC_BatPwrStateClassC 0;
BA_ "GenSigSendType" SG_ 1167 PDC_BatPwrStateClassC 4;
BA_ "Description" SG_ 1167 PDC_BatPwrStateClassC "This signal is used to inform whether the power state is good for the operation of the function using the low voltage.

0x1 : power state level is low

0x2: power staest level is good(high)";
BA_ "Version" SG_ 1167 PDC_BatPwrClassOpt "23.07.05";
BA_ "RoutingFactor" SG_ 1167 PDC_BatPwrClassOpt 0;
BA_ "UserSigValidity" SG_ 1167 PDC_BatPwrClassOpt 0;
BA_ "GenSigSendType" SG_ 1167 PDC_BatPwrClassOpt 4;
BA_ "Description" SG_ 1167 PDC_BatPwrClassOpt "This signal informs which signal among soc and batpwrstateclass is regarded as the state of power.";
BA_ "Version" SG_ 1167 PLBMAvailableState "21.06.11";
BA_ "RoutingFactor" SG_ 1167 PLBMAvailableState 0;
BA_ "UserSigValidity" SG_ 1167 PLBMAvailableState 0;
BA_ "GenSigSendType" SG_ 1167 PLBMAvailableState 4;
BA_ "Description" SG_ 1167 PLBMAvailableState "Power supply Available status notification at PLBM. If this value is Set, BMS can request Discharge-request to PDC during parking mode";
BA_ "Version" SG_ 1167 PDC_LeadAcidBatType "23.06.02";
BA_ "RoutingFactor" SG_ 1167 PDC_LeadAcidBatType 0;
BA_ "UserSigValidity" SG_ 1167 PDC_LeadAcidBatType 0;
BA_ "GenSigSendType" SG_ 1167 PDC_LeadAcidBatType 4;
BA_ "Description" SG_ 1167 PDC_LeadAcidBatType "Lead Acid Battery Type Information

 - Validity

After EOL coding

 - Value Table

0x00:Not Applied

0x01:CMF 35Ah

0x02:CMF 40Ah

0x03:CMF 45Ah

0x04:CMF 50Ah

0x05:CMF 60Ah

0x06:CMF 68Ah

0x07:CMF 70Ah

0x08:CMF 80Ah

0x09:CMF 90Ah

0x0A:CMF 110Ah

0x";
BA_ "Version" SG_ 1167 IGN_AutoOff_WarnSta "21.11.00";
BA_ "RoutingFactor" SG_ 1167 IGN_AutoOff_WarnSta 0;
BA_ "UserSigValidity" SG_ 1167 IGN_AutoOff_WarnSta 3;
BA_ "GenSigSendType" SG_ 1167 IGN_AutoOff_WarnSta 4;
BA_ "Description" SG_ 1167 IGN_AutoOff_WarnSta "This signal is for battery discharge warning (engine not running && IGN/ACC on)

To prevent battery discharge, ICU requests the head unit to display warning and requests IBU to turn IGN/ACC off.";
BA_ "Version" SG_ 194 CF_LDW_OnOffEquip2NvalueSet "22.09.01";
BA_ "UserSigValidity" SG_ 194 CF_LDW_OnOffEquip2NvalueSet 3;
BA_ "GenSigSendType" SG_ 194 CF_LDW_OnOffEquip2NvalueSet 4;
BA_ "Description" SG_ 194 CF_LDW_OnOffEquip2NvalueSet "LDW USM Set signal";
BA_ "Version" SG_ 194 CF_AVN_TrnkTlgtAutoWashModeSet "22.12.04";
BA_ "UserSigValidity" SG_ 194 CF_AVN_TrnkTlgtAutoWashModeSet 3;
BA_ "GenSigSendType" SG_ 194 CF_AVN_TrnkTlgtAutoWashModeSet 4;
BA_ "Description" SG_ 194 CF_AVN_TrnkTlgtAutoWashModeSet "Auto Wash mode set for Trunk and Tailgate";
BA_ "Version" SG_ 194 CF_AVN_DrvArmRestHeatNValueSet "22.12.05";
BA_ "UserSigValidity" SG_ 194 CF_AVN_DrvArmRestHeatNValueSet 1;
BA_ "GenSigStartValue" SG_ 194 CF_AVN_DrvArmRestHeatNValueSet 3;
BA_ "GenSigSendType" SG_ 194 CF_AVN_DrvArmRestHeatNValueSet 4;
BA_ "Description" SG_ 194 CF_AVN_DrvArmRestHeatNValueSet "Set on/off the fucntion that the driver armreset warmer adjusts automatically based on driver seat warmer.";
BA_ "Version" SG_ 194 CF_AVN_AstArmRestHeatNValueSet "22.12.05";
BA_ "UserSigValidity" SG_ 194 CF_AVN_AstArmRestHeatNValueSet 1;
BA_ "GenSigStartValue" SG_ 194 CF_AVN_AstArmRestHeatNValueSet 3;
BA_ "GenSigSendType" SG_ 194 CF_AVN_AstArmRestHeatNValueSet 4;
BA_ "Description" SG_ 194 CF_AVN_AstArmRestHeatNValueSet "Set on/off the function that the front passenger(or assistant) armrest warmer adjusts automatically based on the front passenger seat warmer.";
BA_ "Version" SG_ 194 CF_AVN_RRArmRestHeatNValueSet "22.12.05";
BA_ "UserSigValidity" SG_ 194 CF_AVN_RRArmRestHeatNValueSet 1;
BA_ "GenSigStartValue" SG_ 194 CF_AVN_RRArmRestHeatNValueSet 3;
BA_ "GenSigSendType" SG_ 194 CF_AVN_RRArmRestHeatNValueSet 4;
BA_ "Description" SG_ 194 CF_AVN_RRArmRestHeatNValueSet "Set on/off the function that the rear right armrest warmer adjusts automatically based on the rear right seat warmer.";
BA_ "Version" SG_ 194 AVN_HudContentsADAS "22.10.19";
BA_ "UserSigValidity" SG_ 194 AVN_HudContentsADAS 3;
BA_ "GenSigSendType" SG_ 194 AVN_HudContentsADAS 4;
BA_ "Description" SG_ 194 AVN_HudContentsADAS "USM SetSignal for HUD Contents of ADAS";
BA_ "Version" SG_ 194 CF_AVN_RLArmRestHeatNValueSet "22.12.05";
BA_ "UserSigValidity" SG_ 194 CF_AVN_RLArmRestHeatNValueSet 1;
BA_ "GenSigStartValue" SG_ 194 CF_AVN_RLArmRestHeatNValueSet 3;
BA_ "GenSigSendType" SG_ 194 CF_AVN_RLArmRestHeatNValueSet 4;
BA_ "Description" SG_ 194 CF_AVN_RLArmRestHeatNValueSet "Set on/off the function that the rear left armrest warmer adjusts automatically based on the rear left seat warmer.";
BA_ "Version" SG_ 194 CF_AVN_AirSptStrNValue_VR "23.02.02";
BA_ "UserSigValidity" SG_ 194 CF_AVN_AirSptStrNValue_VR 3;
BA_ "GenSigStartValue" SG_ 194 CF_AVN_AirSptStrNValue_VR 3;
BA_ "GenSigSendType" SG_ 194 CF_AVN_AirSptStrNValue_VR 4;
BA_ "Version" SG_ 194 CF_AVN_AirSptTimeNValueSet_VR "23.02.02";
BA_ "UserSigValidity" SG_ 194 CF_AVN_AirSptTimeNValueSet_VR 3;
BA_ "GenSigStartValue" SG_ 194 CF_AVN_AirSptTimeNValueSet_VR 7;
BA_ "GenSigSendType" SG_ 194 CF_AVN_AirSptTimeNValueSet_VR 4;
BA_ "Version" SG_ 194 CF_AVN_AirSptMode_VR "23.02.02";
BA_ "UserSigValidity" SG_ 194 CF_AVN_AirSptMode_VR 3;
BA_ "GenSigStartValue" SG_ 194 CF_AVN_AirSptMode_VR 7;
BA_ "GenSigSendType" SG_ 194 CF_AVN_AirSptMode_VR 4;
BA_ "Version" SG_ 194 CF_AVN_MdLmpSpeechRecogNValueSet "24.05.00";
BA_ "UserSigValidity" SG_ 194 CF_AVN_MdLmpSpeechRecogNValueSet 3;
BA_ "GenSigSendType" SG_ 194 CF_AVN_MdLmpSpeechRecogNValueSet 4;
BA_ "Version" SG_ 194 AVN_HudContentsBCWUnderADAS "22.10.19";
BA_ "UserSigValidity" SG_ 194 AVN_HudContentsBCWUnderADAS 3;
BA_ "GenSigSendType" SG_ 194 AVN_HudContentsBCWUnderADAS 4;
BA_ "Description" SG_ 194 AVN_HudContentsBCWUnderADAS "HUD USM Set signal for BCW under ADAS";
BA_ "Version" SG_ 194 CF_AVN_ISLA2NvalueSet "23.04.00";
BA_ "UserSigValidity" SG_ 194 CF_AVN_ISLA2NvalueSet 3;
BA_ "GenSigSendType" SG_ 194 CF_AVN_ISLA2NvalueSet 4;
BA_ "Description" SG_ 194 CF_AVN_ISLA2NvalueSet "USM Set signal for New ISLA Function";
BA_ "Version" SG_ 194 C_TeleRRMsgOpCmdIBOX_0 "23.04.08";
BA_ "UserSigValidity" SG_ 194 C_TeleRRMsgOpCmdIBOX_0 1;
BA_ "GenSigSendType" SG_ 194 C_TeleRRMsgOpCmdIBOX_0 4;
BA_ "Description" SG_ 194 C_TeleRRMsgOpCmdIBOX_0 "Seat massage System RR On/Off";
BA_ "Version" SG_ 194 C_TeleRLMsgOpCmdIBOX_0 "23.04.08";
BA_ "UserSigValidity" SG_ 194 C_TeleRLMsgOpCmdIBOX_0 1;
BA_ "GenSigSendType" SG_ 194 C_TeleRLMsgOpCmdIBOX_0 4;
BA_ "Description" SG_ 194 C_TeleRLMsgOpCmdIBOX_0 "Seat Massage System RL On/Off";
BA_ "Version" SG_ 194 USM_AdasISLANACntryTglSet "23.05.01";
BA_ "UserSigValidity" SG_ 194 USM_AdasISLANACntryTglSet 3;
BA_ "GenSigSendType" SG_ 194 USM_AdasISLANACntryTglSet 4;
BA_ "Description" SG_ 194 USM_AdasISLANACntryTglSet "This signal is ISLA NA Toggle Set signal";
BA_ "Version" SG_ 194 USM_AdasISLANACntry1Set "23.06.00";
BA_ "UserSigValidity" SG_ 194 USM_AdasISLANACntry1Set 3;
BA_ "GenSigSendType" SG_ 194 USM_AdasISLANACntry1Set 4;
BA_ "Description" SG_ 194 USM_AdasISLANACntry1Set "This signal is ISLA country selection Set signal";
BA_ "Version" SG_ 194 CF_AVN_PMPDNvalueSet "23.06.00";
BA_ "UserSigValidity" SG_ 194 CF_AVN_PMPDNvalueSet 3;
BA_ "GenSigSendType" SG_ 194 CF_AVN_PMPDNvalueSet 4;
BA_ "Description" SG_ 194 CF_AVN_PMPDNvalueSet "USM PMPD Set signal";
BA_ "Version" SG_ 194 CF_AVN_LKAWrngVolNvalueSet_2 "23.07.05";
BA_ "UserSigValidity" SG_ 194 CF_AVN_LKAWrngVolNvalueSet_2 3;
BA_ "GenSigSendType" SG_ 194 CF_AVN_LKAWrngVolNvalueSet_2 4;
BA_ "Description" SG_ 194 CF_AVN_LKAWrngVolNvalueSet_2 "LKA warning volume usm set signal";
BA_ "Version" SG_ 194 CF_AVN_ActbolstersenNValue "24.07.02";
BA_ "UserSigValidity" SG_ 194 CF_AVN_ActbolstersenNValue 3;
BA_ "GenSigSendType" SG_ 194 CF_AVN_ActbolstersenNValue 4;
BA_ "Description" SG_ 194 CF_AVN_ActbolstersenNValue "This is USM signal  for seat active bolster sensitivity";
BA_ "Version" SG_ 1166 RRMSS_OnOffBtn_AVN "23.05.01";
BA_ "RoutingFactor" SG_ 1166 RRMSS_OnOffBtn_AVN 0;
BA_ "UserSigValidity" SG_ 1166 RRMSS_OnOffBtn_AVN 1;
BA_ "GenSigSendType" SG_ 1166 RRMSS_OnOffBtn_AVN 4;
BA_ "Version" SG_ 223 ALBCU_SmartCtrl_1h "20.10.02";
BA_ "RoutingFactor" SG_ 223 ALBCU_SmartCtrl_1h 0;
BA_ "UserSigValidity" SG_ 223 ALBCU_SmartCtrl_1h 1;
BA_ "GenSigSendType" SG_ 223 ALBCU_SmartCtrl_1h 4;
BA_ "Description" SG_ 223 ALBCU_SmartCtrl_1h "Smart Posture Adjust AVN Display (1hr)";
BA_ "Version" SG_ 223 ALBCU_SmartCtrl_2h "20.10.02";
BA_ "RoutingFactor" SG_ 223 ALBCU_SmartCtrl_2h 0;
BA_ "UserSigValidity" SG_ 223 ALBCU_SmartCtrl_2h 1;
BA_ "GenSigSendType" SG_ 223 ALBCU_SmartCtrl_2h 4;
BA_ "Description" SG_ 223 ALBCU_SmartCtrl_2h "Smart Posture Adjust AVN Display (2hr)";
BA_ "Version" SG_ 223 ALBCU_SmartCtrl_Status "20.10.02";
BA_ "RoutingFactor" SG_ 223 ALBCU_SmartCtrl_Status 0;
BA_ "UserSigValidity" SG_ 223 ALBCU_SmartCtrl_Status 1;
BA_ "GenSigSendType" SG_ 223 ALBCU_SmartCtrl_Status 4;
BA_ "Description" SG_ 223 ALBCU_SmartCtrl_Status "Smart Posture Adjust 2nd Interlocked Move AVN popup request";
BA_ "Version" SG_ 1171 RLPSM_SWVerMajor1 "21.07.00";
BA_ "RoutingFactor" SG_ 1171 RLPSM_SWVerMajor1 0;
BA_ "UserSigValidity" SG_ 1171 RLPSM_SWVerMajor1 0;
BA_ "GenSigSendType" SG_ 1171 RLPSM_SWVerMajor1 4;
BA_ "Description" SG_ 1171 RLPSM_SWVerMajor1 "Indicate the SCM software version as follows:

- The software version is displayed in three digits.

- The Major and Minor digits are separated by '.'

- Signal values are transmitted to ASCII codes.



¡Ø Example

RLPSM_SWVerMajor1 : 0x41 (HEX) -> ASCII";
BA_ "Version" SG_ 1171 RLPSM_SWVerMinor2 "20.04.06";
BA_ "RoutingFactor" SG_ 1171 RLPSM_SWVerMinor2 0;
BA_ "UserSigValidity" SG_ 1171 RLPSM_SWVerMinor2 0;
BA_ "GenSigSendType" SG_ 1171 RLPSM_SWVerMinor2 4;
BA_ "Description" SG_ 1171 RLPSM_SWVerMinor2 "Indicate the APSM software version as follows:

- The software version is displayed in three digits.

- The Major and Minor digits are separated by '.'

- Signal values are transmitted to ASCII codes.



¡Ø Example

RLPSM_SWVerMajor1 : 0x41 (HEX) -> ASCI";
BA_ "Version" SG_ 1171 RLPSM_RLLegRestPosition "21.01.03";
BA_ "RoutingFactor" SG_ 1171 RLPSM_RLLegRestPosition 0;
BA_ "NetworkRequestHoldingTime" SG_ 1171 RLPSM_RLLegRestPosition 5000;
BA_ "NetworkRequest" SG_ 1171 RLPSM_RLLegRestPosition 0;
BA_ "UserSigValidity" SG_ 1171 RLPSM_RLLegRestPosition 0;
BA_ "GenSigSendType" SG_ 1171 RLPSM_RLLegRestPosition 4;
BA_ "Description" SG_ 1171 RLPSM_RLLegRestPosition "Rear SEAT Leg Rest UP/DOWN POSITION (UNIT: ¨¬)";
BA_ "Version" SG_ 1171 RLPSM_EsyAcsStpSta "23.07.04";
BA_ "RoutingFactor" SG_ 1171 RLPSM_EsyAcsStpSta 0;
BA_ "NetworkRequestHoldingTime" SG_ 1171 RLPSM_EsyAcsStpSta 5000;
BA_ "NetworkRequest" SG_ 1171 RLPSM_EsyAcsStpSta 0;
BA_ "UserSigValidity" SG_ 1171 RLPSM_EsyAcsStpSta 0;
BA_ "GenSigSendType" SG_ 1171 RLPSM_EsyAcsStpSta 4;
BA_ "Version" SG_ 1171 RLPSM_EsyAcsGetOffSta "23.07.04";
BA_ "RoutingFactor" SG_ 1171 RLPSM_EsyAcsGetOffSta 0;
BA_ "NetworkRequestHoldingTime" SG_ 1171 RLPSM_EsyAcsGetOffSta 5000;
BA_ "NetworkRequest" SG_ 1171 RLPSM_EsyAcsGetOffSta 0;
BA_ "UserSigValidity" SG_ 1171 RLPSM_EsyAcsGetOffSta 0;
BA_ "GenSigSendType" SG_ 1171 RLPSM_EsyAcsGetOffSta 4;
BA_ "Version" SG_ 1171 RLPSM_SWVerMinor1 "20.04.06";
BA_ "RoutingFactor" SG_ 1171 RLPSM_SWVerMinor1 0;
BA_ "UserSigValidity" SG_ 1171 RLPSM_SWVerMinor1 0;
BA_ "GenSigSendType" SG_ 1171 RLPSM_SWVerMinor1 4;
BA_ "Description" SG_ 1171 RLPSM_SWVerMinor1 "Indicate the APSM software version as follows:

- The software version is displayed in three digits.

- The Major and Minor digits are separated by '.'

- Signal values are transmitted to ASCII codes.



¡Ø Example

RLPSM_SWVerMajor1 : 0x41 (HEX) -> ASCI";
BA_ "Version" SG_ 1172 RRPSM_SWVerMajor1 "21.07.00";
BA_ "RoutingFactor" SG_ 1172 RRPSM_SWVerMajor1 0;
BA_ "UserSigValidity" SG_ 1172 RRPSM_SWVerMajor1 0;
BA_ "GenSigSendType" SG_ 1172 RRPSM_SWVerMajor1 4;
BA_ "Description" SG_ 1172 RRPSM_SWVerMajor1 "Indicate the SCM software version as follows:

- The software version is displayed in three digits.

- The Major and Minor digits are separated by '.'

- Signal values are transmitted to ASCII codes.



¡Ø Example

RRPSM_SWVerMajor1 : 0x41 (HEX) -> ASCII";
BA_ "Version" SG_ 1172 RRPSM_SWVerMinor2 "20.04.06";
BA_ "RoutingFactor" SG_ 1172 RRPSM_SWVerMinor2 0;
BA_ "UserSigValidity" SG_ 1172 RRPSM_SWVerMinor2 0;
BA_ "GenSigSendType" SG_ 1172 RRPSM_SWVerMinor2 4;
BA_ "Description" SG_ 1172 RRPSM_SWVerMinor2 "Indicate the APSM software version as follows:

- The software version is displayed in three digits.

- The Major and Minor digits are separated by '.'

- Signal values are transmitted to ASCII codes.



¡Ø Example

RRPSM_SWVerMajor1 : 0x41 (HEX) -> ASCI";
BA_ "Version" SG_ 1172 RRPSM_EsyAcsStpSta "23.07.04";
BA_ "RoutingFactor" SG_ 1172 RRPSM_EsyAcsStpSta 0;
BA_ "NetworkRequestHoldingTime" SG_ 1172 RRPSM_EsyAcsStpSta 5000;
BA_ "NetworkRequest" SG_ 1172 RRPSM_EsyAcsStpSta 0;
BA_ "UserSigValidity" SG_ 1172 RRPSM_EsyAcsStpSta 0;
BA_ "GenSigSendType" SG_ 1172 RRPSM_EsyAcsStpSta 4;
BA_ "Version" SG_ 1172 RRPSM_EsyAcsGetOffSta "23.07.04";
BA_ "RoutingFactor" SG_ 1172 RRPSM_EsyAcsGetOffSta 0;
BA_ "NetworkRequestHoldingTime" SG_ 1172 RRPSM_EsyAcsGetOffSta 5000;
BA_ "NetworkRequest" SG_ 1172 RRPSM_EsyAcsGetOffSta 0;
BA_ "UserSigValidity" SG_ 1172 RRPSM_EsyAcsGetOffSta 0;
BA_ "GenSigSendType" SG_ 1172 RRPSM_EsyAcsGetOffSta 4;
BA_ "Version" SG_ 1172 RRPSM_SWVerMinor1 "20.04.06";
BA_ "RoutingFactor" SG_ 1172 RRPSM_SWVerMinor1 0;
BA_ "UserSigValidity" SG_ 1172 RRPSM_SWVerMinor1 0;
BA_ "GenSigSendType" SG_ 1172 RRPSM_SWVerMinor1 4;
BA_ "Description" SG_ 1172 RRPSM_SWVerMinor1 "Indicate the APSM software version as follows:

- The software version is displayed in three digits.

- The Major and Minor digits are separated by '.'

- Signal values are transmitted to ASCII codes.



¡Ø Example

RRPSM_SWVerMajor1 : 0x41 (HEX) -> ASCI";
BA_ "Version" SG_ 1174 Drv_SHVU_SeatOptSta "22.05.04";
BA_ "NetworkRequestHoldingTime" SG_ 1174 Drv_SHVU_SeatOptSta 5000;
BA_ "NetworkRequest" SG_ 1174 Drv_SHVU_SeatOptSta 0;
BA_ "UserSigValidity" SG_ 1174 Drv_SHVU_SeatOptSta 7;
BA_ "GenSigSendType" SG_ 1174 Drv_SHVU_SeatOptSta 4;
BA_ "Description" SG_ 1174 Drv_SHVU_SeatOptSta "¿îÀü¼® ½ÃÆ®¿¡ Àû¿ëµÈ È÷ÅÍ/ÅëÇ³ ¿É¼Ç »ç¾ç";
BA_ "Version" SG_ 1174 Drv_SHVU_HtSwHiIndSta "22.05.04";
BA_ "NetworkRequestHoldingTime" SG_ 1174 Drv_SHVU_HtSwHiIndSta 5000;
BA_ "NetworkRequest" SG_ 1174 Drv_SHVU_HtSwHiIndSta 0;
BA_ "UserSigValidity" SG_ 1174 Drv_SHVU_HtSwHiIndSta 7;
BA_ "GenSigSendType" SG_ 1174 Drv_SHVU_HtSwHiIndSta 4;
BA_ "Description" SG_ 1174 Drv_SHVU_HtSwHiIndSta "¿îÀü¼® ½ÃÆ® ¿­¼± ½ºÀ§Ä¡ High Indicator Á¤º¸";
BA_ "Version" SG_ 1174 Drv_SHVU_HtSwMidIndSta "22.05.04";
BA_ "NetworkRequestHoldingTime" SG_ 1174 Drv_SHVU_HtSwMidIndSta 5000;
BA_ "NetworkRequest" SG_ 1174 Drv_SHVU_HtSwMidIndSta 0;
BA_ "UserSigValidity" SG_ 1174 Drv_SHVU_HtSwMidIndSta 7;
BA_ "GenSigSendType" SG_ 1174 Drv_SHVU_HtSwMidIndSta 4;
BA_ "Description" SG_ 1174 Drv_SHVU_HtSwMidIndSta "¿îÀü¼® ½ÃÆ® ¿­¼± ½ºÀ§Ä¡ Mid Indicator Á¤º¸";
BA_ "Version" SG_ 1174 Drv_SHVU_HtSwLowIndSta "22.05.04";
BA_ "NetworkRequestHoldingTime" SG_ 1174 Drv_SHVU_HtSwLowIndSta 5000;
BA_ "NetworkRequest" SG_ 1174 Drv_SHVU_HtSwLowIndSta 0;
BA_ "UserSigValidity" SG_ 1174 Drv_SHVU_HtSwLowIndSta 7;
BA_ "GenSigSendType" SG_ 1174 Drv_SHVU_HtSwLowIndSta 4;
BA_ "Description" SG_ 1174 Drv_SHVU_HtSwLowIndSta "¿îÀü¼® ½ÃÆ® ¿­¼± ½ºÀ§Ä¡ Low Indicator Á¤º¸";
BA_ "Version" SG_ 1174 Drv_SHVU_VntSwHiIndSta "22.05.04";
BA_ "NetworkRequestHoldingTime" SG_ 1174 Drv_SHVU_VntSwHiIndSta 5000;
BA_ "NetworkRequest" SG_ 1174 Drv_SHVU_VntSwHiIndSta 0;
BA_ "UserSigValidity" SG_ 1174 Drv_SHVU_VntSwHiIndSta 7;
BA_ "GenSigSendType" SG_ 1174 Drv_SHVU_VntSwHiIndSta 4;
BA_ "Description" SG_ 1174 Drv_SHVU_VntSwHiIndSta "¿îÀü¼® ½ÃÆ® ÅëÇ³ ½ºÀ§Ä¡ High Indicator Á¤º¸";
BA_ "Version" SG_ 1174 Drv_SHVU_VntSwMidIndSta "22.05.04";
BA_ "NetworkRequestHoldingTime" SG_ 1174 Drv_SHVU_VntSwMidIndSta 5000;
BA_ "NetworkRequest" SG_ 1174 Drv_SHVU_VntSwMidIndSta 0;
BA_ "UserSigValidity" SG_ 1174 Drv_SHVU_VntSwMidIndSta 7;
BA_ "GenSigSendType" SG_ 1174 Drv_SHVU_VntSwMidIndSta 4;
BA_ "Description" SG_ 1174 Drv_SHVU_VntSwMidIndSta "¿îÀü¼® ½ÃÆ® ÅëÇ³ ½ºÀ§Ä¡ Mid Indicator Á¤º¸";
BA_ "Version" SG_ 1174 Drv_SHVU_VntSwLowIndSta "22.05.04";
BA_ "NetworkRequestHoldingTime" SG_ 1174 Drv_SHVU_VntSwLowIndSta 5000;
BA_ "NetworkRequest" SG_ 1174 Drv_SHVU_VntSwLowIndSta 0;
BA_ "UserSigValidity" SG_ 1174 Drv_SHVU_VntSwLowIndSta 7;
BA_ "GenSigSendType" SG_ 1174 Drv_SHVU_VntSwLowIndSta 4;
BA_ "Description" SG_ 1174 Drv_SHVU_VntSwLowIndSta "¿îÀü¼® ½ÃÆ® ÅëÇ³ ½ºÀ§Ä¡ Low Indicator Á¤º¸";
BA_ "Version" SG_ 1174 Drv_SHVU_HtBlcUSMSta "22.05.04";
BA_ "UserSigValidity" SG_ 1174 Drv_SHVU_HtBlcUSMSta 7;
BA_ "GenSigSendType" SG_ 1174 Drv_SHVU_HtBlcUSMSta 4;
BA_ "Description" SG_ 1174 Drv_SHVU_HtBlcUSMSta "Hetaer Balance Driver USM R vaule";
BA_ "Version" SG_ 1174 Drv_SHVU_SeatHtOperSta "22.05.04";
BA_ "NetworkRequestHoldingTime" SG_ 1174 Drv_SHVU_SeatHtOperSta 5000;
BA_ "NetworkRequest" SG_ 1174 Drv_SHVU_SeatHtOperSta 0;
BA_ "UserSigValidity" SG_ 1174 Drv_SHVU_SeatHtOperSta 7;
BA_ "GenSigSendType" SG_ 1174 Drv_SHVU_SeatHtOperSta 4;
BA_ "Description" SG_ 1174 Drv_SHVU_SeatHtOperSta "¿îÀü¼® ½ÃÆ® ÇöÀç ÀÛµ¿ ÁßÀÎ È÷ÅÍ/ÅëÇ³ ´Ü¼ö »óÅÂ";
BA_ "Version" SG_ 1174 Drv_SHVU_LastModeOptSta "24.08.00";
BA_ "NetworkRequestHoldingTime" SG_ 1174 Drv_SHVU_LastModeOptSta 5000;
BA_ "NetworkRequest" SG_ 1174 Drv_SHVU_LastModeOptSta 0;
BA_ "UserSigValidity" SG_ 1174 Drv_SHVU_LastModeOptSta 7;
BA_ "GenSigSendType" SG_ 1174 Drv_SHVU_LastModeOptSta 4;
BA_ "Description" SG_ 1174 Drv_SHVU_LastModeOptSta "Drv Seat Heat/Vent Last Mode Option State";
BA_ "Version" SG_ 1174 Drv_SHVU_HtSwHiIndSta_RHD "22.05.04";
BA_ "NetworkRequestHoldingTime" SG_ 1174 Drv_SHVU_HtSwHiIndSta_RHD 5000;
BA_ "NetworkRequest" SG_ 1174 Drv_SHVU_HtSwHiIndSta_RHD 0;
BA_ "UserSigValidity" SG_ 1174 Drv_SHVU_HtSwHiIndSta_RHD 7;
BA_ "GenSigSendType" SG_ 1174 Drv_SHVU_HtSwHiIndSta_RHD 4;
BA_ "Description" SG_ 1174 Drv_SHVU_HtSwHiIndSta_RHD "¿îÀü¼® ½ÃÆ® ¿­¼± ½ºÀ§Ä¡ High Indicator Á¤º¸(RHD)";
BA_ "Version" SG_ 1174 Drv_SHVU_HtSwMidIndSta_RHD "22.05.04";
BA_ "NetworkRequestHoldingTime" SG_ 1174 Drv_SHVU_HtSwMidIndSta_RHD 5000;
BA_ "NetworkRequest" SG_ 1174 Drv_SHVU_HtSwMidIndSta_RHD 0;
BA_ "UserSigValidity" SG_ 1174 Drv_SHVU_HtSwMidIndSta_RHD 7;
BA_ "GenSigSendType" SG_ 1174 Drv_SHVU_HtSwMidIndSta_RHD 4;
BA_ "Description" SG_ 1174 Drv_SHVU_HtSwMidIndSta_RHD "¿îÀü¼® ½ÃÆ® ¿­¼± ½ºÀ§Ä¡ Mid Indicator Á¤º¸(RHD)";
BA_ "Version" SG_ 1174 Drv_SHVU_HtSwLowIndSta_RHD "22.05.04";
BA_ "NetworkRequestHoldingTime" SG_ 1174 Drv_SHVU_HtSwLowIndSta_RHD 5000;
BA_ "NetworkRequest" SG_ 1174 Drv_SHVU_HtSwLowIndSta_RHD 0;
BA_ "UserSigValidity" SG_ 1174 Drv_SHVU_HtSwLowIndSta_RHD 7;
BA_ "GenSigSendType" SG_ 1174 Drv_SHVU_HtSwLowIndSta_RHD 4;
BA_ "Description" SG_ 1174 Drv_SHVU_HtSwLowIndSta_RHD "¿îÀü¼® ½ÃÆ® ¿­¼± ½ºÀ§Ä¡ Low Indicator Á¤º¸(RHD)";
BA_ "Version" SG_ 1174 Drv_SHVU_VntSwHiIndSta_RHD "22.05.04";
BA_ "NetworkRequestHoldingTime" SG_ 1174 Drv_SHVU_VntSwHiIndSta_RHD 5000;
BA_ "NetworkRequest" SG_ 1174 Drv_SHVU_VntSwHiIndSta_RHD 0;
BA_ "UserSigValidity" SG_ 1174 Drv_SHVU_VntSwHiIndSta_RHD 7;
BA_ "GenSigSendType" SG_ 1174 Drv_SHVU_VntSwHiIndSta_RHD 4;
BA_ "Description" SG_ 1174 Drv_SHVU_VntSwHiIndSta_RHD "¿îÀü¼® ½ÃÆ® ÅëÇ³ ½ºÀ§Ä¡ High Indicator Á¤º¸(RHD)";
BA_ "Version" SG_ 1174 Drv_SHVU_VntSwMidIndSta_RHD "22.05.04";
BA_ "NetworkRequestHoldingTime" SG_ 1174 Drv_SHVU_VntSwMidIndSta_RHD 5000;
BA_ "NetworkRequest" SG_ 1174 Drv_SHVU_VntSwMidIndSta_RHD 0;
BA_ "UserSigValidity" SG_ 1174 Drv_SHVU_VntSwMidIndSta_RHD 7;
BA_ "GenSigSendType" SG_ 1174 Drv_SHVU_VntSwMidIndSta_RHD 4;
BA_ "Description" SG_ 1174 Drv_SHVU_VntSwMidIndSta_RHD "¿îÀü¼® ½ÃÆ® ÅëÇ³ ½ºÀ§Ä¡ Mid Indicator Á¤º¸(RHD)";
BA_ "Version" SG_ 1174 Drv_SHVU_VntSwLowIndSta_RHD "22.05.04";
BA_ "NetworkRequestHoldingTime" SG_ 1174 Drv_SHVU_VntSwLowIndSta_RHD 5000;
BA_ "NetworkRequest" SG_ 1174 Drv_SHVU_VntSwLowIndSta_RHD 0;
BA_ "UserSigValidity" SG_ 1174 Drv_SHVU_VntSwLowIndSta_RHD 7;
BA_ "GenSigSendType" SG_ 1174 Drv_SHVU_VntSwLowIndSta_RHD 4;
BA_ "Description" SG_ 1174 Drv_SHVU_VntSwLowIndSta_RHD "¿îÀü¼® ½ÃÆ® ÅëÇ³ ½ºÀ§Ä¡ Low Indicator Á¤º¸(RHD)";
BA_ "Version" SG_ 1174 Drv_SHVU_HtBlcUSMSta_RHD "22.05.04";
BA_ "UserSigValidity" SG_ 1174 Drv_SHVU_HtBlcUSMSta_RHD 7;
BA_ "GenSigSendType" SG_ 1174 Drv_SHVU_HtBlcUSMSta_RHD 4;
BA_ "Description" SG_ 1174 Drv_SHVU_HtBlcUSMSta_RHD "Hetaer Balance Driver USM R vaule(RHD)";
BA_ "Version" SG_ 1179 Drv_SHVU_SeatEcoSta "22.05.04";
BA_ "NetworkRequestHoldingTime" SG_ 1179 Drv_SHVU_SeatEcoSta 5000;
BA_ "NetworkRequest" SG_ 1179 Drv_SHVU_SeatEcoSta 0;
BA_ "UserSigValidity" SG_ 1179 Drv_SHVU_SeatEcoSta 7;
BA_ "GenSigSendType" SG_ 1179 Drv_SHVU_SeatEcoSta 4;
BA_ "Description" SG_ 1179 Drv_SHVU_SeatEcoSta "Drv ½ÃÆ® ¿¡ÄÚÇÃ·¯½º ¸ðµå ÁøÀÔ Á¤º¸";
BA_ "Version" SG_ 1179 SHVU_Drv_Beep1Sound "22.05.04";
BA_ "UserSigValidity" SG_ 1179 SHVU_Drv_Beep1Sound 7;
BA_ "GenSigSendType" SG_ 1179 SHVU_Drv_Beep1Sound 4;
BA_ "Description" SG_ 1179 SHVU_Drv_Beep1Sound "Play touch beep sound one time

Beep sound on/off

Default : Off

Goes On when play beep sound";
BA_ "Version" SG_ 1179 SHVU_CtrlScreenDis "22.05.04";
BA_ "UserSigValidity" SG_ 1179 SHVU_CtrlScreenDis 7;
BA_ "GenSigSendType" SG_ 1179 SHVU_CtrlScreenDis 4;
BA_ "Description" SG_ 1179 SHVU_CtrlScreenDis "Change AVN Screen to control Seat Heater or Ventilation

Screen Display On : Pop up the menu of controlling Seat Heater & Ventilation

Default : Off";
BA_ "Version" SG_ 1180 SHVU_Ast_Beep1Sound "22.05.04";
BA_ "UserSigValidity" SG_ 1180 SHVU_Ast_Beep1Sound 7;
BA_ "GenSigSendType" SG_ 1180 SHVU_Ast_Beep1Sound 4;
BA_ "Description" SG_ 1180 SHVU_Ast_Beep1Sound "Play touch beep sound one time

Beep sound on/off

Default : Off

Goes On when play beep sound";
BA_ "Version" SG_ 1180 Ast_SHVU_SeatEcoSta "22.05.04";
BA_ "NetworkRequestHoldingTime" SG_ 1180 Ast_SHVU_SeatEcoSta 5000;
BA_ "NetworkRequest" SG_ 1180 Ast_SHVU_SeatEcoSta 0;
BA_ "UserSigValidity" SG_ 1180 Ast_SHVU_SeatEcoSta 7;
BA_ "GenSigSendType" SG_ 1180 Ast_SHVU_SeatEcoSta 4;
BA_ "Description" SG_ 1180 Ast_SHVU_SeatEcoSta "Ast ½ÃÆ® ¿¡ÄÚÇÃ·¯½º ¸ðµå ÁøÀÔ Á¤º¸";
BA_ "Version" SG_ 208 RR_SHVU_DTCdisplay "22.05.04";
BA_ "NetworkRequestHoldingTime" SG_ 208 RR_SHVU_DTCdisplay 5000;
BA_ "NetworkRequest" SG_ 208 RR_SHVU_DTCdisplay 0;
BA_ "UserSigValidity" SG_ 208 RR_SHVU_DTCdisplay 7;
BA_ "GenSigSendType" SG_ 208 RR_SHVU_DTCdisplay 4;
BA_ "Description" SG_ 208 RR_SHVU_DTCdisplay "0x00: DTC is not exist(Fail is not exist)/0x01:IGN2 Fuse Open Detection/0x02:Switch Input Detection at Same Time/0x03:NTC/Heating wire Open Detection/0x04:NTC+/NTC- Terminal Short Detection/0x05:NTC+/Heater+ Terminal Short Detection/0x06:NTC+/Heater-, He";
BA_ "Version" SG_ 208 RR_SHVU_DiagMode "22.05.04";
BA_ "NetworkRequestHoldingTime" SG_ 208 RR_SHVU_DiagMode 5000;
BA_ "NetworkRequest" SG_ 208 RR_SHVU_DiagMode 0;
BA_ "UserSigValidity" SG_ 208 RR_SHVU_DiagMode 7;
BA_ "GenSigSendType" SG_ 208 RR_SHVU_DiagMode 4;
BA_ "Description" SG_ 208 RR_SHVU_DiagMode "0x0:Default/0x1:DTC Mode/0x2:Normal Mode/0x3:Invalid";
BA_ "Version" SG_ 1181 RL_SHVU_SeatEcoSta "22.05.04";
BA_ "NetworkRequestHoldingTime" SG_ 1181 RL_SHVU_SeatEcoSta 5000;
BA_ "NetworkRequest" SG_ 1181 RL_SHVU_SeatEcoSta 0;
BA_ "UserSigValidity" SG_ 1181 RL_SHVU_SeatEcoSta 7;
BA_ "GenSigSendType" SG_ 1181 RL_SHVU_SeatEcoSta 4;
BA_ "Description" SG_ 1181 RL_SHVU_SeatEcoSta "ÈÄ¼® LH ½ÃÆ® ¿¡ÄÚÇÃ·¯½º ¸ðµå ÁøÀÔ Á¤º¸";
BA_ "Version" SG_ 1182 RR_SHVU_SeatEcoSta "22.05.04";
BA_ "NetworkRequestHoldingTime" SG_ 1182 RR_SHVU_SeatEcoSta 5000;
BA_ "NetworkRequest" SG_ 1182 RR_SHVU_SeatEcoSta 0;
BA_ "UserSigValidity" SG_ 1182 RR_SHVU_SeatEcoSta 7;
BA_ "GenSigSendType" SG_ 1182 RR_SHVU_SeatEcoSta 4;
BA_ "Description" SG_ 1182 RR_SHVU_SeatEcoSta "ÈÄ¼® RH ½ÃÆ® ¿¡ÄÚÇÃ·¯½º ¸ðµå ÁøÀÔ Á¤º¸";
BA_ "Version" SG_ 1186 HU_CDMOpenCmd "20.01.02";
BA_ "UserSigValidity" SG_ 1186 HU_CDMOpenCmd 7;
BA_ "GenSigSendType" SG_ 1186 HU_CDMOpenCmd 4;
BA_ "Description" SG_ 1186 HU_CDMOpenCmd "Command for CDM open/close";
BA_ "Version" SG_ 1186 C_PreCrankReq "18.09.04";
BA_ "NetworkRequest" SG_ 1186 C_PreCrankReq 0;
BA_ "UserSigValidity" SG_ 1186 C_PreCrankReq 0;
BA_ "GenSigSendType" SG_ 1186 C_PreCrankReq 4;
BA_ "Description" SG_ 1186 C_PreCrankReq "18.08.09_Remote Control message";
BA_ "Version" SG_ 1186 C_TeleAstSeatOpCmdIBOX "18.09.04";
BA_ "UserSigValidity" SG_ 1186 C_TeleAstSeatOpCmdIBOX 3;
BA_ "GenSigSendType" SG_ 1186 C_TeleAstSeatOpCmdIBOX 4;
BA_ "Description" SG_ 1186 C_TeleAstSeatOpCmdIBOX "18.08.09_Remote Control message";
BA_ "Version" SG_ 1186 C_TeleDrvSeatOpCmdIBOX "18.09.04";
BA_ "UserSigValidity" SG_ 1186 C_TeleDrvSeatOpCmdIBOX 3;
BA_ "GenSigSendType" SG_ 1186 C_TeleDrvSeatOpCmdIBOX 4;
BA_ "Description" SG_ 1186 C_TeleDrvSeatOpCmdIBOX "18.08.09_Remote Control message";
BA_ "Version" SG_ 1186 C_TeleRRSeatOpCmdIBOX "18.09.04";
BA_ "UserSigValidity" SG_ 1186 C_TeleRRSeatOpCmdIBOX 3;
BA_ "GenSigSendType" SG_ 1186 C_TeleRRSeatOpCmdIBOX 4;
BA_ "Description" SG_ 1186 C_TeleRRSeatOpCmdIBOX "18.08.09_Remote Control message";
BA_ "Version" SG_ 1186 C_TeleRLSeatOpCmdIBOX "18.09.04";
BA_ "UserSigValidity" SG_ 1186 C_TeleRLSeatOpCmdIBOX 3;
BA_ "GenSigSendType" SG_ 1186 C_TeleRLSeatOpCmdIBOX 4;
BA_ "Description" SG_ 1186 C_TeleRLSeatOpCmdIBOX "18.08.09_Remote Control message";
BA_ "Version" SG_ 1185 C_AstWindowCmdAVN "19.11.05";
BA_ "UserSigValidity" SG_ 1185 C_AstWindowCmdAVN 0;
BA_ "GenSigStartValue" SG_ 1185 C_AstWindowCmdAVN 15;
BA_ "GenSigSendType" SG_ 1185 C_AstWindowCmdAVN 4;
BA_ "Version" SG_ 1185 C_RrDefoggerCmdAVN "18.09.02";
BA_ "UserSigValidity" SG_ 1185 C_RrDefoggerCmdAVN 3;
BA_ "GenSigStartValue" SG_ 1185 C_RrDefoggerCmdAVN 3;
BA_ "GenSigSendType" SG_ 1185 C_RrDefoggerCmdAVN 4;
BA_ "Description" SG_ 1185 C_RrDefoggerCmdAVN "18.08.09_";
BA_ "Version" SG_ 1185 C_RrBlindCmdAVN "22.02.04";
BA_ "UserSigValidity" SG_ 1185 C_RrBlindCmdAVN 3;
BA_ "GenSigStartValue" SG_ 1185 C_RrBlindCmdAVN 3;
BA_ "GenSigSendType" SG_ 1185 C_RrBlindCmdAVN 4;
BA_ "Description" SG_ 1185 C_RrBlindCmdAVN "Rear sunroof control signal(blind)";
BA_ "Version" SG_ 1185 C_RrGlassCmdAVN "22.02.04";
BA_ "UserSigValidity" SG_ 1185 C_RrGlassCmdAVN 3;
BA_ "GenSigStartValue" SG_ 1185 C_RrGlassCmdAVN 3;
BA_ "GenSigSendType" SG_ 1185 C_RrGlassCmdAVN 4;
BA_ "Description" SG_ 1185 C_RrGlassCmdAVN "Rear sunroof control signal(glass)";
BA_ "Version" SG_ 1185 C_RRWindowCmdAVN "19.11.05";
BA_ "UserSigValidity" SG_ 1185 C_RRWindowCmdAVN 0;
BA_ "GenSigStartValue" SG_ 1185 C_RRWindowCmdAVN 15;
BA_ "GenSigSendType" SG_ 1185 C_RRWindowCmdAVN 4;
BA_ "Version" SG_ 1185 C_RLWindowCmdAVN "19.11.05";
BA_ "UserSigValidity" SG_ 1185 C_RLWindowCmdAVN 0;
BA_ "GenSigStartValue" SG_ 1185 C_RLWindowCmdAVN 15;
BA_ "GenSigSendType" SG_ 1185 C_RLWindowCmdAVN 4;
BA_ "Version" SG_ 1185 C_BlindCmdAVN "18.09.02";
BA_ "UserSigValidity" SG_ 1185 C_BlindCmdAVN 1;
BA_ "GenSigStartValue" SG_ 1185 C_BlindCmdAVN 7;
BA_ "GenSigSendType" SG_ 1185 C_BlindCmdAVN 4;
BA_ "Description" SG_ 1185 C_BlindCmdAVN "18.08.09_";
BA_ "Version" SG_ 1185 C_GlassCmdAVN "18.09.02";
BA_ "UserSigValidity" SG_ 1185 C_GlassCmdAVN 1;
BA_ "GenSigStartValue" SG_ 1185 C_GlassCmdAVN 7;
BA_ "GenSigSendType" SG_ 1185 C_GlassCmdAVN 4;
BA_ "Description" SG_ 1185 C_GlassCmdAVN "18.08.09_";
BA_ "Version" SG_ 1185 C_DrvWindowCmdAVN "19.11.05";
BA_ "UserSigValidity" SG_ 1185 C_DrvWindowCmdAVN 0;
BA_ "GenSigStartValue" SG_ 1185 C_DrvWindowCmdAVN 15;
BA_ "GenSigSendType" SG_ 1185 C_DrvWindowCmdAVN 4;
BA_ "Version" SG_ 1185 C_PTGCNTLCmdAVN "18.09.02";
BA_ "UserSigValidity" SG_ 1185 C_PTGCNTLCmdAVN 3;
BA_ "GenSigStartValue" SG_ 1185 C_PTGCNTLCmdAVN 3;
BA_ "GenSigSendType" SG_ 1185 C_PTGCNTLCmdAVN 4;
BA_ "Description" SG_ 1185 C_PTGCNTLCmdAVN "18.08.09_";
BA_REL_ "GenSigTimeoutTime" BU_SG_REL_ ATS SG_ 1266 HU_LanguageInfo 5000;
BA_REL_ "GenSigTimeoutTime" BU_SG_REL_ BLTN_CAM SG_ 1266 HU_LanguageInfo 5000;
BA_REL_ "GenSigTimeoutTime" BU_SG_REL_ ARS SG_ 1267 RSELockOnOff 5000;
BA_REL_ "GenSigTimeoutTime" BU_SG_REL_ ATS SG_ 1267 RSELockOnOff 5000;
BA_REL_ "GenSigTimeoutTime" BU_SG_REL_ GW_APSU SG_ 1267 RSELockOnOff 5000;
BA_REL_ "GenSigTimeoutTime" BU_SG_REL_ ATS SG_ 191 RL_SHVU_DTCdisplay 1500;
BA_REL_ "GenSigTimeoutTime" BU_SG_REL_ ATS SG_ 191 RL_SHVU_DiagMode 1500;
BA_REL_ "GenSigTimeoutTime" BU_SG_REL_ ATS SG_ 1264 HU_TimeSetting 5000;
BA_REL_ "GenSigTimeoutTime" BU_SG_REL_ BLTN_CAM SG_ 1264 HU_TimeSetting 5000;
BA_REL_ "GenSigTimeoutTime" BU_SG_REL_ ATS SG_ 1264 HU_DisplayMinute 5000;
BA_REL_ "GenSigTimeoutTime" BU_SG_REL_ BLTN_CAM SG_ 1264 HU_DisplayMinute 5000;
BA_REL_ "GenSigTimeoutTime" BU_SG_REL_ ATS SG_ 1264 HU_Status 5000;
BA_REL_ "GenSigTimeoutTime" BU_SG_REL_ BLTN_CAM SG_ 1264 HU_Status 5000;
BA_REL_ "GenSigTimeoutTime" BU_SG_REL_ ATS SG_ 1264 HU_DisplaySecond 5000;
BA_REL_ "GenSigTimeoutTime" BU_SG_REL_ BLTN_CAM SG_ 1264 HU_DisplaySecond 5000;
BA_REL_ "GenSigTimeoutTime" BU_SG_REL_ ATS SG_ 1264 HU_DisplayMonth 5000;
BA_REL_ "GenSigTimeoutTime" BU_SG_REL_ BLTN_CAM SG_ 1264 HU_DisplayMonth 5000;
BA_REL_ "GenSigTimeoutTime" BU_SG_REL_ ATS SG_ 1264 HU_DisplayYear1 5000;
BA_REL_ "GenSigTimeoutTime" BU_SG_REL_ BLTN_CAM SG_ 1264 HU_DisplayYear1 5000;
BA_REL_ "GenSigTimeoutTime" BU_SG_REL_ ATS SG_ 1264 HU_DisplayYear2 5000;
BA_REL_ "GenSigTimeoutTime" BU_SG_REL_ BLTN_CAM SG_ 1264 HU_DisplayYear2 5000;
BA_REL_ "GenSigTimeoutTime" BU_SG_REL_ ATS SG_ 1264 HU_DisplayDay 5000;
BA_REL_ "GenSigTimeoutTime" BU_SG_REL_ BLTN_CAM SG_ 1264 HU_DisplayDay 5000;
BA_REL_ "GenSigTimeoutTime" BU_SG_REL_ ATS SG_ 1264 HU_AM_PM_INFO 5000;
BA_REL_ "GenSigTimeoutTime" BU_SG_REL_ BLTN_CAM SG_ 1264 HU_AM_PM_INFO 5000;
BA_REL_ "GenSigTimeoutTime" BU_SG_REL_ ATS SG_ 1264 HU_TimeFormat 5000;
BA_REL_ "GenSigTimeoutTime" BU_SG_REL_ BLTN_CAM SG_ 1264 HU_TimeFormat 5000;
BA_REL_ "GenSigTimeoutTime" BU_SG_REL_ ATS SG_ 1264 HU_ComRefresh 5000;
BA_REL_ "GenSigTimeoutTime" BU_SG_REL_ BLTN_CAM SG_ 1264 HU_ComRefresh 5000;
BA_REL_ "GenSigTimeoutTime" BU_SG_REL_ ATS SG_ 1264 HU_ClockInfo 5000;
BA_REL_ "GenSigTimeoutTime" BU_SG_REL_ BLTN_CAM SG_ 1264 HU_ClockInfo 5000;
BA_REL_ "GenSigTimeoutTime" BU_SG_REL_ ATS SG_ 1264 HU_DisplayHour 5000;
BA_REL_ "GenSigTimeoutTime" BU_SG_REL_ BLTN_CAM SG_ 1264 HU_DisplayHour 5000;
BA_REL_ "GenSigTimeoutTime" BU_SG_REL_ ATS SG_ 1265 HU_Background 5000;
BA_REL_ "GenSigTimeoutTime" BU_SG_REL_ BLTN_CAM SG_ 1265 HU_Background 5000;
BA_REL_ "GenSigTimeoutTime" BU_SG_REL_ ATS SG_ 1265 HU_BackgroundFadeInOut 5000;
BA_REL_ "GenSigTimeoutTime" BU_SG_REL_ BLTN_CAM SG_ 1265 HU_BackgroundFadeInOut 5000;
BA_REL_ "GenSigTimeoutTime" BU_SG_REL_ BLTN_CAM SG_ 1278 HU_Type 5000;
BA_REL_ "GenSigTimeoutTime" BU_SG_REL_ BLTN_CAM SG_ 1278 HU_DistributeInfo 5000;
BA_REL_ "GenSigTimeoutTime" BU_SG_REL_ BLTN_CAM SG_ 1278 HU_OptionInfo 5000;
BA_REL_ "GenSigTimeoutTime" BU_SG_REL_ RCM SG_ 1278 HU_OptionInfo 5000;
BA_REL_ "GenSigTimeoutTime" BU_SG_REL_ GW_APSU SG_ 1279 AVN_SeatPosMemory_Btn 0;
BA_REL_ "GenSigTimeoutTime" BU_SG_REL_ GW_DPSU SG_ 1279 AVN_SeatPosMemory_Btn 0;
BA_REL_ "GenSigTimeoutTime" BU_SG_REL_ GW_RLPSU SG_ 1279 AVN_SeatPosMemory_Btn 0;
BA_REL_ "GenSigTimeoutTime" BU_SG_REL_ GW_RRPSU SG_ 1279 AVN_SeatPosMemory_Btn 0;
BA_REL_ "GenSigTimeoutTime" BU_SG_REL_ GW_APSU SG_ 1279 AVN_SeatPosPlyBck_Btn 0;
BA_REL_ "GenSigTimeoutTime" BU_SG_REL_ GW_DPSU SG_ 1279 AVN_SeatPosPlyBck_Btn 0;
BA_REL_ "GenSigTimeoutTime" BU_SG_REL_ GW_RLPSU SG_ 1279 AVN_SeatPosPlyBck_Btn 0;
BA_REL_ "GenSigTimeoutTime" BU_SG_REL_ GW_RRPSU SG_ 1279 AVN_SeatPosPlyBck_Btn 0;
BA_REL_ "GenSigTimeoutTime" BU_SG_REL_ SWRC SG_ 2328016129 VCU_EvDrvRdyCluDispSta 1500;
BA_REL_ "GenSigTimeoutTime" BU_SG_REL_ ALBCU SG_ 200 CF_AVN_BodySpprtSet_AST 0;
BA_REL_ "GenSigTimeoutTime" BU_SG_REL_ ALBCU SG_ 200 CF_AVN_AirSptTimeNValueSet_AST 0;
BA_REL_ "GenSigTimeoutTime" BU_SG_REL_ ALBCU SG_ 200 CF_AVN_AirSptStrNValue_AST 0;
BA_REL_ "GenSigTimeoutTime" BU_SG_REL_ ALBCU SG_ 200 CF_AVN_SeatDrvModNvalueSet_AST 0;
BA_REL_ "GenSigTimeoutTime" BU_SG_REL_ WPC SG_ 200 CF_Gway_WPC2_NValueSet 0;
BA_REL_ "GenSigTimeoutTime" BU_SG_REL_ WPC2 SG_ 200 CF_Gway_WPC2_NValueSet 0;
BA_REL_ "GenSigTimeoutTime" BU_SG_REL_ GW_APSU SG_ 1159 C_AstRclBwdSw_HU 1500;
BA_REL_ "GenSigTimeoutTime" BU_SG_REL_ GW_APSU SG_ 1159 C_AstHeightUpSw_HU 1500;
BA_REL_ "GenSigTimeoutTime" BU_SG_REL_ GW_APSU SG_ 1159 C_AstTiltDnSw_HU 1500;
BA_REL_ "GenSigTimeoutTime" BU_SG_REL_ GW_APSU SG_ 1159 C_AstTiltUpSw_HU 1500;
BA_REL_ "GenSigTimeoutTime" BU_SG_REL_ ALBCU SG_ 1159 C_AstLumbarDefSw_HU 1500;
BA_REL_ "GenSigTimeoutTime" BU_SG_REL_ ASAU SG_ 1159 C_AstLumbarDefSw_HU 1500;
BA_REL_ "GenSigTimeoutTime" BU_SG_REL_ GW_APSU SG_ 1159 C_AstLumbarDefSw_HU 1500;
BA_REL_ "GenSigTimeoutTime" BU_SG_REL_ ALBCU SG_ 1159 C_AstLumbarLowSw_HU 1500;
BA_REL_ "GenSigTimeoutTime" BU_SG_REL_ ASAU SG_ 1159 C_AstLumbarLowSw_HU 1500;
BA_REL_ "GenSigTimeoutTime" BU_SG_REL_ GW_APSU SG_ 1159 C_AstLumbarLowSw_HU 1500;
BA_REL_ "GenSigTimeoutTime" BU_SG_REL_ GW_APSU SG_ 1159 C_AstRclFwdSw_HU 1500;
BA_REL_ "GenSigTimeoutTime" BU_SG_REL_ ALBCU SG_ 1159 C_AstLumbarMidSw_HU 1500;
BA_REL_ "GenSigTimeoutTime" BU_SG_REL_ ASAU SG_ 1159 C_AstLumbarMidSw_HU 1500;
BA_REL_ "GenSigTimeoutTime" BU_SG_REL_ GW_APSU SG_ 1159 C_AstLumbarMidSw_HU 1500;
BA_REL_ "GenSigTimeoutTime" BU_SG_REL_ ALBCU SG_ 1159 C_AstLumbarUpSw_HU 1500;
BA_REL_ "GenSigTimeoutTime" BU_SG_REL_ ASAU SG_ 1159 C_AstLumbarUpSw_HU 1500;
BA_REL_ "GenSigTimeoutTime" BU_SG_REL_ GW_APSU SG_ 1159 C_AstLumbarUpSw_HU 1500;
BA_REL_ "GenSigTimeoutTime" BU_SG_REL_ GW_APSU SG_ 1159 C_RRSlideFwdSw_HU 1500;
BA_REL_ "GenSigTimeoutTime" BU_SG_REL_ GW_RRPSU SG_ 1159 C_RRSlideFwdSw_HU 1500;
BA_REL_ "GenSigTimeoutTime" BU_SG_REL_ GW_APSU SG_ 1159 C_RRSlideBwdSw_HU 1500;
BA_REL_ "GenSigTimeoutTime" BU_SG_REL_ GW_RRPSU SG_ 1159 C_RRSlideBwdSw_HU 1500;
BA_REL_ "GenSigTimeoutTime" BU_SG_REL_ GW_APSU SG_ 1159 C_RLSlideFwdSw_HU 1500;
BA_REL_ "GenSigTimeoutTime" BU_SG_REL_ GW_RLPSU SG_ 1159 C_RLSlideFwdSw_HU 1500;
BA_REL_ "GenSigTimeoutTime" BU_SG_REL_ GW_RRPSU SG_ 1159 C_RLSlideFwdSw_HU 1500;
BA_REL_ "GenSigTimeoutTime" BU_SG_REL_ GW_APSU SG_ 1159 C_RLSlideBwdSw_HU 1500;
BA_REL_ "GenSigTimeoutTime" BU_SG_REL_ GW_RLPSU SG_ 1159 C_RLSlideBwdSw_HU 1500;
BA_REL_ "GenSigTimeoutTime" BU_SG_REL_ GW_RRPSU SG_ 1159 C_RLSlideBwdSw_HU 1500;
BA_REL_ "GenSigTimeoutTime" BU_SG_REL_ GW_APSU SG_ 1159 C_AstSlideBwdSw_HU 1500;
BA_REL_ "GenSigTimeoutTime" BU_SG_REL_ GW_APSU SG_ 1159 C_AstSlideFwdSw_HU 1500;
BA_REL_ "GenSigTimeoutTime" BU_SG_REL_ GW_APSU SG_ 1159 C_AstHeightDnSw_HU 1500;
BA_REL_ "GenSigTimeoutTime" BU_SG_REL_ GW_APSU SG_ 197 C_RLLegSupFwdSw_HU 1500;
BA_REL_ "GenSigTimeoutTime" BU_SG_REL_ GW_RLPSU SG_ 197 C_RLLegSupFwdSw_HU 1500;
BA_REL_ "GenSigTimeoutTime" BU_SG_REL_ GW_APSU SG_ 197 C_RLLegSupBwdSw_HU 1500;
BA_REL_ "GenSigTimeoutTime" BU_SG_REL_ GW_RLPSU SG_ 197 C_RLLegSupBwdSw_HU 1500;
BA_REL_ "GenSigTimeoutTime" BU_SG_REL_ GW_APSU SG_ 197 C_RLLegSupUpSw_HU 1500;
BA_REL_ "GenSigTimeoutTime" BU_SG_REL_ GW_RLPSU SG_ 197 C_RLLegSupUpSw_HU 1500;
BA_REL_ "GenSigTimeoutTime" BU_SG_REL_ GW_APSU SG_ 197 C_RLLegSupDnSw_HU 1500;
BA_REL_ "GenSigTimeoutTime" BU_SG_REL_ GW_RLPSU SG_ 197 C_RLLegSupDnSw_HU 1500;
BA_REL_ "GenSigTimeoutTime" BU_SG_REL_ CGW_CCU SG_ 1165 RLMSS_OnOffBtn_AVN 5000;
BA_REL_ "GenSigTimeoutTime" BU_SG_REL_ ATS SG_ 2382595073 DATC_FrDrvBlwDis 1500;
BA_REL_ "GenSigTimeoutTime" BU_SG_REL_ ATS SG_ 2382595073 DATC_FrPsBlwDis 1500;
BA_REL_ "GenSigTimeoutTime" BU_SG_REL_ ATS SG_ 2382595073 DATC_DrvOnlyDis 1500;
BA_REL_ "GenSigTimeoutTime" BU_SG_REL_ ATS SG_ 2382595073 DATC_RrClmtScrnDis 1500;
BA_REL_ "GenSigTimeoutTime" BU_SG_REL_ ATS SG_ 2382595073 DATC_AUTOStep 1500;
BA_REL_ "GenSigTimeoutTime" BU_SG_REL_ ATS SG_ 2382595073 DATC_IntakeDis 1500;
BA_REL_ "GenSigTimeoutTime" BU_SG_REL_ BLTN_CAM SG_ 1167 ICU_BattAutoCutPreWrng 5000;
BA_REL_ "GenSigTimeoutTime" BU_SG_REL_ FCS SG_ 194 CF_AVN_DrvArmRestHeatNValueSet 0;
BA_REL_ "GenSigTimeoutTime" BU_SG_REL_ FCS SG_ 194 CF_AVN_AstArmRestHeatNValueSet 0;
BA_REL_ "GenSigTimeoutTime" BU_SG_REL_ FCS SG_ 194 CF_AVN_RRArmRestHeatNValueSet 0;
BA_REL_ "GenSigTimeoutTime" BU_SG_REL_ FCS SG_ 194 CF_AVN_RLArmRestHeatNValueSet 0;
BA_REL_ "GenSigTimeoutTime" BU_SG_REL_ GW_DLBCU SG_ 194 CF_AVN_AirSptStrNValue_VR 0;
BA_REL_ "GenSigTimeoutTime" BU_SG_REL_ GW_DLBCU SG_ 194 CF_AVN_AirSptTimeNValueSet_VR 0;
BA_REL_ "GenSigTimeoutTime" BU_SG_REL_ GW_DLBCU SG_ 194 CF_AVN_AirSptMode_VR 0;
BA_REL_ "GenSigTimeoutTime" BU_SG_REL_ GW_RRPSU SG_ 194 C_TeleRRMsgOpCmdIBOX_0 0;
BA_REL_ "GenSigTimeoutTime" BU_SG_REL_ GW_RLPSU SG_ 194 C_TeleRLMsgOpCmdIBOX_0 0;
BA_REL_ "GenSigTimeoutTime" BU_SG_REL_ GW_DLBCU SG_ 194 CF_AVN_ActbolstersenNValue 0;
BA_REL_ "GenSigTimeoutTime" BU_SG_REL_ CGW_CCU SG_ 1166 RRMSS_OnOffBtn_AVN 5000;
BA_REL_ "GenSigTimeoutTime" BU_SG_REL_ CGW_CCU SG_ 223 ALBCU_SmartCtrl_1h 0;
BA_REL_ "GenSigTimeoutTime" BU_SG_REL_ CGW_CCU SG_ 223 ALBCU_SmartCtrl_2h 0;
BA_REL_ "GenSigTimeoutTime" BU_SG_REL_ CGW_CCU SG_ 223 ALBCU_SmartCtrl_Status 0;
BA_REL_ "GenSigTimeoutTime" BU_SG_REL_ GW_APSU SG_ 1171 RLPSM_RLLegRestPosition 1500;
BA_REL_ "GenSigTimeoutTime" BU_SG_REL_ GW_DPSU SG_ 1171 RLPSM_RLLegRestPosition 1500;
BA_REL_ "GenSigTimeoutTime" BU_SG_REL_ GW_DLBCU SG_ 1171 RLPSM_EsyAcsStpSta 1500;
BA_REL_ "GenSigTimeoutTime" BU_SG_REL_ GW_DLBCU SG_ 1171 RLPSM_EsyAcsGetOffSta 1500;
BA_REL_ "GenSigTimeoutTime" BU_SG_REL_ GW_DLBCU SG_ 1172 RRPSM_EsyAcsStpSta 1500;
BA_REL_ "GenSigTimeoutTime" BU_SG_REL_ GW_DLBCU SG_ 1172 RRPSM_EsyAcsGetOffSta 1500;
BA_REL_ "GenSigTimeoutTime" BU_SG_REL_ CGW_CCU SG_ 1174 Drv_SHVU_SeatOptSta 1500;
BA_REL_ "GenSigTimeoutTime" BU_SG_REL_ FCS SG_ 1174 Drv_SHVU_SeatOptSta 1500;
BA_REL_ "GenSigTimeoutTime" BU_SG_REL_ CGW_CCU SG_ 1174 Drv_SHVU_HtSwHiIndSta 1500;
BA_REL_ "GenSigTimeoutTime" BU_SG_REL_ FCS SG_ 1174 Drv_SHVU_HtSwHiIndSta 1500;
BA_REL_ "GenSigTimeoutTime" BU_SG_REL_ CGW_CCU SG_ 1174 Drv_SHVU_HtSwMidIndSta 1500;
BA_REL_ "GenSigTimeoutTime" BU_SG_REL_ FCS SG_ 1174 Drv_SHVU_HtSwMidIndSta 1500;
BA_REL_ "GenSigTimeoutTime" BU_SG_REL_ CGW_CCU SG_ 1174 Drv_SHVU_HtSwLowIndSta 1500;
BA_REL_ "GenSigTimeoutTime" BU_SG_REL_ FCS SG_ 1174 Drv_SHVU_HtSwLowIndSta 1500;
BA_REL_ "GenSigTimeoutTime" BU_SG_REL_ CGW_CCU SG_ 1174 Drv_SHVU_VntSwHiIndSta 1500;
BA_REL_ "GenSigTimeoutTime" BU_SG_REL_ FCS SG_ 1174 Drv_SHVU_VntSwHiIndSta 1500;
BA_REL_ "GenSigTimeoutTime" BU_SG_REL_ CGW_CCU SG_ 1174 Drv_SHVU_VntSwMidIndSta 1500;
BA_REL_ "GenSigTimeoutTime" BU_SG_REL_ FCS SG_ 1174 Drv_SHVU_VntSwMidIndSta 1500;
BA_REL_ "GenSigTimeoutTime" BU_SG_REL_ CGW_CCU SG_ 1174 Drv_SHVU_VntSwLowIndSta 1500;
BA_REL_ "GenSigTimeoutTime" BU_SG_REL_ FCS SG_ 1174 Drv_SHVU_VntSwLowIndSta 1500;
BA_REL_ "GenSigTimeoutTime" BU_SG_REL_ CGW_CCU SG_ 1174 Drv_SHVU_HtBlcUSMSta 1500;
BA_REL_ "GenSigTimeoutTime" BU_SG_REL_ CGW_CCU SG_ 1174 Drv_SHVU_SeatHtOperSta 1500;
BA_REL_ "GenSigTimeoutTime" BU_SG_REL_ FCS SG_ 1174 Drv_SHVU_SeatHtOperSta 1500;
BA_REL_ "GenSigTimeoutTime" BU_SG_REL_ CGW_CCU SG_ 1174 Drv_SHVU_LastModeOptSta 1500;
BA_REL_ "GenSigTimeoutTime" BU_SG_REL_ CGW_CCU SG_ 1174 Drv_SHVU_HtSwHiIndSta_RHD 1500;
BA_REL_ "GenSigTimeoutTime" BU_SG_REL_ FCS SG_ 1174 Drv_SHVU_HtSwHiIndSta_RHD 1500;
BA_REL_ "GenSigTimeoutTime" BU_SG_REL_ CGW_CCU SG_ 1174 Drv_SHVU_HtSwMidIndSta_RHD 1500;
BA_REL_ "GenSigTimeoutTime" BU_SG_REL_ FCS SG_ 1174 Drv_SHVU_HtSwMidIndSta_RHD 1500;
BA_REL_ "GenSigTimeoutTime" BU_SG_REL_ CGW_CCU SG_ 1174 Drv_SHVU_HtSwLowIndSta_RHD 1500;
BA_REL_ "GenSigTimeoutTime" BU_SG_REL_ FCS SG_ 1174 Drv_SHVU_HtSwLowIndSta_RHD 1500;
BA_REL_ "GenSigTimeoutTime" BU_SG_REL_ CGW_CCU SG_ 1174 Drv_SHVU_VntSwHiIndSta_RHD 1500;
BA_REL_ "GenSigTimeoutTime" BU_SG_REL_ FCS SG_ 1174 Drv_SHVU_VntSwHiIndSta_RHD 1500;
BA_REL_ "GenSigTimeoutTime" BU_SG_REL_ CGW_CCU SG_ 1174 Drv_SHVU_VntSwMidIndSta_RHD 1500;
BA_REL_ "GenSigTimeoutTime" BU_SG_REL_ FCS SG_ 1174 Drv_SHVU_VntSwMidIndSta_RHD 1500;
BA_REL_ "GenSigTimeoutTime" BU_SG_REL_ CGW_CCU SG_ 1174 Drv_SHVU_VntSwLowIndSta_RHD 1500;
BA_REL_ "GenSigTimeoutTime" BU_SG_REL_ FCS SG_ 1174 Drv_SHVU_VntSwLowIndSta_RHD 1500;
BA_REL_ "GenSigTimeoutTime" BU_SG_REL_ CGW_CCU SG_ 1179 Drv_SHVU_SeatEcoSta 0;
BA_REL_ "GenSigTimeoutTime" BU_SG_REL_ CGW_CCU SG_ 1179 SHVU_Drv_Beep1Sound 0;
BA_REL_ "GenSigTimeoutTime" BU_SG_REL_ CGW_CCU SG_ 1179 SHVU_CtrlScreenDis 0;
BA_REL_ "GenSigTimeoutTime" BU_SG_REL_ CGW_CCU SG_ 1180 SHVU_Ast_Beep1Sound 0;
BA_REL_ "GenSigTimeoutTime" BU_SG_REL_ CGW_CCU SG_ 1180 Ast_SHVU_SeatEcoSta 0;
BA_REL_ "GenSigTimeoutTime" BU_SG_REL_ ATS SG_ 208 RR_SHVU_DTCdisplay 1500;
BA_REL_ "GenSigTimeoutTime" BU_SG_REL_ ATS SG_ 208 RR_SHVU_DiagMode 1500;
BA_REL_ "GenSigTimeoutTime" BU_SG_REL_ ATS SG_ 1181 RL_SHVU_SeatEcoSta 0;
BA_REL_ "GenSigTimeoutTime" BU_SG_REL_ CGW_CCU SG_ 1181 RL_SHVU_SeatEcoSta 0;
BA_REL_ "GenSigTimeoutTime" BU_SG_REL_ vHS_B2 SG_ 1181 RL_SHVU_SeatEcoSta 0;
BA_REL_ "GenSigTimeoutTime" BU_SG_REL_ ATS SG_ 1182 RR_SHVU_SeatEcoSta 0;
BA_REL_ "GenSigTimeoutTime" BU_SG_REL_ CGW_CCU SG_ 1182 RR_SHVU_SeatEcoSta 0;
BA_REL_ "GenSigTimeoutTime" BU_SG_REL_ vHS_B2 SG_ 1182 RR_SHVU_SeatEcoSta 0;
BA_REL_ "GenSigTimeoutTime" BU_SG_REL_ BLTN_CAM SG_ 1186 C_PreCrankReq 0;
BA_REL_ "GenSigTimeoutTime" BU_SG_REL_ GW_APSU SG_ 1186 C_TeleAstSeatOpCmdIBOX 0;
BA_REL_ "GenSigTimeoutTime" BU_SG_REL_ SHVU_FR SG_ 1186 C_TeleAstSeatOpCmdIBOX 0;
BA_REL_ "GenSigTimeoutTime" BU_SG_REL_ GW_APSU SG_ 1186 C_TeleDrvSeatOpCmdIBOX 0;
BA_REL_ "GenSigTimeoutTime" BU_SG_REL_ GW_DPSU SG_ 1186 C_TeleDrvSeatOpCmdIBOX 0;
BA_REL_ "GenSigTimeoutTime" BU_SG_REL_ SHVU_FR SG_ 1186 C_TeleDrvSeatOpCmdIBOX 0;
BA_REL_ "GenSigTimeoutTime" BU_SG_REL_ ATS SG_ 1186 C_TeleRRSeatOpCmdIBOX 0;
BA_REL_ "GenSigTimeoutTime" BU_SG_REL_ GW_RRPSU SG_ 1186 C_TeleRRSeatOpCmdIBOX 0;
BA_REL_ "GenSigTimeoutTime" BU_SG_REL_ RRHV SG_ 1186 C_TeleRRSeatOpCmdIBOX 0;
BA_REL_ "GenSigTimeoutTime" BU_SG_REL_ SHVU_FR SG_ 1186 C_TeleRRSeatOpCmdIBOX 0;
BA_REL_ "GenSigTimeoutTime" BU_SG_REL_ SHVU_RR SG_ 1186 C_TeleRRSeatOpCmdIBOX 0;
BA_REL_ "GenSigTimeoutTime" BU_SG_REL_ ATS SG_ 1186 C_TeleRLSeatOpCmdIBOX 0;
BA_REL_ "GenSigTimeoutTime" BU_SG_REL_ GW_RLPSU SG_ 1186 C_TeleRLSeatOpCmdIBOX 0;
BA_REL_ "GenSigTimeoutTime" BU_SG_REL_ RLHV SG_ 1186 C_TeleRLSeatOpCmdIBOX 0;
BA_REL_ "GenSigTimeoutTime" BU_SG_REL_ SHVU_FR SG_ 1186 C_TeleRLSeatOpCmdIBOX 0;
BA_REL_ "GenSigTimeoutTime" BU_SG_REL_ SHVU_RR SG_ 1186 C_TeleRLSeatOpCmdIBOX 0;
BA_REL_ "GenSigTimeoutTime" BU_SG_REL_ RCM SG_ 1185 C_RrBlindCmdAVN 0;
BA_REL_ "GenSigTimeoutTime" BU_SG_REL_ RCM SG_ 1185 C_RrGlassCmdAVN 0;
BA_REL_ "GenSigTimeoutTime" BU_SG_REL_ RCM SG_ 1185 C_BlindCmdAVN 0;
BA_REL_ "GenSigTimeoutTime" BU_SG_REL_ RCM SG_ 1185 C_GlassCmdAVN 0;
VAL_ 2227254529 BAT_Crc1Val 0 "0x0x0~0xFFFF:CRCValue" 65535 "0x0x0~0xFFFF:CRCValue" ;
VAL_ 2227254529 BAT_AlvCnt1Val 0 "0x0x0~0xFF:AlvCntValue" 255 "0x0x0~0xFF:AlvCntValue" ;
VAL_ 2227254529 BAT_CurrVal 65535 "Error indicator" ;
VAL_ 2227254529 BAT_SocVal 255 "Error indicator" ;
VAL_ 2227254529 BAT_VoltVal 16383 "Error indicator" ;
VAL_ 2227254529 BAT_AuxBattOpt 0 "Not used" 1 "12V LFP Battery is applied" 2 "12V LFP Battery is not applied" 3 "Error indicator" ;
VAL_ 2227254530 BAT_TempVal 511 "Error indicator" ;
VAL_ 2227254530 BAT_SohVal 127 "Error indicator" ;
VAL_ 2227254530 BAT_SnsrInvldSta 0 "Valid Condition" 1 "Invalid Condition" 2 "Not used" 3 "Error indicator" ;
VAL_ 2227254530 BAT_SofVal 127 "Error indicator" ;
VAL_ 2227254530 BAT_RspErrSta 0 "Operating correctly" 1 "Response error" 2 "Not used" 3 "Error indicator" ;
VAL_ 2227254530 BAT_CapacityVal 255 "Error" ;
VAL_ 2227254530 BAT_SocErrSta 0 "Nomal State" 1 "Implausible State" 2 "Not used" 3 "Error indicator" ;
VAL_ 1266 HU_LanguageInfo 0 "Off" 1 "Korea" 2 "English(US)" 3 "English(UK)" 4 "Simplified chinese" 5 "Traditional chinese" 6 "French(EU)" 7 "Spanish(EU)" 8 "Arabic" 9 "Czech" 10 "Danish" 11 "German" 12 "Italian" 13 "Dutch" 14 "Polish" 15 "Portuguese" 16 "Russain" 17 "Slovak" 18 "Swedish" 19 "Turkish" 20 "French(US)" 21 "Spanish(US)" 22 "English(India)" 23 "Norwegian" 24 "Finnish" 25 "Indonesian" 26 "Brazilian Portuguese" 27 "Malay" 28 "Hungarian" 29 "English (Australia)" 30 "Japanese" 31 "Hindi" 32 "Hebrew" 33 "Greek" 34 "Ukrainian" 35 "Slovenian" 36 "Bulgarian" 37 "Croatian" 38 "Romanian" 39 "Bengali" 40 "Marathi" 41 "Telugu" 42 "Tamil" 43 "Gujarati" 44 "Kannada" 45 "Odia" 46 "Malayalam" 47 "Punjabi" 48 "Thai" 49 "Tagalog" 50 "Vietnamese" 51 "Lithuanian" 52 "Latvian" 53 "Estonian" 54 "0x36~0xFE:RESERVED" 254 "0x36~0xFE:RESERVED" 255 "Invalid" ;
VAL_ 1266 HU_MuteStatus 0 "Off" 1 "Mute On" 2 "RESERVED" 3 "Invalid" ;
VAL_ 1266 HU_WelcomeReady 0 "Default" 1 "Welcome ready" 2 "Goodbye ready" 3 "Invalid" ;
VAL_ 1266 HU_UsmSupport 0 "Not support" 1 "Support" 2 "RESERVED" 3 "Invalid" ;
VAL_ 1266 HU_NaviStatus 0 "Booting" 1 "Normal Operation" 2 "No SD Card(Map)" 3 "Invalid" ;
VAL_ 1266 HU_NaviDisp 0 "Non_Navi" 1 "Navi" 2 "RESERVED" 3 "Invalid" ;
VAL_ 1266 HU_BVM_Display_Message 0 "Not Used" 1 "No Message" 2 "Rain_Warning Message" 3 "RESERVED" 4 "RESERVED" 5 "RESERVED" 6 "RESERVED" 7 "Invalid" ;
VAL_ 1266 HU_NaviCamSettingStatus 0 "Navi Camera Alert Setting Status" 1 "Navi Camera Alert Setting Status" 2 "Navi Camera Alert Setting Status" 3 "Navi Camera Alert Setting Status" 4 "Navi Camera Alert Setting Status" 5 "Navi Camera Alert Setting Status" 6 "Navi Camera Alert Setting Status" 7 "Navi Camera Alert Setting Status" 8 "Navi Camera Alert Setting Status" 9 "Navi Camera Alert Setting Status" 10 "Navi Camera Alert Setting Status" 11 "Navi Camera Alert Setting Status" 12 "Navi Camera Alert Setting Status" 13 "Navi Camera Alert Setting Status" 14 "Navi Camera Alert Setting Status" 15 "Navi Camera Alert Setting Status" 16 "Navi Camera Alert Setting Status" 17 "Navi Camera Alert Setting Status" 18 "Navi Camera Alert Setting Status" 19 "Navi Camera Alert Setting Status" 20 "Navi Camera Alert Setting Status" 21 "Navi Camera Alert Setting Status" 22 "Navi Camera Alert Setting Status" 23 "Navi Camera Alert Setting Status" 24 "Navi Camera Alert Setting Status" 25 "Navi Camera Alert Setting Status" 26 "Navi Camera Alert Setting Status" 27 "Navi Camera Alert Setting Status" 28 "Navi Camera Alert Setting Status" 29 "Navi Camera Alert Setting Status" 30 "Navi Camera Alert Setting Status" 31 "Navi Camera Alert Setting Status" 32 "0x20~0xFE:RESERVED" 254 "0x20~0xFE:RESERVED" 255 "Invalid" ;
VAL_ 1266 HU_EVSupport 0 "Not support" 1 "Support" 2 "RESERVED" 3 "Invalid" ;
VAL_ 1266 HU_DayNightState 0 "Default" 1 "Day" 2 "Night" 3 "Invalid" ;
VAL_ 1266 HU_AutoBrightState_New 0 "Default" 1 "0x1~0x3FE:Brightness" 1022 "0x1~0x3FE:Brightness" 1023 "Invalid" ;
VAL_ 1266 HU_VolumeStatus 63 "Invalid" ;
VAL_ 1267 RSELockOnOff 0 "Unlock" 1 "LockOn" 2 "RESERVED" 3 "Invalid" ;
VAL_ 1267 HU_ClimateScrnState 0 "Other Screen" 1 "Front Climate Screen" 2 "Rear Climate Screen" 3 "Invalid (Default)" ;
VAL_ 1267 HU_Graphreset_Info 0 "No Action" 1 "Clear Request" 2 "RESERVED" 3 "Invalid" ;
VAL_ 1267 HU_VRActivity 0 "Deactivated" 1 "Activated" 2 "RESERVED" 3 "Invalid" ;
VAL_ 191 RL_SHVU_DTCdisplay 0 "DTC is not exist(Fail is not exist)" 1 "IGN2 Fuse Open Detection" 2 "Switch Input Detection at Same Time" 3 "NTC/Heating wire Open Detection" 4 "NTC+/NTC- Terminal Short Detection" 5 "NTC+/Heater+ Terminal Short Detection" 6 "NTC+/Heater-, Heater+/Heater-, Heater+/NTC- Terminal Short Detection" 7 "NTC+/Heater- Wiring Short Detection" 8 "NTC+/Heater-, Heater+/Heater-, Heater+/NTC- Wiring Short Detection" 9 "Target Temperature Dissatisfied" 10 "Blower+/Blower- Short, Blower+/Blower Speed, Blower-/Blower Speed Wiring Short Detection" 11 "Blower+/Blower RPM, Blower-/Blower RPM, Blower Speed/Blower RPM Short Detection" 12 "Blower+, Blower-, Blower Speed Signal open Detection" 13 "Blower RPM signal Open Detection" 14 "0xE~0xFD:RESERVED" 253 "0xE~0xFD:RESERVED" 254 "No Display" 255 "Invalid" ;
VAL_ 191 RL_SHVU_DiagMode 0 "Default" 1 "DTC Mode" 2 "Normal Mode" 3 "Invalid" ;
VAL_ 1264 HU_TimeSetting 0 "not used" 1 "User Time" 2 "GPS Time" 3 "invalid" ;
VAL_ 1264 HU_DisplayMinute 0 "0 minute" 1 "1~59 minute" 2 "1~59 minute" 3 "1~59 minute" 4 "1~59 minute" 5 "1~59 minute" 6 "1~59 minute" 7 "1~59 minute" 8 "1~59 minute" 9 "1~59 minute" 10 "1~59 minute" 11 "1~59 minute" 12 "1~59 minute" 13 "1~59 minute" 14 "1~59 minute" 15 "1~59 minute" 16 "1~59 minute" 17 "1~59 minute" 18 "1~59 minute" 19 "1~59 minute" 20 "1~59 minute" 21 "1~59 minute" 22 "1~59 minute" 23 "1~59 minute" 24 "1~59 minute" 25 "1~59 minute" 26 "1~59 minute" 27 "1~59 minute" 28 "1~59 minute" 29 "1~59 minute" 30 "1~59 minute" 31 "1~59 minute" 32 "1~59 minute" 33 "1~59 minute" 34 "1~59 minute" 35 "1~59 minute" 36 "1~59 minute" 37 "1~59 minute" 38 "1~59 minute" 39 "1~59 minute" 40 "1~59 minute" 41 "1~59 minute" 42 "1~59 minute" 43 "1~59 minute" 44 "1~59 minute" 45 "1~59 minute" 46 "1~59 minute" 47 "1~59 minute" 48 "1~59 minute" 49 "1~59 minute" 50 "1~59 minute" 51 "1~59 minute" 52 "1~59 minute" 53 "1~59 minute" 54 "1~59 minute" 55 "1~59 minute" 56 "1~59 minute" 57 "1~59 minute" 58 "1~59 minute" 59 "1~59 minute" 60 "0x3C~0xFE:RESERVED" 254 "0x3C~0xFE:RESERVED" 255 "Invalid" ;
VAL_ 1264 HU_Status 0 "Not used" 1 "Booting Head Unit" 2 "GPS receiving" 3 "Setting Mode" 4 "GPS Unavailable Mode" 5 "No GPS" 6 "RESERVED" 7 "RESERVED" 8 "RESERVED" 9 "RESERVED" 10 "RESERVED" 11 "RESERVED" 12 "RESERVED" 13 "RESERVED" 14 "RESERVED" 15 "Invalid" ;
VAL_ 1264 HU_DisplaySecond 0 "0 second" 1 "1~59 second" 2 "1~59 second" 3 "1~59 second" 4 "1~59 second" 5 "1~59 second" 6 "1~59 second" 7 "1~59 second" 8 "1~59 second" 9 "1~59 second" 10 "1~59 second" 11 "1~59 second" 12 "1~59 second" 13 "1~59 second" 14 "1~59 second" 15 "1~59 second" 16 "1~59 second" 17 "1~59 second" 18 "1~59 second" 19 "1~59 second" 20 "1~59 second" 21 "1~59 second" 22 "1~59 second" 23 "1~59 second" 24 "1~59 second" 25 "1~59 second" 26 "1~59 second" 27 "1~59 second" 28 "1~59 second" 29 "1~59 second" 30 "1~59 second" 31 "1~59 second" 32 "1~59 second" 33 "1~59 second" 34 "1~59 second" 35 "1~59 second" 36 "1~59 second" 37 "1~59 second" 38 "1~59 second" 39 "1~59 second" 40 "1~59 second" 41 "1~59 second" 42 "1~59 second" 43 "1~59 second" 44 "1~59 second" 45 "1~59 second" 46 "1~59 second" 47 "1~59 second" 48 "1~59 second" 49 "1~59 second" 50 "1~59 second" 51 "1~59 second" 52 "1~59 second" 53 "1~59 second" 54 "1~59 second" 55 "1~59 second" 56 "1~59 second" 57 "1~59 second" 58 "1~59 second" 59 "1~59 second" 60 "0x3C~0xFE:RESERVED" 254 "0x3C~0xFE:RESERVED" 255 "Invalid" ;
VAL_ 1264 HU_DisplayMonth 0 "Not used" 1 "1~12 month" 2 "1~12 month" 3 "1~12 month" 4 "1~12 month" 5 "1~12 month" 6 "1~12 month" 7 "1~12 month" 8 "1~12 month" 9 "1~12 month" 10 "1~12 month" 11 "1~12 month" 12 "1~12 month" 13 "RESERVED" 14 "RESERVED" 15 "Invalid" ;
VAL_ 1264 HU_DisplayYear1 0 "19" 1 "20" 2 "21" 3 "invalid" ;
VAL_ 1264 HU_DisplayYear2 0 "00 year" 1 "01~99 year" 2 "01~99 year" 3 "01~99 year" 4 "01~99 year" 5 "01~99 year" 6 "01~99 year" 7 "01~99 year" 8 "01~99 year" 9 "01~99 year" 10 "01~99 year" 11 "01~99 year" 12 "01~99 year" 13 "01~99 year" 14 "01~99 year" 15 "01~99 year" 16 "01~99 year" 17 "01~99 year" 18 "01~99 year" 19 "01~99 year" 20 "01~99 year" 21 "01~99 year" 22 "01~99 year" 23 "01~99 year" 24 "01~99 year" 25 "01~99 year" 26 "01~99 year" 27 "01~99 year" 28 "01~99 year" 29 "01~99 year" 30 "01~99 year" 31 "01~99 year" 32 "01~99 year" 33 "01~99 year" 34 "01~99 year" 35 "01~99 year" 36 "01~99 year" 37 "01~99 year" 38 "01~99 year" 39 "01~99 year" 40 "01~99 year" 41 "01~99 year" 42 "01~99 year" 43 "01~99 year" 44 "01~99 year" 45 "01~99 year" 46 "01~99 year" 47 "01~99 year" 48 "01~99 year" 49 "01~99 year" 50 "01~99 year" 51 "01~99 year" 52 "01~99 year" 53 "01~99 year" 54 "01~99 year" 55 "01~99 year" 56 "01~99 year" 57 "01~99 year" 58 "01~99 year" 59 "01~99 year" 60 "01~99 year" 61 "01~99 year" 62 "01~99 year" 63 "01~99 year" 64 "01~99 year" 65 "01~99 year" 66 "01~99 year" 67 "01~99 year" 68 "01~99 year" 69 "01~99 year" 70 "01~99 year" 71 "01~99 year" 72 "01~99 year" 73 "01~99 year" 74 "01~99 year" 75 "01~99 year" 76 "01~99 year" 77 "01~99 year" 78 "01~99 year" 79 "01~99 year" 80 "01~99 year" 81 "01~99 year" 82 "01~99 year" 83 "01~99 year" 84 "01~99 year" 85 "01~99 year" 86 "01~99 year" 87 "01~99 year" 88 "01~99 year" 89 "01~99 year" 90 "01~99 year" 91 "01~99 year" 92 "01~99 year" 93 "01~99 year" 94 "01~99 year" 95 "01~99 year" 96 "01~99 year" 97 "01~99 year" 98 "01~99 year" 99 "01~99 year" 100 "0x64~0xFE:RESERVED" 254 "0x64~0xFE:RESERVED" 255 "Invalid" ;
VAL_ 1264 HU_DisplayDay 0 "Not used" 1 "1~31 day" 2 "1~31 day" 3 "1~31 day" 4 "1~31 day" 5 "1~31 day" 6 "1~31 day" 7 "1~31 day" 8 "1~31 day" 9 "1~31 day" 10 "1~31 day" 11 "1~31 day" 12 "1~31 day" 13 "1~31 day" 14 "1~31 day" 15 "1~31 day" 16 "1~31 day" 17 "1~31 day" 18 "1~31 day" 19 "1~31 day" 20 "1~31 day" 21 "1~31 day" 22 "1~31 day" 23 "1~31 day" 24 "1~31 day" 25 "1~31 day" 26 "1~31 day" 27 "1~31 day" 28 "1~31 day" 29 "1~31 day" 30 "1~31 day" 31 "1~31 day" 32 "0x20~0xFE:RESERVED" 254 "0x20~0xFE:RESERVED" 255 "Invalid" ;
VAL_ 1264 HU_AM_PM_INFO 0 "Not Used" 1 "AM" 2 "PM" 3 "invalid" ;
VAL_ 1264 HU_TimeFormat 0 "Not used" 1 "12Hour" 2 "24Hour" 3 "invalid" ;
VAL_ 1264 HU_ComRefresh 0 "Not Used" 1 "Internal Clock None" 2 "Internal Clock Exist" 3 "Invalid" ;
VAL_ 1264 HU_ClockInfo 0 "Not Used" 1 "ACLOCK Refresh" 2 "Not Used" 3 "invalid" ;
VAL_ 1264 HU_DisplayHour 0 "0 hour" 1 "1~23 hour" 2 "1~23 hour" 3 "1~23 hour" 4 "1~23 hour" 5 "1~23 hour" 6 "1~23 hour" 7 "1~23 hour" 8 "1~23 hour" 9 "1~23 hour" 10 "1~23 hour" 11 "1~23 hour" 12 "1~23 hour" 13 "1~23 hour" 14 "1~23 hour" 15 "1~23 hour" 16 "1~23 hour" 17 "1~23 hour" 18 "1~23 hour" 19 "1~23 hour" 20 "1~23 hour" 21 "1~23 hour" 22 "1~23 hour" 23 "1~23 hour" 24 "0x18~0xFE:RESERVED" 254 "0x18~0xFE:RESERVED" 255 "Invalid" ;
VAL_ 1265 HU_IG3_Request 0 "Off" 1 "On" 2 "RESERVED" 3 "Invalid" ;
VAL_ 1265 HU_DigitalKeyGroupingSupport 0 "Default" 1 "Not supported" 2 "Support" 3 "RESERVED" ;
VAL_ 1265 HU_Background 0 "Default" 1 "Day" 2 "Night" 3 "RESERVED" 4 "RESERVED" 5 "RESERVED" 6 "RESERVED" 7 "Invalid" ;
VAL_ 1265 HU_BackgroundFadeInOut 0 "0x0x0~0x3E8:0.0~100.0%" 1000 "0x0x0~0x3E8:0.0~100.0%" 1001 "RESERVED" 1002 "RESERVED" 1003 "RESERVED" 1004 "RESERVED" 1005 "RESERVED" 1006 "RESERVED" 1007 "RESERVED" 1008 "RESERVED" 1009 "RESERVED" 1010 "RESERVED" 1011 "RESERVED" 1012 "RESERVED" 1013 "RESERVED" 1014 "RESERVED" 1015 "RESERVED" 1016 "RESERVED" 1017 "RESERVED" 1018 "RESERVED" 1019 "RESERVED" 1020 "RESERVED" 1021 "RESERVED" 1022 "Default" 1023 "Invalid" ;
VAL_ 1265 CF_AVN_AutoWashModeSta 0 "Default" 1 "Non Auto Wash Mode" 2 "Auto Wash Mode" 3 "RESERVED" 4 "RESERVED" 5 "RESERVED" 6 "RESERVED" 7 "Invalid" ;
VAL_ 1265 CRS_BabyOnSeatstates 0 "Default" 1 "Children not seating" 2 "Children seating" 3 "Invalid" ;
VAL_ 1265 OMUOSMirCtrl_Vr 0 "Off" 1 "Fold" 2 "Unfold" 3 "invalid" ;
VAL_ 2328016132 VCU_AvnDteCorFacVal 200 "RESERVED" 201 "RESERVED" 202 "RESERVED" 203 "RESERVED" 204 "RESERVED" 205 "RESERVED" 206 "RESERVED" 207 "RESERVED" 208 "RESERVED" 209 "RESERVED" 210 "RESERVED" 211 "RESERVED" 212 "RESERVED" 213 "RESERVED" 214 "RESERVED" 215 "RESERVED" 216 "RESERVED" 217 "RESERVED" 218 "RESERVED" 219 "RESERVED" 220 "RESERVED" 221 "RESERVED" 222 "RESERVED" 223 "RESERVED" 224 "RESERVED" 225 "RESERVED" 226 "RESERVED" 227 "RESERVED" 228 "RESERVED" 229 "RESERVED" 230 "RESERVED" 231 "RESERVED" 232 "RESERVED" 233 "RESERVED" 234 "RESERVED" 235 "RESERVED" 236 "RESERVED" 237 "RESERVED" 238 "RESERVED" 239 "RESERVED" 240 "RESERVED" 241 "RESERVED" 242 "RESERVED" 243 "RESERVED" 244 "RESERVED" 245 "RESERVED" 246 "RESERVED" 247 "RESERVED" 248 "RESERVED" 249 "RESERVED" 250 "RESERVED" 251 "RESERVED" 252 "RESERVED" 253 "RESERVED" 254 "RESERVED" 255 "Invalid" ;
VAL_ 2328016132 VCU_DteGuidePosVal 121 "RESERVED" 122 "RESERVED" 123 "RESERVED" 124 "RESERVED" 125 "RESERVED" 126 "RESERVED" 127 "Invalid" ;
VAL_ 2328016132 VCU_StopCtrlWarnMsgSta 0 "None" 1 "i-Pedal On Popup Request" 2 "Smart  Regen On Popup Request" 3 "Smart Regen Off Popup Request" 4 "SAC Off Popup Request" 5 "RESERVED" 6 "RESERVED" 7 "RESERVED" ;
VAL_ 2328016132 VCU_DrvModeDefault 0 "No Data" 1 "Normal (Comfort)" 2 "ECO" 3 "Reserved" ;
VAL_ 1278 HU_Type 0 "RESERVED" 1 "RESERVED" 2 "RESERVED" 3 "RESERVED" 4 "RESERVED" 5 "RESERVED" 6 "RESERVED" 7 "RESERVED" 8 "RESERVED" 9 "RESERVED" 10 "RESERVED" 11 "RESERVED" 12 "RESERVED" 13 "RESERVED" 14 "RESERVED" 15 "RESERVED" 16 "AVN(Tuner DVD KOR)" 17 "AVN(Tuner DVD EUR)" 18 "AVN(Tuner DVD China)" 19 "AVN(Tuner DVD Japan)" 20 "AVN(Tuner DVD EUR)" 21 "AVN(Tuner CDP KOR)" 22 "AVN(Tuner CDP EUR)" 23 "AVN(Tuner CDP China)" 24 "AVN(Tuner CDP Japan)" 25 "AVN(Tuner CDP EUR)" 26 "RESERVED" 27 "RESERVED" 28 "RESERVED" 29 "RESERVED" 30 "RESERVED" 31 "RESERVED" 32 "AVNT (Open)" 33 "AVNT (Not open)" 34 "RESERVED" 35 "RESERVED" 36 "RESERVED" 37 "RESERVED" 38 "RESERVED" 39 "RESERVED" 40 "RESERVED" 41 "RESERVED" 42 "RESERVED" 43 "RESERVED" 44 "RESERVED" 45 "RESERVED" 46 "RESERVED" 47 "RESERVED" 48 "Economic Audio" 49 "RESERVED" 50 "RESERVED" 51 "RESERVED" 52 "RESERVED" 53 "RESERVED" 54 "RESERVED" 55 "RESERVED" 56 "RESERVED" 57 "RESERVED" 58 "RESERVED" 59 "RESERVED" 60 "RESERVED" 61 "RESERVED" 62 "RESERVED" 63 "RESERVED" 64 "Standard Audio (3.0 below)" 65 "Standard Audio 4.0" 66 "STD Audio-3.0Below,No interwork" 67 "Audio 4.0 Value" 68 "RESERVED" 69 "RESERVED" 70 "RESERVED" 71 "RESERVED" 72 "RESERVED" 73 "RESERVED" 74 "RESERVED" 75 "RESERVED" 76 "RESERVED" 77 "RESERVED" 78 "RESERVED" 79 "RESERVED" 80 "AV(Tuner DVD KOR)" 81 "AV(Tuner DVD EUR)" 82 "AV(Tuner DVD China)" 83 "AV(Tuner DVD Japan)" 84 "AV(Tuner DVD EUR)" 85 "AV(Tuner CDP KOR)" 86 "AV(Tuner CDP EUR)" 87 "AV(Tuner CDP China)" 88 "AV(Tuner CDP Japan)" 89 "AV(Tuner CDP EUR)" 90 "RESERVED" 91 "RESERVED" 92 "RESERVED" 93 "RESERVED" 94 "RESERVED" 95 "RESERVED" 96 "AVN 4.0" 97 "Premium AVN2.0" 98 "EU AVN 2.0" 99 "Super Premium w Navi" 100 "Super Premium w_o Navi" 101 "Premium w Navi" 102 "Premium w_o Navi" 103 "Display Audio w_o Navi" 104 "Integrated AVN 1.0 Mobis" 105 "Gen5 Standard Nav Wide" 106 "RESERVED" 107 "RESERVED" 108 "RESERVED" 109 "RESERVED" 110 "RESERVED" 111 "RESERVED" 112 "Compact AVN & Integrated AVN 1.0 LG" 113 "RESERVED" 114 "RESERVED" 115 "RESERVED" 116 "RESERVED" 117 "RESERVED" 118 "RESERVED" 119 "RESERVED" 120 "RESERVED" 121 "RESERVED" 122 "RESERVED" 123 "RESERVED" 124 "RESERVED" 125 "RESERVED" 126 "RESERVED" 127 "RESERVED" 128 "Premium Navi 5th Gen(w_Navi)" 129 "Premium Navi 5th Gen(w_o Navi)" 130 "Premium Navi 6th Gen(w_Navi)" 131 "Premium Navi 6th Gen(w_o Navi)" 132 "ccNC(w Navi)" 133 "ccNC(w_o Navi)" 134 "ccIC(w Navi)" 135 "ccIC(w_o Navi)" 136 "RESERVED" 137 "RESERVED" 138 "RESERVED" 139 "RESERVED" 140 "RESERVED" 141 "RESERVED" 142 "RESERVED" 143 "RESERVED" 144 "P-OIP (w_Navi)" 145 "P-OIP (w_o Navi)" 146 "S-OIP (w_Navi)" 147 "S-OIP (w_o Navi)" 148 "PBV IVI (w_Navi)" 149 "PBV IVI (w_o Navi)" 150 "RESERVED" 151 "RESERVED" 152 "RESERVED" 153 "RESERVED" 154 "RESERVED" 155 "RESERVED" 156 "RESERVED" 157 "RESERVED" 158 "RESERVED" 159 "RESERVED" 160 "RESERVED" 161 "RESERVED" 162 "RESERVED" 163 "RESERVED" 164 "RESERVED" 165 "RESERVED" 166 "RESERVED" 167 "RESERVED" 168 "RESERVED" 169 "RESERVED" 170 "RESERVED" 171 "RESERVED" 172 "RESERVED" 173 "RESERVED" 174 "RESERVED" 175 "RESERVED" 176 "RESERVED" 177 "RESERVED" 178 "RESERVED" 179 "RESERVED" 180 "RESERVED" 181 "RESERVED" 182 "RESERVED" 183 "RESERVED" 184 "RESERVED" 185 "RESERVED" 186 "RESERVED" 187 "RESERVED" 188 "RESERVED" 189 "RESERVED" 190 "RESERVED" 191 "RESERVED" 192 "RESERVED" 193 "RESERVED" 194 "RESERVED" 195 "RESERVED" 196 "RESERVED" 197 "RESERVED" 198 "RESERVED" 199 "RESERVED" 200 "RESERVED" 201 "RESERVED" 202 "RESERVED" 203 "RESERVED" 204 "RESERVED" 205 "RESERVED" 206 "RESERVED" 207 "RESERVED" 208 "RESERVED" 209 "RESERVED" 210 "RESERVED" 211 "RESERVED" 212 "RESERVED" 213 "RESERVED" 214 "RESERVED" 215 "RESERVED" 216 "RESERVED" 217 "RESERVED" 218 "RESERVED" 219 "RESERVED" 220 "RESERVED" 221 "RESERVED" 222 "RESERVED" 223 "RESERVED" 224 "RESERVED" 225 "RESERVED" 226 "RESERVED" 227 "RESERVED" 228 "RESERVED" 229 "RESERVED" 230 "RESERVED" 231 "RESERVED" 232 "RESERVED" 233 "RESERVED" 234 "RESERVED" 235 "RESERVED" 236 "RESERVED" 237 "RESERVED" 238 "India PIO w_o CLU interface" 239 "India PIO w_CLU interface" 240 "RESERVED" 241 "Gen 1 China OEM Navigation" 242 "RESERVED" 243 "RESERVED" 244 "RESERVED" 245 "RESERVED" 246 "RESERVED" 247 "RESERVED" 248 "RESERVED" 249 "RESERVED" 250 "PIO AVN" 251 "China  Local OEM Display Audio" 252 "China OPIO w_o CLU interface" 253 "China OPIO w_CLU interface" 254 "China Local OEM AVNT" 255 "Invalid" ;
VAL_ 1278 HU_DistributeInfo 0 "Default (Korea)" 1 "Korea" 2 "North America" 3 "Canada" 4 "East Europe" 5 "West Europe" 6 "China" 7 "India" 8 "Australia" 9 "Middle East" 10 "Africa" 11 "South America" 12 "Russia" 13 "Japan" 14 "General" 15 "0x0F~0xFE:Reserved" 254 "0x0F~0xFE:Reserved" 255 "Invalid" ;
VAL_ 1278 HU_OptionInfo 0 "0x0x0000~0x0FFF:Bit allocation" 4095 "0x0x0000~0x0FFF:Bit allocation" 4096 "0x1000~0x7FFF:RESERVED" 32767 "0x1000~0x7FFF:RESERVED" 32768 "Invalid" 32769 "0x8001~0xFFFF:Not used" 65535 "0x8001~0xFFFF:Not used" ;
VAL_ 1278 HU_NaviHandshakingSupport 0 "Not Support" 1 "Support" 2 "Unknown" 3 "Invalid" ;
VAL_ 1278 HU_AMP_EQVariant 0 "Default" 1 "WGN" 2 "WGN PHEV" 3 "5DR" 4 "SB" 5 "CUV" 6 "HEV" 7 "PHEV" 8 "EV" 9 "Reserved" 10 "Reserved" 11 "Reserved" 12 "Reserved" 13 "Reserved" 14 "Reserved" 15 "Reserved" 16 "Reserved" 17 "Reserved" 18 "Reserved" 19 "Reserved" 20 "Reserved" 21 "Reserved" 22 "Reserved" 23 "Reserved" 24 "Reserved" 25 "Reserved" 26 "Reserved" 27 "Reserved" 28 "Reserved" 29 "Reserved" 30 "Reserved" ;
VAL_ 1278 HU_AdasSupport 0 "Not Support" 1 "ADAS Support(General Map)" 2 "ADAS Support(Map based ADAS v1)" 3 "ADAS Support(Map based ADAS v2)" 4 "ADAS Support(Map based ADAS v2 & Handshaking)" 5 "ADAS Support(Map based ADAS v2_3)" 6 "Reserved" 7 "Invalid" ;
VAL_ 1278 HU_Navi_RspADASMapMsg 0 "0x0x0~0xFFFF:Refer to Signal Description" 65535 "0x0x0~0xFFFF:Refer to Signal Description" ;
VAL_ 1279 USM_SmartRegen_Map_Set 0 "Default" 1 "Off(Disbaled)" 2 "On(Enabled)" 3 "Invalid" ;
VAL_ 1279 USM_SmartRegen_Sens_Set 0 "Default" 1 "Slow" 2 "Normal" 3 "Fast" 4 "Reserved" 5 "Reserved" 6 "Reserved" 7 "Invalid" ;
VAL_ 1279 AVN_SeatPosMemory_Btn 0 "Default" 1 "Memory 1" 2 "Memory 2" 3 "Memory 3" 4 "Reserved" 5 "Reserved" 6 "Reserved" 7 "Invalid" ;
VAL_ 1279 AVN_SeatPosPlyBck_Btn 0 "Default" 1 "Memory 1" 2 "Memory 2" 3 "Memory 3" 4 "Reserved" 5 "Reserved" 6 "Stop" 7 "Invalid" ;
VAL_ 1279 USM_RhstaLvlEnaSetReq 0 "Default" 1 "Off" 2 "On" 3 "Invalid" ;
VAL_ 1279 USM_CMSDayBrgtnsLvlLHSetReq 0 "-5 Level" 1 "-4 Level" 2 "-3 Level" 3 "-2 Level" 4 "-1 Level" 5 "0 Level" 6 "1 Level" 7 "2 Level" 8 "3 Level" 9 "4 Level" 10 "5 Level" 11 "Not Used" 12 "Not Used" 13 "Not Used" 14 "Error Indicator" 15 "Invalid" ;
VAL_ 1279 USM_CMSNgtBrgtnsLvlLHSetReq 0 "-5 Level" 1 "-4 Level" 2 "-3 Level" 3 "-2 Level" 4 "-1 Level" 5 "0 Level" 6 "1 Level" 7 "2 Level" 8 "3 Level" 9 "4 Level" 10 "5 Level" 11 "Not Used" 12 "Not Used" 13 "Not Used" 14 "Error Indicator" 15 "Invalid" ;
VAL_ 1279 USM_CMSDayBrgtnsLvlRHSetReq 0 "-5 Level" 1 "-4 Level" 2 "-3 Level" 3 "-2 Level" 4 "-1 Level" 5 "0 Level" 6 "1 Level" 7 "2 Level" 8 "3 Level" 9 "4 Level" 10 "5 Level" 11 "Not Used" 12 "Not Used" 13 "Not Used" 14 "Error Indicator" 15 "Invalid" ;
VAL_ 1279 USM_CMSNgtBrgtnsLvlRHSetReq 0 "-5 Level" 1 "-4 Level" 2 "-3 Level" 3 "-2 Level" 4 "-1 Level" 5 "0 Level" 6 "1 Level" 7 "2 Level" 8 "3 Level" 9 "4 Level" 10 "5 Level" 11 "Not Used" 12 "Not Used" 13 "Not Used" 14 "Error Indicator" 15 "Invalid" ;
VAL_ 1279 USM_CMSBrgtnsReset 0 "Default" 1 "Reset" 2 "Reserved" 3 "Invalid" ;
VAL_ 1279 USM_TurnDistLnDispSetReq 0 "Default" 1 "Off" 2 "On" 3 "Invalid" ;
VAL_ 1279 PCA_FrSd_NValueSet 0 "Default" 1 "Off" 2 "On" 3 "Invalid" ;
VAL_ 1279 CF_AVN_1stRrStRmndNValueSet 0 "Default" 1 "Off" 2 "On" 3 "Invalid" ;
VAL_ 1279 C_AllDrOpnNValueSet 0 "Default" 1 "Off" 2 "PSD Open" 3 "PSD PTG Open" 4 "Reserved" 5 "Reserved" 6 "Reserved" 7 "Invalid" ;
VAL_ 1279 USM_RpmECOSet 0 "Default" 1 "Off" 2 "On(RPM Gauge Display)" 3 "Invalid" ;
VAL_ 1279 VESS_ChgGuideMdLvl 0 "Default" 1 "Level 1(¾àÇÏ°Ô)" 2 "Level 2(Áß°£)" 3 "Level 3(°­ÇÏ°Ô)" 4 "Reserved" 5 "Reserved" 6 "Off" 7 "Invalid" ;
VAL_ 1279 Usm_RpmSPORTSet 0 "Default" 1 "Off" 2 "On(RPM Gauge Display)" 3 "Invalid" ;
VAL_ 1279 Usm_RpmSPORTPLUSSet 0 "Default" 1 "Off" 2 "On(RPM Gauge Display)" 3 "Invalid" ;
VAL_ 2328016129 VCU_Crc5Val 0 "0x0x0~0xFFFF:CRCValue" 65535 "0x0x0~0xFFFF:CRCValue" ;
VAL_ 2328016129 VCU_AlvCnt5Val 0 "0x0x0~0xFF:AlvCntValue" 255 "0x0x0~0xFF:AlvCntValue" ;
VAL_ 2328016129 VCU_EvDrvRdyCluDispSta 0 "Ready Lamp Off" 1 "Ready Lamp On" 2 "Error Indicator" 3 "Blinking" ;
VAL_ 2328016129 VCU_PwrDnModeSta 0 "None" 1 "Set" 2 "Not used" 3 "Error Indicator" ;
VAL_ 2328016129 VCU_CluWarnMsgSta 0 "None(Default)" 1 "Regenerative Braking System Operating Stop" 2 "Regenerative Braking System Off by low temperature" 3 "Regenerative Braking System On" 4 "RESERVED" 5 "RESERVED" 6 "RESERVED" 7 "RESERVED" 8 "RESERVED" 9 "RESERVED" 10 "RESERVED" 11 "RESERVED" 12 "RESERVED" 13 "RESERVED" 14 "RESERVED" 15 "RESERVED" ;
VAL_ 2328016129 VCU_DteOffDispSta 0 "None" 1 "DTE Off('---' Display)" 2 "Not used" 3 "Error Indicator" ;
VAL_ 2328016129 VCU_LowSocAlertSta 0 "No Alert" 1 "Low SOC Alert 1" 2 "Low SOC Alert 2" 3 "Low SOC Alert 3" 4 "Reserved" 5 "Reserved" 6 "Reserved" 7 "SOC Unavailable Alert" ;
VAL_ 2328016129 VCU_VcrmReq 0 "Wait(Not Request Logging)" 1 "Service/MIL Lamp On(Request Logging)" 2 "Warning, Abnormal IG Off(Request Logging)" 3 "Reserved" ;
VAL_ 2328016129 VCU_PdlWarnMsgSta 0 "None" 1 "Pop-up Request" 2 "Not used" 3 "Error Indicator" ;
VAL_ 2328016129 VCU_AwdDiagDispSta 0 "Off" 1 "On" 2 "NotUsed" 3 "ErrorIndicator" ;
VAL_ 2328016129 VCU_AwdLockDispSta 0 "Off" 1 "On" 2 "NotUsed" 3 "ErrorIndicator" ;
VAL_ 2328016129 VCU_VirtualApsActSta 0 "Real APS" 1 "Virtual APS for Crz" 2 "Not used" 3 "Error Indicator" ;
VAL_ 2328016129 VCU_ServiceLampReq 0 "None" 1 "Service Lamp On" 2 "Not used" 3 "Error Indicator" ;
VAL_ 2328016129 VCU_ServiceModeSta 0 "Normal" 1 "Certification Mode (F)" 2 "Certification Mode (R)" 3 "Error Indicator" ;
VAL_ 2328016129 VCU_NPosWshModSta 0 "Normal" 1 "Standby" 2 "N Wash Mode" 3 "Reserved" ;
VAL_ 2328016129 VCU_PowerTrainType 0 "One Moter" 1 "Dual Motor(Base)" 2 "Dual Motor(Performance)" 3 "Reserved" ;
VAL_ 2328016130 VCU_AvnDteOnCalcSta 0 "Display DTE Value" 1 "Display 'Recalculating'" 2 "Not used" 3 "Error Indicator" ;
VAL_ 2328016130 VCU_SbwWarnMsgSta 0 "Off" 1 "Warning 1 - SCU/Parking System Failure" 2 "Warning 2 - Unavailable to Shift Gear" 3 "Warning 3 - Brake On for Gear Shift" 4 "Warning 4 - Unavailable to Park" 5 "Warning 5 - Auto Parked" 6 "Warning 6 - Unavailable to Release Park" 7 "Warning 7 - Same Button Re-Entered" ;
VAL_ 2328016130 VCU_EnergyFlowSta 0 "None" 1 "No Flow" 2 "Front Motor Motoring" 3 "Rear Motor Motoring" 4 "Dual Motor Motoring" 5 "Not Used" 6 "Front Motor Generating" 7 "Rear Motor Generating" 8 "Dual Motor Generating" 9 "Not Used" 10 "Reserved" 11 "Reserved" 12 "Reserved" 13 "Reserved" 14 "Reserved" 15 "Reserved" ;
VAL_ 2328016130 VCU_SbwWarnSndSta 0 "Warning Sound Off" 1 "Warning Sound On" 2 "Not used" 3 "Error Indicator" ;
VAL_ 2328016130 VCU_DteInfoPageSta 0 "Off" 1 "On" 2 "Blank" 3 "Recalculate" 4 "RESERVED" 5 "RESERVED" 6 "RESERVED" 7 "Invaild" ;
VAL_ 2328016131 VCU_DistFromRegenDispReq 0 "Default" 1 "Displayed ---" 2 "Positive Value" 3 "Negative Value" ;
VAL_ 2328016131 VCU_DteGaugePosVal 121 "RESERVED" 122 "RESERVED" 123 "RESERVED" 124 "RESERVED" 125 "RESERVED" 126 "RESERVED" 127 "Invalid" ;
VAL_ 2328016131 VCU_LowSocDispSt1PcVal 0 "0x0x0~0x64:0~100" 100 "0x0x0~0x64:0~100" 101 "Invalid" 102 "Invalid" 103 "Invalid" 104 "Invalid" 105 "Invalid" 106 "Invalid" 107 "Invalid" 108 "Invalid" 109 "Invalid" 110 "Invalid" 111 "Invalid" 112 "Invalid" 113 "Invalid" 114 "Invalid" 115 "Invalid" 116 "Invalid" 117 "Invalid" 118 "Invalid" 119 "Invalid" 120 "Invalid" 121 "Invalid" 122 "Invalid" 123 "Invalid" 124 "Invalid" 125 "Invalid" 126 "Invalid" 127 "Invalid" ;
VAL_ 200 CF_AVN_ADrLNValueSet_2 0 "Default" 1 "Off" 2 "Vehicle Speed On (15km/h)" 3 "Vehicle Speed On and Shift Lever On" 4 "Invalid" 5 "Reserved" 6 "Reserved" 7 "Reserved" ;
VAL_ 200 CF_AVN_FCA_JC_OnOffEquipNvalueSe 0 "Default" 1 "Off" 2 "On" 3 "Invalid" ;
VAL_ 200 CF_AVN_FCA_FrSdOnOffEquipNvalueS 0 "Default" 1 "Off" 2 "On" 3 "Invalid" ;
VAL_ 200 CF_AVN_LKA_OnOffEquip2NvalueSet 0 "Default" 1 "Off" 2 "On" 3 "Invalid" ;
VAL_ 200 CF_AVN_BCA_OnOffEquip2NvalueSet 0 "Default" 1 "Off" 2 "On" 3 "Invalid" ;
VAL_ 200 CF_AVN_BVM_OnOffEquipNvalueSet 0 "Default" 1 "Off" 2 "On" 3 "Invalid" ;
VAL_ 200 CF_AVN_SEA_OnOffEquip3NvalueSet 0 "Default" 1 "Off" 2 "On" 3 "Invalid" ;
VAL_ 200 CF_AVN_BodySpprtSet_AST 0 "Default" 1 "Off" 2 "On" 3 "Invalid" ;
VAL_ 200 CF_AVN_SEW_OnOffEquip3NvalueSet 0 "Default" 1 "Off" 2 "On" 3 "Invalid" ;
VAL_ 200 CF_AVN_HudImsAutoSave 0 "Default" 1 "Off" 2 "On" 3 "Invalid" ;
VAL_ 200 USM_PwrDrBuzzerNValueSet 0 "Default" 1 "Off" 2 "On" 3 "Invalid" ;
VAL_ 200 CF_AVN_DWLNValueSet 0 "Default" 1 "Comfort" 2 "Natural" 3 "Dynamic" 4 "Reserved" 5 "Reserved" 6 "Reserved" 7 "Invalid" ;
VAL_ 200 CF_AVN_AirSptTimeNValueSet_AST 0 "Default" 1 "Short" 2 "Normal" 3 "Long" 4 "Reserved" 5 "Reserved" 6 "Reserved" 7 "Invalid" ;
VAL_ 200 CF_AVN_AirSptStrNValue_AST 0 "Default" 1 "Normal" 2 "Intense" 3 "Invalid" ;
VAL_ 200 CF_AVN_SeatDrvModNvalueSet_AST 0 "Default" 1 "Off" 2 "On" 3 "Invalid" ;
VAL_ 200 CF_AVN_TPMS_TireReplaceNValueSet 0 "Default" 1 "Off(Standard)" 2 "ON(SnowChain)" 3 "Reserved" 4 "Reserved" 5 "Reserved" 6 "Not Used(Gray)" 7 "Error Indicator" ;
VAL_ 200 CF_AVN_TowModeSet 0 "Default" 1 "Off" 2 "Small Weight" 3 "Medium Weight" 4 "Maximum Weight" 5 "Reserved" 6 "Reserved" 7 "Invalid" ;
VAL_ 200 USM_PwrDrCloseByBraekNValueSet 0 "Default" 1 "Off" 2 "On" 3 "Invalid" ;
VAL_ 200 CF_AVN_ISLANAOffstNvalueSet 0 "Default" 1 "-10kph -10mph" 2 "-5kph -5mph" 3 "0kph 0mph" 4 "5kph 5mph" 5 "10kph 10mph" 6 "Reserved" 7 "Invalid" ;
VAL_ 200 CF_Gway_WPC2_NValueSet 0 "Default" 1 "Off (Disable)" 2 "On (Enable)" 3 "Invalid" ;
VAL_ 200 USM_DrvGhostDoorReq 0 "Default" 1 "Off" 2 "On" 3 "Invalid" ;
VAL_ 200 USM_AstGhostDoorReq 0 "Default" 1 "Off" 2 "On" 3 "Invalid" ;
VAL_ 200 USM_RLGhostDoorReq 0 "Default" 1 "Off" 2 "On" 3 "Invalid" ;
VAL_ 200 CF_AVN_FCA_FrOnOffEquipNvalueSet 0 "Default" 1 "Off" 2 "On" 3 "Invalid" ;
VAL_ 200 CF_AVN_FCA_WarnTimeNvalueSet 0 "Default" 1 "Late" 2 "Normal" 3 "Reserved" 4 "Reserved" 5 "Reserved" 6 "Reserved" 7 "Invalid" ;
VAL_ 1159 C_AstRclBwdSw_HU 0 "Default" 1 "Off" 2 "On" 3 "Invalid" ;
VAL_ 1159 C_AstHeightUpSw_HU 0 "Default" 1 "Off" 2 "On" 3 "Invalid" ;
VAL_ 1159 C_AstTiltDnSw_HU 0 "Default" 1 "Off" 2 "On" 3 "Invalid" ;
VAL_ 1159 C_AstTiltUpSw_HU 0 "Default" 1 "Off" 2 "On" 3 "Invalid" ;
VAL_ 1159 C_AstLumbarDefSw_HU 0 "Default" 1 "Off" 2 "On" 3 "Invalid" ;
VAL_ 1159 C_AstLumbarLowSw_HU 0 "Default" 1 "Off" 2 "On" 3 "Invalid" ;
VAL_ 1159 C_AstRclFwdSw_HU 0 "Default" 1 "Off" 2 "On" 3 "Invalid" ;
VAL_ 1159 C_AstLumbarMidSw_HU 0 "Default" 1 "Off" 2 "On" 3 "Invalid" ;
VAL_ 1159 C_AstLumbarUpSw_HU 0 "Default" 1 "Off" 2 "On" 3 "Invalid" ;
VAL_ 1159 C_RRSlideFwdSw_HU 0 "Default" 1 "Off" 2 "On" 3 "Invalid" ;
VAL_ 1159 C_RRSlideBwdSw_HU 0 "Default" 1 "Off" 2 "On" 3 "Invalid" ;
VAL_ 1159 C_RLSlideFwdSw_HU 0 "Default" 1 "Off" 2 "On" 3 "Invalid" ;
VAL_ 1159 C_RLSlideBwdSw_HU 0 "Default" 1 "Off" 2 "On" 3 "Invalid" ;
VAL_ 1159 C_AstSlideBwdSw_HU 0 "Default" 1 "Off" 2 "On" 3 "Invalid" ;
VAL_ 1159 C_AstSlideFwdSw_HU 0 "Default" 1 "Off" 2 "On" 3 "Invalid" ;
VAL_ 1159 C_AstHeightDnSw_HU 0 "Default" 1 "Off" 2 "On" 3 "Invalid" ;
VAL_ 197 C_RLLegSupFwdSw_HU 0 "Default" 1 "Off" 2 "On" 3 "Invalid" ;
VAL_ 197 C_RLLegSupBwdSw_HU 0 "Default" 1 "Off" 2 "On" 3 "Invalid" ;
VAL_ 197 C_RLLegSupUpSw_HU 0 "Default" 1 "Off" 2 "On" 3 "Invalid" ;
VAL_ 197 C_RLLegSupDnSw_HU 0 "Default" 1 "Off" 2 "On" 3 "Invalid" ;
VAL_ 1165 RLMSS_OnOffBtn_AVN 0 "Default" 1 "Off" 2 "On" 3 "Invalid" ;
VAL_ 2382595073 DATC_Crc7Val 0 "0x0x0~0xFFFF:CRCValue" 65535 "0x0x0~0xFFFF:CRCValue" ;
VAL_ 2382595073 DATC_AlvCnt7Val 0 "0x0x0~0xFF:AlvCntValue" 255 "0x0x0~0xFF:AlvCntValue" ;
VAL_ 2382595073 DATC_FrDrvBlwDis 0 "OFF" 1 "Blank Display" 2 "1 Step" 3 "2 Step" 4 "3 Step" 5 "4 Step" 6 "5 Step" 7 "6 Step" 8 "7 Step" 9 "8 Step" 10 "BLOWER AUTO" 11 "Reserved" 12 "Reserved" 13 "Reserved" 14 "Reserved" 15 "Error Indicator" ;
VAL_ 2382595073 DATC_FrPsBlwDis 0 "OFF" 1 "Blank Display(Blower ´Ü¼ö ¹ÌÇ¥½Ã, ¿¹)Auto ½Ã)" 2 "1 Step" 3 "2 Step" 4 "3 Step" 5 "4 Step" 6 "5 Step" 7 "6 Step" 8 "7 Step" 9 "8 Step" 10 "BLOWER AUTO" 11 "Reserved" 12 "Reserved" 13 "Reserved" 14 "Reserved" 15 "Error Indicator" ;
VAL_ 2382595073 DATC_DrvOnlyDis 0 "Initial (Dual Temp Display)" 1 "Driver Only Status (Only Display Driver Temp)" 2 "Not used" 3 "Error Indicator" ;
VAL_ 2382595073 DATC_DiagCodeDis 0 "Blank Display(Default)" 1 "0x01~0x3FE:0~1023(PHY=(HEX*1.0-1.0))" 1022 "0x01~0x3FE:0~1023(PHY=(HEX*1.0-1.0))" 1023 "Error Indicator" ;
VAL_ 2382595073 DATC_RrChgReqDis 0 "Not requested" 1 "User Input" 2 "Not used" 3 "Error Indicator" ;
VAL_ 2382595073 DATC_RrClmtScrnDis 0 "Deactived" 1 "Actived" 2 "Not used" 3 "Error Indicator" ;
VAL_ 2382595073 DATC_AUTOStep 0 "Default" 1 "OFF" 2 "1st & 2nd & 3rd On (3 Step Type)" 3 "1st & 2nd On (3 Step Type)" 4 "1st On (3 Step Type)" 5 "1st & 2nd On (2 Step Type)" 6 "1st On (2 Step Type)" 7 "Reserved" 8 "Reserved" 9 "Reserved" 10 "Reserved" 11 "Reserved" 12 "Reserved" 13 "Reserved" 14 "Reserved" 15 "Error Indicator" ;
VAL_ 2382595073 DATC_IntakeDis 0 "Default (Fresh off & Rec off)" 1 "REC (Fresh off)" 2 "FRE (REC off)" 3 "Error indicator" ;
VAL_ 2382595073 DATC_MultiAirModSta 0 "Default" 1 "OFF" 2 "ON" 3 "Error Indicator" ;
VAL_ 1167 ICU_Crc11Val 0 "0x0x0~0xFF:CRCValue" 255 "0x0x0~0xFF:CRCValue" ;
VAL_ 1167 Bat_dischrg 0 "Flag OFF" 1 "Flag ON" 2 "RESERVED" 3 "RESERVED" ;
VAL_ 1167 ICU_AlvCnt11Val 0 "AlvCntValue" 1 "AlvCntValue" 2 "AlvCntValue" 3 "AlvCntValue" 4 "AlvCntValue" 5 "AlvCntValue" 6 "AlvCntValue" 7 "AlvCntValue" 8 "AlvCntValue" 9 "AlvCntValue" 10 "AlvCntValue" 11 "AlvCntValue" 12 "AlvCntValue" 13 "AlvCntValue" 14 "AlvCntValue" 15 "AlvCntValue" ;
VAL_ 1167 Batt_SoCWarningValue 0 "0x0x0~0x64:0 ~ 100%" 100 "0x0x0~0x64:0 ~ 100%" 101 "0x65~0xFE:RESERVED" 254 "0x65~0xFE:RESERVED" 255 "Invalid" ;
VAL_ 1167 C_StrgWhlHeatingOpt 0 "Not Applied" 1 "Applied(steering wheel applied)" 2 "RESERVED" 3 "Invalid" ;
VAL_ 1167 C_StrgWhlHeatingSWInf 0 "Default" 1 "1step opt(On/Off)" 2 "2step opt(step1,step2,Off)" 3 "Invalid" ;
VAL_ 1167 ICU_BattAutoCutPreWrng 0 "No Warning" 1 "Warning" 2 "Not Used" 3 "Invalid" ;
VAL_ 1167 IGN_AutoOff_WarnSta_CLU 0 "No Warning" 1 "Power Off Warning" 2 "RESERVED" 3 "Error Indicator" ;
VAL_ 1167 PDC_BatPwrStateClassA 0 "Invalid" 1 "Low power condition for ClassA-load operation" 2 "High power condition for ClassA-load operation" 3 "RESERVED" ;
VAL_ 1167 PDC_BatPwrStateClassB 0 "Invalid" 1 "Low power condition for ClassB-load operation" 2 "High power condition for ClassB-load operation" 3 "RESERVED" ;
VAL_ 1167 PDC_BatPwrStateClassC 0 "Invalid" 1 "Low power condition for ClassC-load operation" 2 "High power condition for ClassC-load operation" 3 "RESERVED" ;
VAL_ 1167 PDC_BatPwrClassOpt 0 "Invalid" 1 "SOC type" 2 "Class type" 3 "RESERVED" ;
VAL_ 1167 PLBMAvailableState 0 "Invaild" 1 "PLBM Power is available" ;
VAL_ 1167 PDC_LeadAcidBatType 0 "Not Applied" 1 "CMF 35Ah" 2 "CMF 40Ah" 3 "CMF 45Ah" 4 "CMF 50Ah" 5 "CMF 60Ah" 6 "CMF 68Ah" 7 "CMF 70Ah" 8 "CMF 80Ah" 9 "CMF 90Ah" 10 "CMF 110Ah" 11 "MF 40Ah" 12 "MF 45Ah" 13 "MF 60Ah" 14 "MF 68Ah" 15 "MF 80Ah" 16 "MF 90Ah" 17 "MF 110Ah" 18 "AGM 60Ah" 19 "AGM 70Ah" 20 "AGM 80Ah" 21 "AGM 50Ah" 22 "AGM 105Ah" 23 "AGM 90Ah" 24 "EFB 50Ah" 25 "EFB 60Ah" 26 "EFB 70Ah" 27 "RESERVED" 28 "RESERVED" 29 "RESERVED" 30 "RESERVED" 31 "RESERVED" ;
VAL_ 1167 IGN_AutoOff_WarnSta 0 "No Warning" 1 "Power Off Warning" 2 "RESERVED" 3 "Error Indicator" ;
VAL_ 194 CF_LDW_OnOffEquip2NvalueSet 0 "Default" 1 "Off" 2 "On" 3 "Invalid" ;
VAL_ 194 CF_AVN_TrnkTlgtAutoWashModeSet 0 "Default" 1 "TrunkTailgate Auto Wash Mode Off" 2 "TrunkTailGate Auto Wash Mode On" 3 "Invalid" ;
VAL_ 194 CF_AVN_DrvArmRestHeatNValueSet 0 "Default" 1 "Off" 2 "On" 3 "Invalid" ;
VAL_ 194 CF_AVN_AstArmRestHeatNValueSet 0 "Default" 1 "Off" 2 "On" 3 "Invalid" ;
VAL_ 194 CF_AVN_RRArmRestHeatNValueSet 0 "Default" 1 "Off" 2 "On" 3 "Invalid" ;
VAL_ 194 AVN_HudContentsADAS 0 "Default" 1 "Off" 2 "On" 3 "Invalid" ;
VAL_ 194 CF_AVN_RLArmRestHeatNValueSet 0 "Default" 1 "Off" 2 "On" 3 "Invalid" ;
VAL_ 194 CF_AVN_AirSptStrNValue_VR 0 "Default" 1 "Normal" 2 "Intense" 3 "Invalid" ;
VAL_ 194 CF_AVN_AirSptTimeNValueSet_VR 0 "Default" 1 "Short" 2 "Normal" 3 "Long" 4 "RESERVED" 5 "RESERVED" 6 "RESERVED" 7 "Invalid" ;
VAL_ 194 CF_AVN_AirSptMode_VR 0 "Default" 1 "Off" 2 "Mode1" 3 "Mode2" 4 "Mode3" 5 "RESERVED" 6 "RESERVED" 7 "Invalid" ;
VAL_ 194 CF_AVN_MdLmpSpeechRecogNValueSet 0 "Default" 1 "FL" 2 "FR" 3 "RL" 4 "RR" 5 "TL" 6 "TR" 7 "Invalid" ;
VAL_ 194 AVN_HudContentsBCWUnderADAS 0 "Default" 1 "Off" 2 "On" 3 "Invalid" ;
VAL_ 194 CF_AVN_ISLA2NvalueSet 0 "Default" 1 "Off" 2 "Information" 3 "Warning" 4 "Assist" 5 "RESERVED" 6 "RESERVED" 7 "Invalid" ;
VAL_ 194 C_TeleRRMsgOpCmdIBOX_0 0 "Init" 1 "Seat Massage OFF" 2 "Seat Massage ON" 3 "Invalid" ;
VAL_ 194 C_TeleRLMsgOpCmdIBOX_0 0 "Init" 1 "Seat Massage OFF" 2 "Seat Massage ON" 3 "Invalid" ;
VAL_ 194 USM_AdasISLANACntryTglSet 0 "Default" 1 "Toggle" 2 "RESERVED" 3 "Invalid" ;
VAL_ 194 USM_AdasISLANACntry1Set 0 "Default" 1 "United States of America" 2 "Canada" 3 "RESERVED" 4 "RESERVED" 5 "RESERVED" 6 "RESERVED" 7 "RESERVED" 8 "RESERVED" 9 "RESERVED" 10 "RESERVED" 11 "RESERVED" 12 "RESERVED" 13 "RESERVED" 14 "RESERVED" 15 "Invalid" ;
VAL_ 194 CF_AVN_PMPDNvalueSet 0 "Default" 1 "Off" 2 "On" 3 "Invalid" ;
VAL_ 194 CF_AVN_LKAWrngVolNvalueSet_2 0 "Default" 1 "Off" 2 "On" 3 "Invalid" ;
VAL_ 194 CF_AVN_ActbolstersenNValue 0 "Default" 1 "Off" 2 "Standard" 3 "Sensitive" 4 "RESERVED" 5 "RESERVED" 6 "RESERVED" 7 "Invalid" ;
VAL_ 1166 RRMSS_OnOffBtn_AVN 0 "Default" 1 "Off" 2 "On" 3 "Invalid" ;
VAL_ 223 ALBCU_SmartCtrl_1h 0 "Default" 1 "Group1" 2 "Group2" 3 "Group3" 4 "Group4" 5 "Group5" 6 "Group6" 7 "Group7" 8 "Group8" 9 "Group9" 10 "General Group" 11 "Unused" 12 "Unused" 13 "Unused" 14 "Unused" 15 "Invalid" ;
VAL_ 223 ALBCU_SmartCtrl_2h 0 "Default" 1 "Group1" 2 "Group2" 3 "Group3" 4 "Group4" 5 "Group5" 6 "Group6" 7 "Group7" 8 "Group8" 9 "Group9" 10 "General Group" 11 "Unused" 12 "Unused" 13 "Unused" 14 "Unused" 15 "Invalid" ;
VAL_ 223 ALBCU_SmartCtrl_Status 0 "Default" 1 "Start" 2 "Finished" 3 "Stop" 4 "Unused" 5 "Unused" 6 "Unused" 7 "Invalid" ;
VAL_ 1171 RLPSM_SWVerMajor1 0 "0x0x0~0x7F:ASCII Code Value (HEX)" 127 "0x0x0~0x7F:ASCII Code Value (HEX)" ;
VAL_ 1171 RLPSM_SWVerMinor2 0 "0x0x0~0x7F:ASCII Code Value (HEX)" 127 "0x0x0~0x7F:ASCII Code Value (HEX)" ;
VAL_ 1171 RLPSM_RLLegRestPosition 0 "0x0x00~0xFE:POSITION" 254 "0x0x00~0xFE:POSITION" 255 "invalid" ;
VAL_ 1171 RLPSM_EsyAcsStpSta 0 "Off" 1 "On" 2 "Not Used" 3 "Error Indicator" ;
VAL_ 1171 RLPSM_EsyAcsGetOffSta 0 "Off" 1 "On" 2 "Not Used" 3 "Error Indicator" ;
VAL_ 1171 RLPSM_SWVerMinor1 0 "0x0x0~0x7F:ASCII Code Value (HEX)" 127 "0x0x0~0x7F:ASCII Code Value (HEX)" ;
VAL_ 1172 RRPSM_SWVerMajor1 0 "0x0x0~0x7F:ASCII Code Value (HEX)" 127 "0x0x0~0x7F:ASCII Code Value (HEX)" ;
VAL_ 1172 RRPSM_SWVerMinor2 0 "0x0x0~0x7F:ASCII Code Value (HEX)" 127 "0x0x0~0x7F:ASCII Code Value (HEX)" ;
VAL_ 1172 RRPSM_EsyAcsStpSta 0 "Off" 1 "On" 2 "Not Used" 3 "Error Indicator" ;
VAL_ 1172 RRPSM_EsyAcsGetOffSta 0 "Off" 1 "On" 2 "Not Used" 3 "Error Indicator" ;
VAL_ 1172 RRPSM_SWVerMinor1 0 "0x0x0~0x7F:ASCII Code Value (HEX)" 127 "0x0x0~0x7F:ASCII Code Value (HEX)" ;
VAL_ 1174 Drv_SHVU_SeatOptSta 0 "Init" 1 "Heater only 2step" 2 "Heater only 3step" 3 "Vent only 2step" 4 "Vent only 3step" 5 "Heater and Vent 2step" 6 "Heater and Vent 3step" 7 "Invalid" ;
VAL_ 1174 Drv_SHVU_HtSwHiIndSta 0 "Off(Initial Value)" 1 "On" 2 "RESERVED" 3 "Error Indicator" ;
VAL_ 1174 Drv_SHVU_HtSwMidIndSta 0 "Off(Initial Value)" 1 "On" 2 "RESERVED" 3 "Error Indicator" ;
VAL_ 1174 Drv_SHVU_HtSwLowIndSta 0 "Off(Initial Value)" 1 "On" 2 "RESERVED" 3 "Error Indicator" ;
VAL_ 1174 Drv_SHVU_VntSwHiIndSta 0 "Off(Initial Value)" 1 "On" 2 "RESERVED" 3 "Error Indicator" ;
VAL_ 1174 Drv_SHVU_VntSwMidIndSta 0 "Off(Initial Value)" 1 "On" 2 "RESERVED" 3 "Error Indicator" ;
VAL_ 1174 Drv_SHVU_VntSwLowIndSta 0 "Off(Initial Value)" 1 "On" 2 "RESERVED" 3 "Error Indicator" ;
VAL_ 1174 Drv_SHVU_HtBlcUSMSta 0 "Default" 1 "Normal" 2 "Back 1" 3 "Back 2" 4 "Back 3" 5 "Cush 1" 6 "Cush 2" 7 "Cush 3" 8 "Reserved" 9 "Reserved" 10 "Reserved" 11 "Reserved" 12 "Reserved" 13 "Reserved" 14 "Reserved" 15 "Invalid" ;
VAL_ 1174 Drv_SHVU_SeatHtOperSta 0 "Init" 1 "RESERVED" 2 "Heater & Vent OFF" 3 "Vent Low" 4 "Vent Mid" 5 "Vent High" 6 "Heater Low" 7 "Heater Mid" 8 "Heater High" 9 "RESERVED" 10 "RESERVED" 11 "RESERVED" 12 "RESERVED" 13 "RESERVED" 14 "RESERVED" 15 "Invalid" ;
VAL_ 1174 Drv_SHVU_LastModeOptSta 0 "Init(Default)" 1 "Not Applied" 2 "Applied" 3 "RESERVED" ;
VAL_ 1174 Drv_SHVU_HtSwHiIndSta_RHD 0 "Off(Initial Value)" 1 "On" 2 "RESERVED" 3 "Error Indicator" ;
VAL_ 1174 Drv_SHVU_HtSwMidIndSta_RHD 0 "Off(Initial Value)" 1 "On" 2 "RESERVED" 3 "Error Indicator" ;
VAL_ 1174 Drv_SHVU_HtSwLowIndSta_RHD 0 "Off(Initial Value)" 1 "On" 2 "RESERVED" 3 "Error Indicator" ;
VAL_ 1174 Drv_SHVU_VntSwHiIndSta_RHD 0 "Off(Initial Value)" 1 "On" 2 "RESERVED" 3 "Error Indicator" ;
VAL_ 1174 Drv_SHVU_VntSwMidIndSta_RHD 0 "Off(Initial Value)" 1 "On" 2 "RESERVED" 3 "Error Indicator" ;
VAL_ 1174 Drv_SHVU_VntSwLowIndSta_RHD 0 "Off(Initial Value)" 1 "On" 2 "RESERVED" 3 "Error Indicator" ;
VAL_ 1174 Drv_SHVU_HtBlcUSMSta_RHD 0 "Default" 1 "Normal" 2 "Back 1" 3 "Back 2" 4 "Back 3" 5 "Cush 1" 6 "Cush 2" 7 "Cush 3" 8 "Reserved" 9 "Reserved" 10 "Reserved" 11 "Reserved" 12 "Reserved" 13 "Reserved" 14 "Reserved" 15 "Invalid" ;
VAL_ 1179 Drv_SHVU_SeatEcoSta 0 "Off(Initial Value)" 1 "On" 2 "RESERVED" 3 "Error Indicator" ;
VAL_ 1179 SHVU_Drv_Beep1Sound 0 "Beep1 mode Off" 1 "Beep1 mode On" 2 "RESERVED" 3 "Invalid" ;
VAL_ 1179 SHVU_CtrlScreenDis 0 "Default" 1 "Screen Display On" 2 "RESERVED" 3 "Invalid" ;
VAL_ 1180 SHVU_Ast_Beep1Sound 0 "Beep1 mode Off" 1 "Beep1 mode On" 2 "RESERVED" 3 "Invalid" ;
VAL_ 1180 Ast_SHVU_SeatEcoSta 0 "Off(Initial Value)" 1 "On" 2 "RESERVED" 3 "Error Indicator" ;
VAL_ 208 RR_SHVU_DTCdisplay 0 "DTC is not exist(Fail is not exist)" 1 "IGN2 Fuse Open Detection" 2 "Switch Input Detection at Same Time" 3 "NTC/Heating wire Open Detection" 4 "NTC+/NTC- Terminal Short Detection" 5 "NTC+/Heater+ Terminal Short Detection" 6 "NTC+/Heater-, Heater+/Heater-, Heater+/NTC- Terminal Short Detection" 7 "NTC+/Heater- Wiring Short Detection" 8 "NTC+/Heater-, Heater+/Heater-, Heater+/NTC- Wiring Short Detection" 9 "Target Temperature Dissatisfied" 10 "Blower+/Blower- Short, Blower+/Blower Speed, Blower-/Blower Speed Wiring Short Detection" 11 "Blower+/Blower RPM, Blower-/Blower RPM, Blower Speed/Blower RPM Short Detection" 12 "Blower+, Blower-, Blower Speed Signal open Detection" 13 "Blower RPM signal Open Detection" 14 "0xE~0xFD:RESERVED" 253 "0xE~0xFD:RESERVED" 254 "No Display" 255 "Invalid" ;
VAL_ 208 RR_SHVU_DiagMode 0 "Default" 1 "DTC Mode" 2 "Normal Mode" 3 "Invalid" ;
VAL_ 1181 RL_SHVU_SeatEcoSta 0 "Off(Initial Value)" 1 "On" 2 "RESERVED" 3 "Error Indicator" ;
VAL_ 1182 RR_SHVU_SeatEcoSta 0 "Off(Initial Value)" 1 "On" 2 "RESERVED" 3 "Error Indicator" ;
VAL_ 1186 HU_CDMOpenCmd 0 "Default" 1 "CDM Open" 2 "CDM Close" 3 "Invalid" ;
VAL_ 1186 C_PreCrankReq 0 "Default" 1 "Req On" 2 "Not Support" 3 "Invalid" ;
VAL_ 1186 C_TeleAstSeatOpCmdIBOX 0 "Init" 1 "Unused" 2 "Seat Heat&Vent OFF" 3 "Seat_Vent_Low" 4 "Seat_Vent_Mid" 5 "Seat_Vent_High" 6 "Seat_Heat_Low" 7 "Seat_Heat_Mid" 8 "Seat_Heat_High" 9 "Unused" 10 "Unused" 11 "Unused" 12 "Unused" 13 "Unused" 14 "Unused" 15 "Invalid" ;
VAL_ 1186 C_TeleDrvSeatOpCmdIBOX 0 "Init" 1 "Unused" 2 "Seat Heat&Vent OFF" 3 "Seat_Vent_Low" 4 "Seat_Vent_Mid" 5 "Seat_Vent_High" 6 "Seat_Heat_Low" 7 "Seat_Heat_Mid" 8 "Seat_Heat_High" 9 "Unused" 10 "Unused" 11 "Unused" 12 "Unused" 13 "Unused" 14 "Unused" 15 "Invalid" ;
VAL_ 1186 C_TeleRRSeatOpCmdIBOX 0 "Init" 1 "Unused" 2 "Seat Heat&Vent OFF" 3 "Seat_Vent_Low" 4 "Seat_Vent_Mid" 5 "Seat_Vent_High" 6 "Seat_Heat_Low" 7 "Seat_Heat_Mid" 8 "Seat_Heat_High" 9 "Unused" 10 "Unused" 11 "Unused" 12 "Unused" 13 "Unused" 14 "Unused" 15 "Invalid" ;
VAL_ 1186 C_TeleRLSeatOpCmdIBOX 0 "Init" 1 "Unused" 2 "Seat Heat&Vent OFF" 3 "Seat_Vent_Low" 4 "Seat_Vent_Mid" 5 "Seat_Vent_High" 6 "Seat_Heat_Low" 7 "Seat_Heat_Mid" 8 "Seat_Heat_High" 9 "Unused" 10 "Unused" 11 "Unused" 12 "Unused" 13 "Unused" 14 "Unused" 15 "Invalid" ;
VAL_ 1185 C_AstWindowCmdAVN 0 "No action" 1 "Manual Down" 2 "Manual Up" 3 "25% Open" 4 "50%Open" 5 "Auto Down" 6 "Auto Up" 7 "15% Open" 8 "Unused" 9 "Unused" 10 "Unused" 11 "Unused" 12 "Unused" 13 "Unused" 14 "Unused" 15 "Invalid" ;
VAL_ 1185 C_RrDefoggerCmdAVN 0 "Off" 1 "On" 2 "Reserved" 3 "Invalid" ;
VAL_ 1185 C_RrBlindCmdAVN 0 "No Action" 1 "Blind Auto Open" 2 "Blind Auto Close" 3 "Invalid" ;
VAL_ 1185 C_RrGlassCmdAVN 0 "No Action" 1 "Glass Auto Open" 2 "Glass Auto Close" 3 "Invalid" ;
VAL_ 1185 C_RRWindowCmdAVN 0 "No action" 1 "Manual Down" 2 "Manual Up" 3 "25% Open" 4 "50% Open" 5 "Auto Down" 6 "Auto Up" 7 "15% Open" 8 "Unused" 9 "Unused" 10 "Unused" 11 "Unused" 12 "Unused" 13 "Unused" 14 "Unused" 15 "Invalid" ;
VAL_ 1185 C_RLWindowCmdAVN 0 "No action" 1 "Manual Down" 2 "Manual Up" 3 "25% Open" 4 "50% Open" 5 "Auto Down" 6 "Auto UP" 7 "15% Open" 8 "Unused" 9 "Unused" 10 "Unused" 11 "Unused" 12 "Unused" 13 "Unused" 14 "Unused" 15 "Invalid" ;
VAL_ 1185 C_BlindCmdAVN 0 "No Action" 1 "R_Blind Auto Open" 2 "R_Blind Auto Close" 3 "Stop" 4 "reserved" 5 "reserved" 6 "reserved" 7 "Invalid" ;
VAL_ 1185 C_GlassCmdAVN 0 "No Action" 1 "Glass Auto Open" 2 "Glass Auto Close" 3 "Glass Auto Tilt Up" 4 "Stop" 5 "reserved" 6 "reserved" 7 "Invalid" ;
VAL_ 1185 C_DrvWindowCmdAVN 0 "No action" 1 "Manual Down" 2 "Manual Up" 3 "25% Open" 4 "50% Open" 5 "Auto Down" 6 "Auto Up" 7 "15% Open" 8 "Unused" 9 "Unused" 10 "Unused" 11 "Unused" 12 "Unused" 13 "Unused" 14 "Unused" 15 "Invalid" ;
VAL_ 1185 C_PTGCNTLCmdAVN 0 "Close" 1 "Open" 2 "Reserved" 3 "Invalid" ;
